VERSION ""

NS_ :

BS_:
BU_:
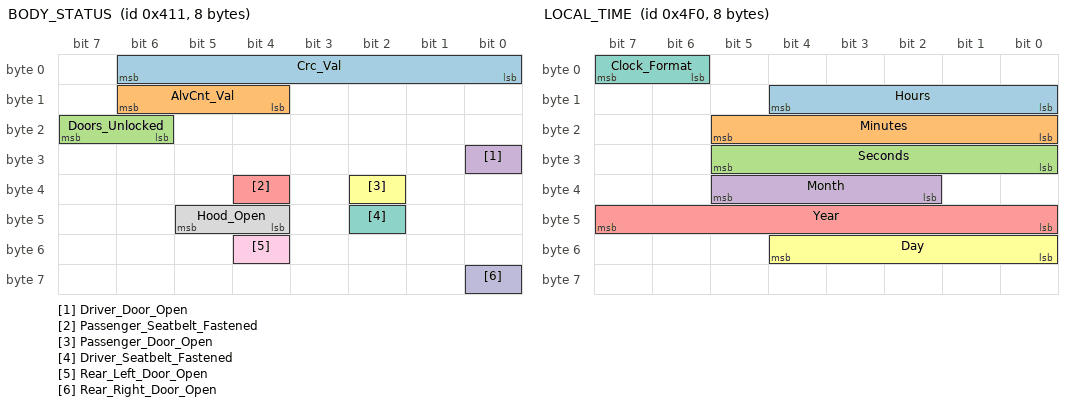
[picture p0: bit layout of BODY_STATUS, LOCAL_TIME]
BO_ 1041 BODY_STATUS: 8 Vector__XXX
   SG_ Crc_Val : 0|7@1+ (1,0) [0|127] "" Vector__XXX
   SG_ AlvCnt_Val : 12|3@1+ (1,0) [0|7] "" Vector__XXX
   SG_ Doors_Unlocked : 22|2@1+ (1,0) [0|3] "" Vector__XXX
   SG_ Driver_Door_Open : 24|1@1+ (1,0) [0|1] "" Vector__XXX
   SG_ Passenger_Seatbelt_Fastened : 36|1@1+ (1,0) [0|1] "" Vector__XXX
   SG_ Passenger_Door_Open : 34|1@1+ (1,0) [0|1] "" Vector__XXX
   SG_ Driver_Seatbelt_Fastened : 42|1@1+ (1,0) [0|1] "" Vector__XXX
   SG_ Hood_Open : 44|2@1+ (1,0) [0|3] "" Vector__XXX
   SG_ Rear_Left_Door_Open : 52|1@1+ (1,0) [0|1] "" Vector__XXX
   SG_ Rear_Right_Door_Open : 56|1@1+ (1,0) [0|1] "" Vector__XXX

BO_ 162 WHEEL_SPEEDS: 8 Vector__XXX
   SG_ Wheel_Speed_FL : 0|16@1+ (0.03125,0) [0|2047.97] "kph" Vector__XXX
   SG_ Wheel_Speed_FR : 16|16@1+ (0.03125,0) [0|2047.97] "kph" Vector__XXX
   SG_ Wheel_Speed_RL : 32|16@1+ (0.03125,0) [0|2047.97] "kph" Vector__XXX
   SG_ Wheel_Speed_RR : 48|16@1+ (0.03125,0) [0|2047.97] "kph" Vector__XXX

BO_ 428 CLUSTER_INFO_428: 8 Vector__XXX
   SG_ Speed_kph : 0|8@1+ (1,0) [0|255] "kph" Vector__XXX

BO_ 938 CHARGE_PORT_DOOR: 8 Vector__XXX
   SG_ Crc_Val : 0|12@1+ (1,0) [0|4095] "" Vector__XXX
   SG_ AlvCnt_Val : 12|8@1+ (1,0) [0|255] "" Vector__XXX
   SG_ Port_Open : 33|3@1+ (1,0) [0|7] "" Vector__XXX

BO_ 1044 TRUNK_STATUS: 8 Vector__XXX
   SG_ Crc_Val : 0|12@1+ (1,0) [0|4095] "" Vector__XXX
   SG_ AlvCnt_Val : 12|4@1+ (1,0) [0|15] "" Vector__XXX
   SG_ Trunk_Open : 24|6@1+ (1,0) [0|63] "" Vector__XXX

BO_ 763 BATTERY_INFO_763: 8 Vector__XXX
   SG_ Raw_BMS_State_Of_Charge : 32|8@1+ (0.25,0) [0|100] "%" Vector__XXX
   SG_ Cand_Volt_2FB_46 : 46|10@1+ (1,0) [0|1023] "V" Vector__XXX
   SG_ Cand_Volt_2FB_54 : 54|10@1+ (1,0) [0|1023] "V" Vector__XXX

BO_ 411 CHARGING_INFO: 8 Vector__XXX
   SG_ Charging_Current : 32|10@1+ (1,0) [0|1023] "A" Vector__XXX

BO_ 685 BMS_PRECOND_STATUS: 8 Vector__XXX
   SG_ Battery_Precond_State : 8|5@1+ (1,0) [0|31] "" Vector__XXX

BO_ 1261 NAV_PRECOND_STATUS: 8 Vector__XXX
   SG_ Precond_Request : 56|8@1+ (1,0) [0|255] "" Vector__XXX

BO_ 1042 REAR_LAMP_STATUS: 8 Vector__XXX
   SG_ Reverse_Lamp : 48|1@1+ (1,0) [0|1] "" Vector__XXX
   SG_ Brake_Lamp : 50|1@1+ (1,0) [0|1] "" Vector__XXX

BO_ 1077 POWER_CAN_STATUS: 8 Vector__XXX
   SG_ Crc_Val : 0|12@1+ (1,0) [0|4095] "" Vector__XXX
   SG_ AlvCnt_Val : 12|4@1+ (1,0) [0|15] "" Vector__XXX
   SG_ Power_State : 56|8@1+ (1,0) [0|255] "" Vector__XXX

BO_ 550 AMBIENT_TEMPERATURE: 8 Vector__XXX
   SG_ Outdoor_Temperature : 24|8@1+ (1,-40) [-40|215] "C" Vector__XXX

BO_ 551 ODOMETER: 8 Vector__XXX
   SG_ Odometer : 8|24@1+ (0.1,0) [0|1.67772e+06] "km" Vector__XXX
   SG_ Outdoor_Temperature_F : 50|8@1+ (0.5,-40) [-40|87.5] "F" Vector__XXX

BO_ 593 CLUSTER_WARNINGS: 8 Vector__XXX
   SG_ Crc_Val : 0|16@1+ (1,0) [0|65535] "" Vector__XXX
   SG_ AlvCnt_Val : 16|8@1+ (1,0) [0|255] "" Vector__XXX
   SG_ Rear_Defrost_State : 7|1@1+ (1,0) [0|1] "" Vector__XXX

BO_ 764 BATTERY_INFO_764: 8 Vector__XXX
   SG_ Battery_Current : 0|16@1- (0.1,0) [-3276.8|3276.7] "A" Vector__XXX
   SG_ Battery_Min_Temperature : 16|8@1- (1,0) [-128|127] "C" Vector__XXX
   SG_ Battery_Max_Temperature : 24|8@1- (1,0) [-128|127] "C" Vector__XXX
   SG_ Aux_Battery_Voltage : 48|8@1+ (0.1,0) [0|25.5] "V" Vector__XXX
   SG_ State_Of_Charge : 56|8@1+ (0.5,0) [0|100] "%" Vector__XXX

BO_ 1230 MEDIA_STATUS: 8 Vector__XXX
   SG_ Media_Source : 0|8@1+ (1,0) [0|255] "" Vector__XXX
   SG_ Media_Popup : 8|8@1+ (1,0) [0|255] "" Vector__XXX
   SG_ Track_Seconds : 32|8@1+ (1,0) [0|251] "s" Vector__XXX
   SG_ Track_Seconds_High : 40|8@1+ (1,0) [0|255] "" Vector__XXX

BO_ 843 LIGHT_STALK_STATUS: 8 Vector__XXX
   SG_ Headlight_Switch : 6|2@1+ (1,0) [0|3] "" Vector__XXX

BO_ 1096 STEERING_WHEEL_BUTTONS: 8 Vector__XXX
   SG_ Crc_Val : 0|8@1+ (1,0) [0|255] "" Vector__XXX
   SG_ AlvCnt_Val : 12|4@1+ (1,0) [0|15] "" Vector__XXX
   SG_ Steering_Wheel_Mode_Button : 22|2@1+ (1,0) [0|3] "" Vector__XXX
   SG_ Steering_Wheel_Speak_Button : 16|2@1+ (1,0) [0|3] "" Vector__XXX
   SG_ Steering_Wheel_Call_Button : 18|4@1+ (1,0) [0|15] "" Vector__XXX
   SG_ Steering_Wheel_Vol_Up_Button : 32|12@1+ (1,0) [0|4095] "" Vector__XXX
   SG_ Steering_Wheel_Vol_Down_Button : 30|2@1+ (1,0) [0|3] "" Vector__XXX
   SG_ Steering_Wheel_Mute_Button : 24|6@1+ (1,0) [0|63] "" Vector__XXX
   SG_ Steering_Wheel_Skip_Up_Button : 28|2@1+ (1,0) [0|3] "" Vector__XXX
   SG_ Steering_Wheel_Skip_Down_Button : 26|2@1+ (1,0) [0|3] "" Vector__XXX
   SG_ Steering_Wheel_Star_Button : 44|4@1+ (1,0) [0|15] "" Vector__XXX
   SG_ Steering_Wheel_Menu_Down_Button : 48|2@1+ (1,0) [0|3] "" Vector__XXX
   SG_ Steering_Wheel_Menu_Up_Button : 50|2@1+ (1,0) [0|3] "" Vector__XXX
   SG_ Steering_Wheel_Menu_Press_Button : 52|2@1+ (1,0) [0|3] "" Vector__XXX

BO_ 1141 PASSENGER_SEAT_HEATING: 8 Vector__XXX
   SG_ Passenger_Seat_Heating_Opt : 0|3@1+ (1,0) [0|7] "" Vector__XXX
   SG_ Passenger_Seat_Heating_Oper : 3|4@1+ (1,0) [0|15] "" Vector__XXX

BO_ 1174 DRIVER_SEAT_HEATING: 8 Vector__XXX
   SG_ Driver_Seat_Heating_Opt : 0|3@1+ (1,0) [0|7] "" Vector__XXX
   SG_ Driver_Seat_Heating_Oper : 3|4@1+ (1,0) [0|15] "" Vector__XXX

BO_ 706 MOTOR_TORQUE: 8 Vector__XXX
   SG_ Motor_Torque_Percent : 24|8@1- (1,0) [-128|127] "%" Vector__XXX

BO_ 795 CLIMATE_STATUS: 8 Vector__XXX
   SG_ Steering_Wheel_Heating_State : 7|1@1+ (1,0) [0|1] "" Vector__XXX
   SG_ Climate_Fan_Speed : 24|4@1+ (1,0) [0|15] "" Vector__XXX
   SG_ Climate_Airflow_Direction : 28|4@1+ (1,0) [0|15] "" Vector__XXX
   SG_ Climate_AC_State : 32|1@1+ (1,0) [0|1] "" Vector__XXX
   SG_ Climate_Recirculation_State : 34|1@1+ (1,0) [0|1] "" Vector__XXX

BO_ 896 CLIMATE_TEMPERATURE: 8 Vector__XXX
   SG_ Crc_Val : 0|16@1+ (1,0) [0|65535] "" Vector__XXX
   SG_ AlvCnt_Val : 16|8@1+ (1,0) [0|255] "" Vector__XXX
   SG_ Driver_Temp_C : 24|8@1+ (0.5,14) [14|32] "C" Vector__XXX
   SG_ Driver_Temp_F : 32|8@1+ (1,0) [0|255] "F" Vector__XXX
   SG_ Passenger_Temp_C : 40|8@1+ (0.5,14) [14|32] "C" Vector__XXX
   SG_ Passenger_Temp_F : 48|8@1+ (1,0) [0|255] "F" Vector__XXX

BO_ 782 CHARGING_POWER: 8 Vector__XXX
   SG_ Charging_Power_kW : 48|8@1+ (1,0) [0|255] "kW" Vector__XXX

BO_ 268 THERMAL_METRICS: 8 Vector__XXX
   SG_ Thermal_Metric_1 : 40|8@1+ (1,0) [0|255] "" Vector__XXX
   SG_ Thermal_Metric_2 : 48|8@1+ (1,0) [0|255] "" Vector__XXX

BO_ 567 BATTERY_INFO_567: 8 Vector__XXX
   SG_ Battery_Voltage : 40|16@1+ (0.1,0) [0|6553.5] "V" Vector__XXX

BO_ 54 DRIVE_MODE_STATUS: 8 Vector__XXX
   SG_ Ready : 28|1@1+ (1,0) [0|1] "" Vector__XXX
   SG_ Gear : 32|4@1+ (1,0) [0|15] "" Vector__XXX
   SG_ Drive_Mode : 58|3@1+ (1,0) [0|7] "" Vector__XXX

BO_ 695 CLUSTER_RANGE: 8 Vector__XXX
   SG_ Range : 0|10@1+ (1,0) [0|1023] "km" Vector__XXX

BO_ 818 CHARGE_TIME_ESTIMATE: 8 Vector__XXX
   SG_ Charge_Time_To_Limit : 0|16@1+ (1,0) [0|65535] "s" Vector__XXX
   SG_ Charge_Time_To_80 : 16|16@1+ (1,0) [0|65535] "s" Vector__XXX

BO_ 337 CHARGE_LIMITS: 8 Vector__XXX
   SG_ AC_Charge_Limit : 24|8@1+ (0.5,0) [0|127.5] "%" Vector__XXX
   SG_ DC_Charge_Limit : 32|8@1+ (0.5,0) [0|127.5] "%" Vector__XXX
   SG_ Battery_Max_Temperature_Copy : 56|8@1- (1,0) [-128|127] "C" Vector__XXX

BO_ 435 CABIN_TEMPERATURE: 8 Vector__XXX
   SG_ Cabin_Temperature : 40|8@1+ (0.5,-40) [-40|87.5] "C" Vector__XXX

BO_ 504 CHARGING_TIME: 8 Vector__XXX
   SG_ Charging_Time_To_Limit : 40|16@1+ (1,0) [0|65535] "min" Vector__XXX

BO_ 605 CANDIDATE_25D: 8 Vector__XXX
   SG_ Cand_Heater_Power_25D : 16|8@1+ (0.1,0) [0|25.5] "kW" Vector__XXX

BO_ 412 CHARGER_LIMITS: 8 Vector__XXX
   SG_ DC_Target_Voltage : 0|16@1+ (0.1,0) [0|6553.5] "V" Vector__XXX
   SG_ DC_Current_Limit : 16|8@1+ (0.1,0) [0|25.5] "A" Vector__XXX
   SG_ AC_Current_Limit : 32|8@1+ (0.1,0) [0|25.5] "A" Vector__XXX

BO_ 100 AUTO_HOLD_STATUS: 8 Vector__XXX
   SG_ Auto_Hold : 24|8@1+ (1,0) [0|255] "" Vector__XXX

BO_ 413 CHARGER_SESSION: 8 Vector__XXX
   SG_ Charger_Type : 16|8@1+ (1,0) [0|255] "" Vector__XXX
   SG_ DC_Sequence_Stage : 28|4@1+ (1,0) [0|15] "" Vector__XXX

BO_ 780 CHARGE_INLET: 8 Vector__XXX
   SG_ Proximity_Voltage : 32|8@1+ (0.1,0) [0|25.5] "V" Vector__XXX
   SG_ Plug_Connected : 40|1@1+ (1,0) [0|1] "" Vector__XXX

BO_ 806 CHARGING_STATUS: 8 Vector__XXX
   SG_ AC_Charger : 26|1@1+ (1,0) [0|1] "" Vector__XXX
   SG_ Charging : 32|1@1+ (1,0) [0|1] "" Vector__XXX

BO_ 603 CANDIDATE_25B: 8 Vector__XXX
   SG_ Cand_Curr_25B_50 : 50|10@1+ (1,0) [0|1023] "" Vector__XXX

BO_ 796 CANDIDATE_31C: 8 Vector__XXX
   SG_ Cand_Volt_31C_1 : 1|13@1+ (0.1,0) [0|819] "V" Vector__XXX

BO_ 338 BATTERY_TEMPERATURES_152: 8 Vector__XXX
   SG_ Battery_Min_Temperature_Copy : 0|8@1- (1,0) [-128|127] "C" Vector__XXX
   SG_ Cand_Battery_Temp_152_8 : 8|8@1- (1,0) [-128|127] "C" Vector__XXX
   SG_ Cand_Battery_Temp_152_16 : 16|8@1- (1,0) [-128|127] "C" Vector__XXX

BO_ 427 CLUSTER_DISPLAY_UNITS: 8 Vector__XXX
   SG_ Distance_Unit : 30|1@1+ (1,0) [0|1] "" Vector__XXX
   SG_ Display_Speed : 48|16@1+ (0.5,0) [0|32767.5] "" Vector__XXX

BO_ 738 REGEN_STATUS: 8 Vector__XXX
   SG_ Regen_Auto : 26|1@1+ (1,0) [0|1] "" Vector__XXX
   SG_ Regen_Level : 40|8@1+ (0.05,0) [0|12.75] "" Vector__XXX

BO_ 739 I_PEDAL_STATUS: 8 Vector__XXX
   SG_ I_Pedal : 57|1@1+ (1,0) [0|1] "" Vector__XXX

BO_ 929 TIRE_PRESSURES: 8 Vector__XXX
   SG_ Tire_Pressure_FL : 32|8@1+ (1,0) [0|255] "" Vector__XXX
   SG_ Tire_Pressure_FR : 40|8@1+ (1,0) [0|255] "" Vector__XXX
   SG_ Tire_Pressure_RL : 48|8@1+ (1,0) [0|255] "" Vector__XXX
   SG_ Tire_Pressure_RR : 56|8@1+ (1,0) [0|255] "" Vector__XXX

BO_ 930 TIRE_PRESSURE_UNIT: 8 Vector__XXX
   SG_ Tire_Pressure_Unit : 8|8@1+ (1,0) [0|255] "" Vector__XXX

BO_ 1264 LOCAL_TIME: 8 Vector__XXX
   SG_ Hours : 8|5@1+ (1,0) [0|23] "h" Vector__XXX
   SG_ Minutes : 16|6@1+ (1,0) [0|59] "min" Vector__XXX
   SG_ Seconds : 24|6@1+ (1,0) [0|59] "s" Vector__XXX
   SG_ Month : 34|4@1+ (1,0) [1|12] "" Vector__XXX
   SG_ Year : 40|8@1+ (1,2000) [2000|2255] "" Vector__XXX
   SG_ Day : 48|5@1+ (1,0) [1|31] "" Vector__XXX
   SG_ Clock_Format : 6|2@1+ (1,0) [0|3] "" Vector__XXX

BO_ 1259 LOCAL_TIME2: 8 Vector__XXX
   SG_ Weekday : 0|7@1+ (1,0) [0|127] "" Vector__XXX
   SG_ Hours : 11|5@1+ (1,0) [0|23] "h" Vector__XXX
   SG_ Minutes : 16|6@1+ (1,0) [0|59] "min" Vector__XXX
   SG_ Seconds : 24|6@1+ (1,0) [0|59] "s" Vector__XXX
   SG_ NEW_SIGNAL_3 : 39|1@0+ (1,0) [0|1] "" Vector__XXX

BO_ 1138 DISPLAY_SETTINGS_472: 8 Vector__XXX
   SG_ Efficiency_Unit : 38|2@1+ (1,0) [0|3] "" Vector__XXX

BO_ 56 POWER_MODE: 8 Vector__XXX
   SG_ Power_Mode : 0|4@1+ (1,0) [0|15] "" Vector__XXX

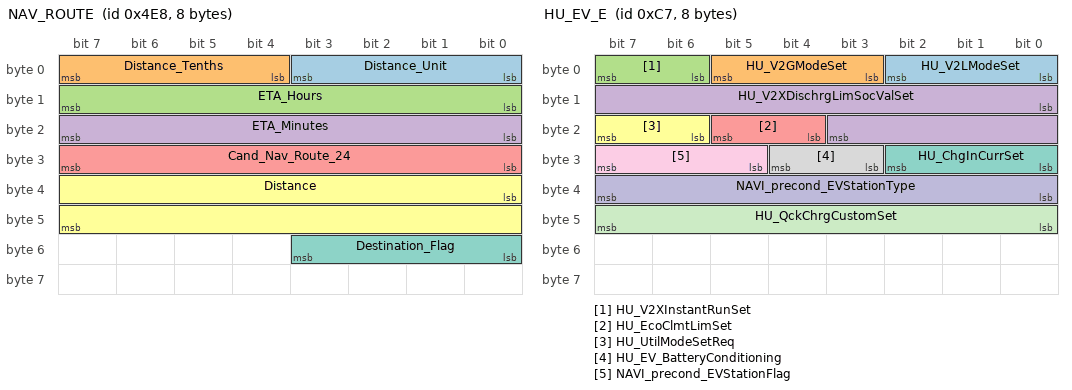
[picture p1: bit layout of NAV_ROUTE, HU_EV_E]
BO_ 1256 NAV_ROUTE: 8 Vector__XXX
   SG_ Distance_Unit : 0|4@1+ (1,0) [0|15] "" Vector__XXX
   SG_ Distance_Tenths : 4|4@1+ (1,0) [0|9] "" Vector__XXX
   SG_ ETA_Hours : 8|8@1+ (1,0) [0|23] "h" Vector__XXX
   SG_ ETA_Minutes : 16|8@1+ (1,0) [0|59] "min" Vector__XXX
   SG_ Cand_Nav_Route_24 : 24|8@1+ (1,0) [0|255] "" Vector__XXX
   SG_ Distance : 32|16@1+ (1,0) [0|65535] "" Vector__XXX
   SG_ Destination_Flag : 48|4@1+ (1,0) [0|15] "" Vector__XXX

BO_ 1228 NAV_GUIDANCE: 8 Vector__XXX
   SG_ Cand_Guidance_Type : 0|8@1+ (1,0) [0|255] "" Vector__XXX
   SG_ Cand_Compass_Heading : 24|8@1+ (1,0) [0|255] "" Vector__XXX

BO_ 418 CRUISE_STATUS: 8 Vector__XXX
   SG_ Cruise_State : 24|8@1+ (1,0) [0|255] "" Vector__XXX
   SG_ Cruise_Set_Speed : 32|8@1+ (1,0) [0|255] "kph" Vector__XXX

BO_ 1255 SPEED_LIMIT_4E7: 8 Vector__XXX
   SG_ Cand_Displayed_Speed_Limit : 56|8@1+ (1,0) [0|255] "kph" Vector__XXX

BO_ 1600 LANE_GUIDANCE: 8 Vector__XXX
   SG_ Cand_Junction_Distance : 0|16@1+ (1,0) [0|65535] "m" Vector__XXX
   SG_ Cand_Route_Active_640 : 56|8@1+ (1,0) [0|255] "" Vector__XXX

BO_ 199 HU_EV_E: 8 Vector__XXX
   SG_ HU_V2LModeSet : 0|3@1+ (1,0) [0|7] "" Vector__XXX
   SG_ HU_V2GModeSet : 3|3@1+ (1,0) [0|7] "" Vector__XXX
   SG_ HU_V2XInstantRunSet : 6|2@1+ (1,0) [0|3] "" Vector__XXX
   SG_ HU_V2XDischrgLimSocValSet : 8|12@1+ (1,0) [0|4095] "" Vector__XXX
   SG_ HU_EcoClmtLimSet : 20|2@1+ (1,0) [0|3] "" Vector__XXX
   SG_ HU_UtilModeSetReq : 22|2@1+ (1,0) [0|3] "" Vector__XXX
   SG_ HU_ChgInCurrSet : 24|3@1+ (1,0) [0|7] "" Vector__XXX
   SG_ HU_EV_BatteryConditioning : 27|2@1+ (1,0) [0|3] "" Vector__XXX
   SG_ NAVI_precond_EVStationFlag : 29|3@1+ (1,0) [0|7] "" Vector__XXX
   SG_ NAVI_precond_EVStationType : 32|8@1+ (1,0) [0|255] "" Vector__XXX
   SG_ HU_QckChrgCustomSet : 40|8@1+ (1,0) [0|255] "" Vector__XXX

BO_ 255 BCM_20_200ms: 8 Vector__XXX
   SG_ BCM_Crc20Val : 0|12@1+ (1,0) [0|4095] "" Vector__XXX
   SG_ BCM_AlvCnt20Val : 12|37@1+ (1,0) [0|1.37439e+11] "" Vector__XXX
   SG_ BCM_SafetyWdwOptTyp2 : 49|7@1+ (1,0) [0|127] "" Vector__XXX

BO_ 353 CCNC_0x161: 32 Vector__XXX
   SG_ CHECKSUM : 0|16@1+ (1,0) [0|65535] "" Vector__XXX
   SG_ COUNTER : 16|8@1+ (1,0) [0|255] "" Vector__XXX
   SG_ FCA_ICON : 24|3@1+ (1,0) [0|7] "" Vector__XXX
   SG_ FCA_ALT_ICON : 27|3@1+ (1,0) [0|7] "" Vector__XXX
   SG_ LKA_ICON : 30|3@1+ (1,0) [0|3] "" Vector__XXX
   SG_ HBA_ICON : 33|3@1+ (1,0) [0|7] "" Vector__XXX
   SG_ ZEROS_1 : 36|4@1+ (1,0) [0|15] "" Vector__XXX
   SG_ ZEROS_2 : 40|2@1+ (1,0) [0|3] "" Vector__XXX
   SG_ FCA_IMAGE : 42|3@1+ (1,0) [0|7] "" Vector__XXX
   SG_ ZEROS_3 : 45|3@1+ (1,0) [0|7] "" Vector__XXX
   SG_ ZEROS_4 : 48|3@1+ (1,0) [0|7] "" Vector__XXX
   SG_ BCA_LEFT : 51|3@1+ (1,0) [0|7] "" Vector__XXX
   SG_ BCA_RIGHT : 54|3@1+ (1,0) [0|7] "" Vector__XXX
   SG_ LCA_LEFT_ARROW : 57|3@1+ (1,0) [0|7] "" Vector__XXX
   SG_ LCA_RIGHT_ARROW : 60|3@1+ (1,0) [0|7] "" Vector__XXX
   SG_ ZEROS_5 : 63|1@0+ (1,0) [0|1] "" Vector__XXX
   SG_ CENTERLINE : 64|2@1+ (1,0) [0|3] "" Vector__XXX
   SG_ TARGET : 66|3@1+ (1,0) [0|7] "" Vector__XXX
   SG_ TARGET_DISTANCE : 69|11@1+ (0.1,0) [0|204.7] "m" Vector__XXX
   SG_ LANELINE_LEFT : 80|4@1+ (1,0) [0|15] "" Vector__XXX
   SG_ LANELINE_LEFT_POSITION : 84|6@1+ (1,0) [0|15] "" Vector__XXX
   SG_ LANELINE_RIGHT : 90|4@1+ (1,0) [0|15] "" Vector__XXX
   SG_ LANELINE_RIGHT_POSITION : 94|6@1+ (1,0) [0|3] "" Vector__XXX
   SG_ LANELINE_CURVATURE : 100|5@1- (1,15) [0|31] "" Vector__XXX
   SG_ LANE_HIGHLIGHT : 105|4@1+ (1,0) [0|15] "" Vector__XXX
   SG_ LANE_HIGHLIGHT_DISTANCE : 109|11@1+ (0.1,0) [0|204.7] "m" Vector__XXX
   SG_ LANE_LEFT : 120|3@1+ (1,0) [0|7] "" Vector__XXX
   SG_ LANE_RIGHT : 123|3@1+ (1,0) [0|7] "" Vector__XXX
   SG_ LANE_ZOOM : 126|2@1+ (1,0) [0|3] "" Vector__XXX
   SG_ ALERTS_1 : 128|6@1+ (1,0) [0|63] "" Vector__XXX
   SG_ ALERTS_2 : 134|5@1+ (1,0) [0|3] "" Vector__XXX
   SG_ ALERTS_3 : 139|5@1+ (1,0) [0|15] "" Vector__XXX
   SG_ ALERTS_4 : 144|8@1+ (1,0) [0|255] "" Vector__XXX
   SG_ ALERTS_5 : 152|5@1+ (1,0) [0|7] "" Vector__XXX
   SG_ MUTE : 157|3@1+ (1,0) [0|7] "" Vector__XXX
   SG_ SOUNDS_1 : 160|4@1+ (1,0) [0|3] "" Vector__XXX
   SG_ SOUNDS_2 : 164|4@1+ (1,0) [0|3] "" Vector__XXX
   SG_ SOUNDS_3 : 168|4@1+ (1,0) [0|15] "" Vector__XXX
   SG_ SOUNDS_4 : 172|3@1+ (1,0) [0|7] "" Vector__XXX
   SG_ ZEROS_6 : 175|1@0+ (1,0) [0|1] "" Vector__XXX
   SG_ ZEROS_7 : 176|5@1+ (1,0) [0|31] "" Vector__XXX
   SG_ SETSPEED_HUD : 181|3@1+ (1,0) [0|3] "" Vector__XXX
   SG_ DISTANCE_LEAD : 184|5@1+ (1,0) [0|31] "" Vector__XXX
   SG_ DISTANCE_CAR : 189|3@1+ (1,0) [0|7] "" Vector__XXX
   SG_ DISTANCE_SPACING : 192|4@1+ (1,0) [0|15] "" Vector__XXX
   SG_ DISTANCE : 196|4@1+ (1,0) [0|7] "" Vector__XXX
   SG_ SETSPEED_SPEED : 200|8@1+ (1,0) [0|255] "" Vector__XXX
   SG_ SETSPEED : 208|4@1+ (1,0) [0|3] "" Vector__XXX
   SG_ HDA_ICON : 212|4@1+ (1,0) [0|3] "" Vector__XXX
   SG_ SLA_ICON : 216|4@1+ (1,0) [0|15] "" Vector__XXX
   SG_ NAV_ICON : 220|4@1+ (1,0) [0|3] "" Vector__XXX
   SG_ LFA_ICON : 224|4@1+ (1,0) [0|3] "" Vector__XXX
   SG_ LCA_LEFT_ICON : 228|4@1+ (1,0) [0|15] "" Vector__XXX
   SG_ LCA_RIGHT_ICON : 232|4@1+ (1,0) [0|15] "" Vector__XXX
   SG_ BACKGROUND : 236|4@1+ (1,0) [0|15] "" Vector__XXX
   SG_ DAW_ICON : 240|3@1+ (1,0) [0|7] "" Vector__XXX
   SG_ CAR_CIRCLE : 243|3@1+ (1,0) [0|7] "" Vector__XXX
   SG_ ZEROS_8 : 246|2@1+ (1,0) [0|3] "" Vector__XXX
   SG_ ZEROS_9 : 248|8@1+ (1,0) [0|255] "" Vector__XXX

BO_ 354 CCNC_0x162: 32 Vector__XXX
   SG_ CHECKSUM : 0|16@1+ (1,0) [0|65535] "" Vector__XXX
   SG_ COUNTER : 16|8@1+ (1,0) [0|255] "" Vector__XXX
   SG_ COUNTRY : 24|4@1+ (1,0) [0|7] "" Vector__XXX
   SG_ SPEEDLIMIT_FLASH : 28|4@1+ (1,0) [0|15] "" Vector__XXX
   SG_ SPEEDLIMIT : 32|8@1+ (1,0) [0|255] "" Vector__XXX
   SG_ SIGNS : 40|8@1+ (1,0) [0|15] "" Vector__XXX
   SG_ SPEEDLIMIT_WEATHER : 48|4@1+ (1,0) [0|15] "" Vector__XXX
   SG_ VIBRATE : 52|3@1+ (1,0) [0|7] "" Vector__XXX
   SG_ ZEROS_1 : 55|1@0+ (1,0) [0|1] "" Vector__XXX
   SG_ ZEROS_2 : 56|8@1+ (1,0) [0|255] "" Vector__XXX
   SG_ LEAD : 64|5@1+ (1,0) [0|31] "" Vector__XXX
   SG_ LEAD_DISTANCE : 69|11@1+ (0.1,0) [0|204.7] "m" Vector__XXX
   SG_ LEAD_LATERAL : 80|7@1+ (0.1,0) [0|127] "m" Vector__XXX
   SG_ ZEROS_3 : 87|1@0+ (1,0) [0|1] "" Vector__XXX
   SG_ LEAD_ALT : 88|5@1+ (1,0) [0|31] "" Vector__XXX
   SG_ LEAD_ALT_DISTANCE : 93|11@1+ (0.1,0) [0|204.7] "m" Vector__XXX
   SG_ LEAD_ALT_LATERAL : 104|7@1+ (0.1,0) [0|127] "m" Vector__XXX
   SG_ ZEROS_4 : 111|1@0+ (1,0) [0|1] "" Vector__XXX
   SG_ LEAD_LEFT : 112|5@1+ (1,0) [0|31] "" Vector__XXX
   SG_ LEAD_LEFT_DISTANCE : 117|11@1+ (0.1,0) [0|204.7] "m" Vector__XXX
   SG_ LEAD_LEFT_LATERAL : 128|7@1+ (0.1,0) [0|127] "m" Vector__XXX
   SG_ ZEROS_5 : 135|1@0+ (1,0) [0|1] "" Vector__XXX
   SG_ LEAD_RIGHT : 136|5@1+ (1,0) [0|31] "" Vector__XXX
   SG_ LEAD_RIGHT_DISTANCE : 141|11@1+ (0.1,0) [0|204.7] "m" Vector__XXX
   SG_ LEAD_RIGHT_LATERAL : 152|7@1+ (0.1,0) [0|127] "m" Vector__XXX
   SG_ ZEROS_6 : 159|1@0+ (1,0) [0|1] "" Vector__XXX
   SG_ ZEROS_7 : 162|3@0+ (1,0) [0|7] "" Vector__XXX
   SG_ LEAD_LEFT_REAR_STATUS : 167|5@0+ (1,0) [0|31] "" Vector__XXX
   SG_ LEAD_LEFT_REAR_DISTANCE : 175|8@0+ (0.1,0) [0|255] "m" Vector__XXX
   SG_ LEAD_LEFT_REAR_LATERAL : 182|7@0+ (0.1,0) [0|127] "m" Vector__XXX
   SG_ ZEROS_8 : 183|1@0+ (1,0) [0|1] "" Vector__XXX
   SG_ ZEROS_9 : 191|8@0+ (1,0) [0|255] "" Vector__XXX
   SG_ LEAD_RIGHT_REAR_STATUS : 196|5@0+ (1,0) [0|31] "" Vector__XXX
   SG_ LEAD_RIGHT_REAR_DISTANCE : 197|8@1+ (0.1,0) [0|255] "m" Vector__XXX
   SG_ LEAD_RIGHT_REAR_LATERAL : 205|7@1+ (0.1,0) [0|127] "m" Vector__XXX
   SG_ ZEROS_10 : 212|1@0+ (1,0) [0|1] "" Vector__XXX
   SG_ FAULT_FSS : 213|3@1+ (1,0) [0|7] "" Vector__XXX
   SG_ FAULT_FCA : 216|3@1+ (1,0) [0|7] "" Vector__XXX
   SG_ FAULT_LSS : 219|3@1+ (1,0) [0|7] "" Vector__XXX
   SG_ FAULT_SLA : 222|3@1+ (1,0) [0|7] "" Vector__XXX
   SG_ FAULT_DAW : 225|3@1+ (1,0) [0|7] "" Vector__XXX
   SG_ FAULT_HBA : 228|3@1+ (1,0) [0|7] "" Vector__XXX
   SG_ FAULT_SCC : 231|3@1+ (1,0) [0|7] "" Vector__XXX
   SG_ FAULT_LFA : 234|3@1+ (1,0) [0|7] "" Vector__XXX
   SG_ FAULT_HDA : 237|3@1+ (1,0) [0|7] "" Vector__XXX
   SG_ FAULT_LCA : 240|3@1+ (1,0) [0|7] "" Vector__XXX
   SG_ FAULT_HDP : 243|3@1+ (1,0) [0|7] "" Vector__XXX
   SG_ FAULT_DAS : 246|3@1+ (1,0) [0|7] "" Vector__XXX
   SG_ FAULT_ESS : 249|3@1+ (1,0) [0|7] "" Vector__XXX
   SG_ ZEROS_11 : 252|4@1+ (1,0) [0|15] "" Vector__XXX

BO_ 438 CAM_0x1b6: 32 Vector__XXX
   SG_ CHECKSUM : 0|16@1+ (1,0) [0|65535] "" Vector__XXX
   SG_ COUNTER : 16|8@1+ (1,0) [0|255] "" Vector__XXX

BO_ 439 CAM_0x1b7: 32 Vector__XXX
   SG_ CHECKSUM : 0|16@1+ (1,0) [0|65535] "" Vector__XXX
   SG_ COUNTER : 16|8@1+ (1,0) [0|255] "" Vector__XXX

BO_ 440 CAM_0x1b8: 32 Vector__XXX
   SG_ CHECKSUM : 0|16@1+ (1,0) [0|65535] "" Vector__XXX
   SG_ COUNTER : 16|8@1+ (1,0) [0|255] "" Vector__XXX

BO_ 441 CAM_0x1b9: 32 Vector__XXX
   SG_ CHECKSUM : 0|16@1+ (1,0) [0|65535] "" Vector__XXX
   SG_ COUNTER : 16|8@1+ (1,0) [0|255] "" Vector__XXX

BO_ 507 CAM_0x1fb: 32 Vector__XXX
   SG_ CHECKSUM : 0|16@1+ (1,0) [0|65535] "" Vector__XXX
   SG_ COUNTER : 16|8@1+ (1,0) [0|255] "" Vector__XXX

BO_ 599 RRPSM_02_00ms: 8 Vector__XXX
   SG_ RR_SHVU_SeatOptSta : 0|3@1+ (1,0) [0|7] "" Vector__XXX
   SG_ C_RH_Folding_SW : 2|2@1+ (1,0) [0|3] "" Vector__XXX
   SG_ RR_SHVU_SeatHtOperSta : 3|5@1+ (1,0) [0|31] "" Vector__XXX
   SG_ C_LH_Unfolding_SW : 4|2@1+ (1,0) [0|3] "" Vector__XXX
   SG_ C_LH_Folding_SW : 6|2@1+ (1,0) [0|3] "" Vector__XXX
   SG_ RRPSM_RearModeWngDis : 8|6@1+ (1,0) [0|63] "" Vector__XXX
   SG_ RRIMS_AMPBzrReq : 14|2@1+ (1,0) [0|3] "" Vector__XXX

BO_ 689 ADAS_CMD_34_100ms: 10 Vector__XXX
   SG_ ADAS_CMD_Crc34Val : 0|16@1+ (1,0) [0|65535] "" Vector__XXX
   SG_ ADAS_CMD_AlvCnt34Val : 16|8@1+ (1,0) [0|255] "" Vector__XXX
   SG_ HDP_RDD_WarnSta : 24|3@1+ (1,0) [0|7] "" Vector__XXX
   SG_ HDP_RDD_LongAsstCtrlSta : 27|2@1+ (1,0) [0|3] "" Vector__XXX
   SG_ HDP_RDD_HzrdLmpReqSta : 29|3@1+ (1,0) [0|7] "" Vector__XXX
   SG_ HDP_RDD_ACIActvDispSta : 32|40@1+ (1,0) [0|1099511627775] "" Vector__XXX
   SG_ HDP_RDD_EMStbltActvReqSta : 72|8@1+ (1,0) [0|255] "" Vector__XXX

BO_ 827 TP_HU_IAU: 8 Vector__XXX
   SG_ TP_HU_IAU_Byte0 : 0|8@1+ (1,0) [0|255] "" Vector__XXX
   SG_ TP_HU_IAU_Byte1 : 8|8@1+ (1,0) [0|255] "" Vector__XXX
   SG_ TP_HU_IAU_Byte2 : 16|8@1+ (1,0) [0|255] "" Vector__XXX
   SG_ TP_HU_IAU_Byte3 : 24|8@1+ (1,0) [0|255] "" Vector__XXX
   SG_ TP_HU_IAU_Byte4 : 32|8@1+ (1,0) [0|255] "" Vector__XXX
   SG_ TP_HU_IAU_Byte5 : 40|8@1+ (1,0) [0|255] "" Vector__XXX
   SG_ TP_HU_IAU_Byte6 : 48|8@1+ (1,0) [0|255] "" Vector__XXX
   SG_ TP_HU_IAU_Byte7 : 56|8@1+ (1,0) [0|255] "" Vector__XXX

BO_ 828 TP_IAU_HU: 8 Vector__XXX
   SG_ TP_IAU_HU_Byte0 : 0|8@1+ (1,0) [0|255] "" Vector__XXX
   SG_ TP_IAU_HU_Byte1 : 8|8@1+ (1,0) [0|255] "" Vector__XXX
   SG_ TP_IAU_HU_Byte2 : 16|8@1+ (1,0) [0|255] "" Vector__XXX
   SG_ TP_IAU_HU_Byte3 : 24|8@1+ (1,0) [0|255] "" Vector__XXX
   SG_ TP_IAU_HU_Byte4 : 32|8@1+ (1,0) [0|255] "" Vector__XXX
   SG_ TP_IAU_HU_Byte5 : 40|8@1+ (1,0) [0|255] "" Vector__XXX
   SG_ TP_IAU_HU_Byte6 : 48|8@1+ (1,0) [0|255] "" Vector__XXX
   SG_ TP_IAU_HU_Byte7 : 56|8@1+ (1,0) [0|255] "" Vector__XXX

BO_ 895 GATEWAY_STS_100ms: 8 Vector__XXX
   SG_ GATEWAY_HS_D_STS : 22|2@1+ (1,0) [0|3] "" Vector__XXX

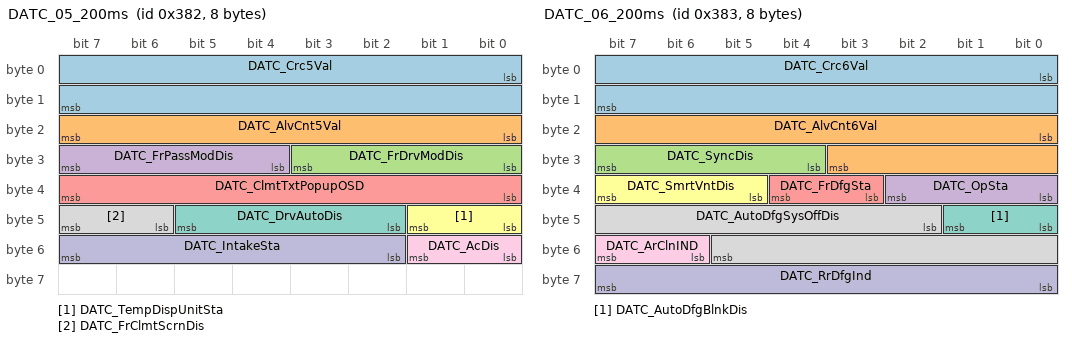
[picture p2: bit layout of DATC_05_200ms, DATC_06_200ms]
BO_ 898 DATC_05_200ms: 8 Vector__XXX
   SG_ DATC_Crc5Val : 0|16@1+ (1,0) [0|65535] "" Vector__XXX
   SG_ DATC_AlvCnt5Val : 16|8@1+ (1,0) [0|255] "" Vector__XXX
   SG_ DATC_FrDrvModDis : 24|4@1+ (1,0) [0|15] "" Vector__XXX
   SG_ DATC_FrPassModDis : 28|4@1+ (1,0) [0|15] "" Vector__XXX
   SG_ DATC_ClmtTxtPopupOSD : 32|8@1+ (1,0) [0|255] "" Vector__XXX
   SG_ DATC_TempDispUnitSta : 40|2@1+ (1,0) [0|3] "" Vector__XXX
   SG_ DATC_DrvAutoDis : 42|4@1+ (1,0) [0|15] "" Vector__XXX
   SG_ DATC_FrClmtScrnDis : 46|2@1+ (1,0) [0|3] "" Vector__XXX
   SG_ DATC_AcDis : 48|2@1+ (1,0) [0|3] "" Vector__XXX
   SG_ DATC_IntakeSta : 50|6@1+ (1,0) [0|63] "" Vector__XXX

BO_ 899 DATC_06_200ms: 8 Vector__XXX
   SG_ DATC_Crc6Val : 0|16@1+ (1,0) [0|65535] "" Vector__XXX
   SG_ DATC_AlvCnt6Val : 16|12@1+ (1,0) [0|4095] "" Vector__XXX
   SG_ DATC_SyncDis : 28|4@1+ (1,0) [0|15] "" Vector__XXX
   SG_ DATC_OpSta : 32|3@1+ (1,0) [0|7] "" Vector__XXX
   SG_ DATC_FrDfgSta : 35|2@1+ (1,0) [0|3] "" Vector__XXX
   SG_ DATC_SmrtVntDis : 37|3@1+ (1,0) [0|7] "" Vector__XXX
   SG_ DATC_AutoDfgBlnkDis : 40|2@1+ (1,0) [0|3] "" Vector__XXX
   SG_ DATC_AutoDfgSysOffDis : 42|12@1+ (1,0) [0|4095] "" Vector__XXX
   SG_ DATC_ArClnIND : 54|2@1+ (1,0) [0|3] "" Vector__XXX
   SG_ DATC_RrDfgInd : 56|8@1+ (1,0) [0|255] "" Vector__XXX

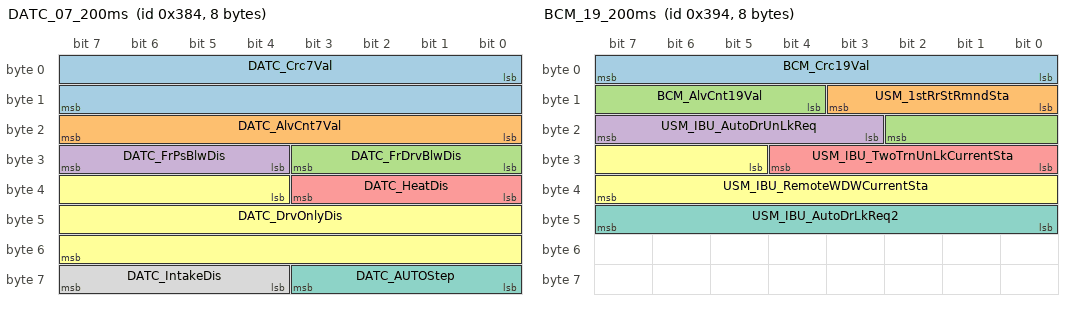
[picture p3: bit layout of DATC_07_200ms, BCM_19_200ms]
BO_ 900 DATC_07_200ms: 8 Vector__XXX
   SG_ DATC_Crc7Val : 0|16@1+ (1,0) [0|65535] "" Vector__XXX
   SG_ DATC_AlvCnt7Val : 16|8@1+ (1,0) [0|255] "" Vector__XXX
   SG_ DATC_FrDrvBlwDis : 24|4@1+ (1,0) [0|15] "" Vector__XXX
   SG_ DATC_FrPsBlwDis : 28|4@1+ (1,0) [0|15] "" Vector__XXX
   SG_ DATC_HeatDis : 32|4@1+ (1,0) [0|15] "" Vector__XXX
   SG_ DATC_DrvOnlyDis : 36|20@1+ (1,0) [0|1.04858e+06] "" Vector__XXX
   SG_ DATC_AUTOStep : 56|4@1+ (1,0) [0|15] "" Vector__XXX
   SG_ DATC_IntakeDis : 60|4@1+ (1,0) [0|15] "" Vector__XXX

BO_ 902 PSM_02_200ms: 8 Vector__XXX
   SG_ PSM_DrvStSldFwdDis : 0|2@1+ (1,0) [0|3] "" Vector__XXX
   SG_ PSM_DrvStSldBckwdDis : 2|2@1+ (1,0) [0|3] "" Vector__XXX
   SG_ PSM_DrvStReclneFwdDis : 4|2@1+ (1,0) [0|3] "" Vector__XXX
   SG_ PSM_DrvStReclneBckwdDis : 6|2@1+ (1,0) [0|3] "" Vector__XXX
   SG_ PSM_IMSOptTyp : 8|16@1+ (1,0) [0|65535] "" Vector__XXX
   SG_ PSM_DrvStTiltDnDis : 10|2@1+ (1,0) [0|3] "" Vector__XXX
   SG_ PSM_DrvStHghtUpDis : 12|2@1+ (1,0) [0|3] "" Vector__XXX
   SG_ PSM_DrvStHghtDnDis : 14|2@1+ (1,0) [0|3] "" Vector__XXX
   SG_ PSM_DrvStCushExtBckwdDis : 16|2@1+ (1,0) [0|3] "" Vector__XXX
   SG_ PSM_DrvStCushExtFwdDis : 18|2@1+ (1,0) [0|3] "" Vector__XXX
   SG_ PSM_DrvStHdRstUpDis : 20|2@1+ (1,0) [0|3] "" Vector__XXX
   SG_ PSM_DrvStHdRstDnDis : 22|2@1+ (1,0) [0|3] "" Vector__XXX
   SG_ SmrtIMS_StatureRspVal : 24|4@1+ (1,0) [0|15] "" Vector__XXX
   SG_ PSM_DrvStHdRstBckwdDis : 26|6@1+ (1,0) [0|63] "" Vector__XXX
   SG_ SmrtIMS_SeatedHghtRspVal : 28|4@1+ (1,0) [0|15] "" Vector__XXX
   SG_ SmrtIMS_WghtRspVal : 32|4@1+ (1,0) [0|15] "" Vector__XXX
   SG_ PSM_DrvStLmbrLoDis : 34|2@1+ (1,0) [0|3] "" Vector__XXX
   SG_ SmartIMS_DisReq : 36|4@1+ (1,0) [0|15] "" Vector__XXX
   SG_ PSM_DrvStLmbrUpDis : 38|2@1+ (1,0) [0|3] "" Vector__XXX
   SG_ SmrtIMS_ExitSta : 40|3@1+ (1,0) [0|7] "" Vector__XXX
   SG_ PSM_DrvStBlstrInfDis : 42|6@1+ (1,0) [0|63] "" Vector__XXX
   SG_ PSM_DrvStRlxTiltUpDis : 43|2@1+ (1,0) [0|3] "" Vector__XXX
   SG_ PSM_DrvStRlxTiltDnDis : 45|2@1+ (1,0) [0|3] "" Vector__XXX
   SG_ PSM_DrvStLegUpDis : 47|2@1+ (1,0) [0|3] "" Vector__XXX
   SG_ PSM_DrvStLegDnDis : 49|7@1+ (1,0) [0|127] "" Vector__XXX

BO_ 903 APSU_03_200ms_APSU: 8 Vector__XXX
   SG_ PSM_LmbrSigSrcTyp : 44|4@1+ (1,0) [0|15] "" Vector__XXX

BO_ 904 PSM_04_200ms: 8 Vector__XXX
   SG_ PSM_DrvReclinePosition : 0|8@1+ (1,0) [0|255] "" Vector__XXX
   SG_ PSM_EsyAcsGetOnSta : 8|2@1+ (1,0) [0|3] "" Vector__XXX
   SG_ PSM_EsyAcsGetOffSta : 10|2@1+ (1,0) [0|3] "" Vector__XXX
   SG_ PSM_EsyAcsStpSta : 12|4@1+ (1,0) [0|15] "" Vector__XXX
   SG_ RRPSS_L_StSldFwdMvBtn : 16|0@1+ (1,0) [0|0] "" Vector__XXX
   SG_ RRPSS_L_StSldBwdMvBtn : 18|0@1+ (1,0) [0|0] "" Vector__XXX
   SG_ RRPSS_L_StRclFwdMvBtn : 20|0@1+ (1,0) [0|0] "" Vector__XXX
   SG_ RRPSS_L_StRclBwdMvBtn : 22|0@1+ (1,0) [0|0] "" Vector__XXX
   SG_ PSM_SWVerMinor1 : 24|8@1+ (1,0) [0|255] "" Vector__XXX
   SG_ RRPSS_L_StTltUpMvBtn : 28|0@1+ (1,0) [0|0] "" Vector__XXX
   SG_ RRPSS_L_StTltDnMvBtn : 30|0@1+ (1,0) [0|0] "" Vector__XXX
   SG_ RRPSS_L_StHRestUpMvBtn : 32|0@1+ (1,0) [0|0] "" Vector__XXX
   SG_ RRPSS_L_StHRestDnMvBtn : 34|0@1+ (1,0) [0|0] "" Vector__XXX
   SG_ RRPSS_L_StHRestFwdMvBtn : 36|0@1+ (1,0) [0|0] "" Vector__XXX
   SG_ RRPSS_L_StHRestBwdMvBtn : 38|0@1+ (1,0) [0|0] "" Vector__XXX
   SG_ RRPSS_L_StLegRestUpBtn : 40|0@1+ (1,0) [0|0] "" Vector__XXX
   SG_ RRPSS_L_StLegRestDnBtn : 42|0@1+ (1,0) [0|0] "" Vector__XXX
   SG_ PSM_DrvHeightPosition : 48|8@1+ (1,0) [0|255] "" Vector__XXX
   SG_ PSM_DrvSlidePosition : 56|8@1+ (1,0) [0|255] "" Vector__XXX

BO_ 916 BCM_19_200ms: 8 Vector__XXX
   SG_ BCM_Crc19Val : 0|8@1+ (1,0) [0|255] "" Vector__XXX
   SG_ USM_1stRrStRmndSta : 8|4@1+ (1,0) [0|15] "" Vector__XXX
   SG_ BCM_AlvCnt19Val : 12|7@1+ (1,0) [0|127] "" Vector__XXX
   SG_ USM_IBU_AutoDrUnLkReq : 19|5@1+ (1,0) [0|31] "" Vector__XXX
   SG_ USM_IBU_TwoTrnUnLkCurrentSta : 24|5@1+ (1,0) [0|31] "" Vector__XXX
   SG_ USM_IBU_RemoteWDWCurrentSta : 29|11@1+ (1,0) [0|2047] "" Vector__XXX
   SG_ USM_IBU_AutoDrLkReq2 : 40|8@1+ (1,0) [0|255] "" Vector__XXX

BO_ 942 HU_AMP_E_942: 8 Vector__XXX
   SG_ AMP_Beep1VolumeStep_DATC : 0|8@1+ (1,0) [0|255] "" Vector__XXX
   SG_ AMP_SPDIF_OutputCh_Select : 8|16@1+ (1,0) [0|65535] "" Vector__XXX
   SG_ AMP_Analog_OutputCh_Select : 24|16@1+ (1,0) [0|65535] "" Vector__XXX
   SG_ AMP_Beep1_OutputCh_Select : 40|16@1+ (1,0) [0|65535] "" Vector__XXX
   SG_ AMP_Beep1KBDVolumeStep : 56|8@1+ (1,0) [0|255] "" Vector__XXX

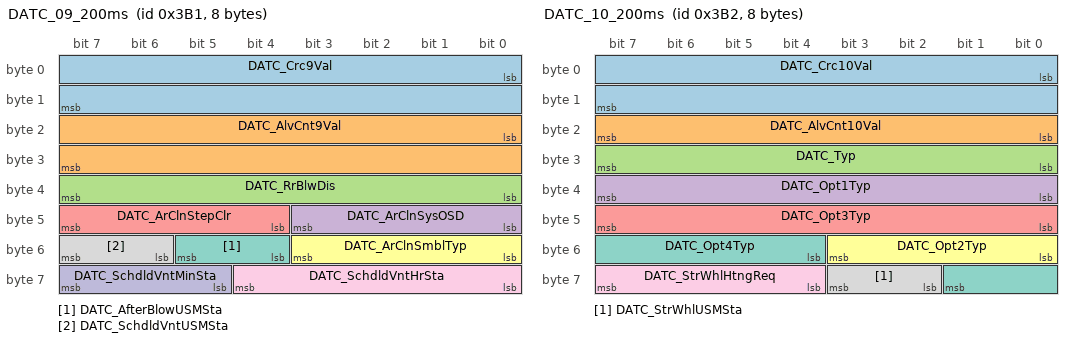
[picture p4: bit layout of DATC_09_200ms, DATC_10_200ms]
BO_ 945 DATC_09_200ms: 8 Vector__XXX
   SG_ DATC_Crc9Val : 0|16@1+ (1,0) [0|65535] "" Vector__XXX
   SG_ DATC_AlvCnt9Val : 16|16@1+ (1,0) [0|65535] "" Vector__XXX
   SG_ DATC_RrBlwDis : 32|8@1+ (1,0) [0|255] "" Vector__XXX
   SG_ DATC_ArClnSysOSD : 40|4@1+ (1,0) [0|15] "" Vector__XXX
   SG_ DATC_ArClnStepClr : 44|4@1+ (1,0) [0|15] "" Vector__XXX
   SG_ DATC_ArClnSmblTyp : 48|4@1+ (1,0) [0|15] "" Vector__XXX
   SG_ DATC_AfterBlowUSMSta : 52|2@1+ (1,0) [0|3] "" Vector__XXX
   SG_ DATC_SchdldVntUSMSta : 54|2@1+ (1,0) [0|3] "" Vector__XXX
   SG_ DATC_SchdldVntHrSta : 56|5@1+ (1,0) [0|31] "" Vector__XXX
   SG_ DATC_SchdldVntMinSta : 61|3@1+ (1,0) [0|7] "" Vector__XXX

BO_ 946 DATC_10_200ms: 8 Vector__XXX
   SG_ DATC_Crc10Val : 0|16@1+ (1,0) [0|65535] "" Vector__XXX
   SG_ DATC_AlvCnt10Val : 16|8@1+ (1,0) [0|255] "" Vector__XXX
   SG_ DATC_Typ : 24|8@1+ (1,0) [0|255] "" Vector__XXX
   SG_ DATC_Opt1Typ : 32|8@1+ (1,0) [0|255] "" Vector__XXX
   SG_ DATC_Opt3Typ : 40|8@1+ (1,0) [0|255] "" Vector__XXX
   SG_ DATC_Opt2Typ : 48|4@1+ (1,0) [0|15] "" Vector__XXX
   SG_ DATC_Opt4Typ : 52|6@1+ (1,0) [0|63] "" Vector__XXX
   SG_ DATC_StrWhlUSMSta : 58|2@1+ (1,0) [0|3] "" Vector__XXX
   SG_ DATC_StrWhlHtngReq : 60|4@1+ (1,0) [0|15] "" Vector__XXX

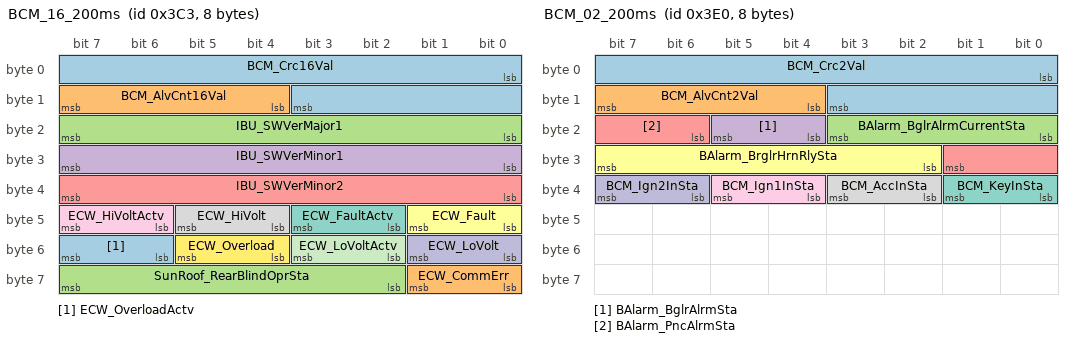
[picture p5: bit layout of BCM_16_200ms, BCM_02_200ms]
BO_ 963 BCM_16_200ms: 8 Vector__XXX
   SG_ BCM_Crc16Val : 0|12@1+ (1,0) [0|4095] "" Vector__XXX
   SG_ BCM_AlvCnt16Val : 12|4@1+ (1,0) [0|15] "" Vector__XXX
   SG_ IBU_SWVerMajor1 : 16|8@1+ (1,0) [0|255] "" Vector__XXX
   SG_ IBU_SWVerMinor1 : 24|8@1+ (1,0) [0|255] "" Vector__XXX
   SG_ IBU_SWVerMinor2 : 32|8@1+ (1,0) [0|255] "" Vector__XXX
   SG_ ECW_Fault : 40|2@1+ (1,0) [0|3] "" Vector__XXX
   SG_ ECW_FaultActv : 42|2@1+ (1,0) [0|3] "" Vector__XXX
   SG_ ECW_HiVolt : 44|2@1+ (1,0) [0|3] "" Vector__XXX
   SG_ ECW_HiVoltActv : 46|2@1+ (1,0) [0|3] "" Vector__XXX
   SG_ ECW_LoVolt : 48|2@1+ (1,0) [0|3] "" Vector__XXX
   SG_ ECW_LoVoltActv : 50|2@1+ (1,0) [0|3] "" Vector__XXX
   SG_ ECW_Overload : 52|2@1+ (1,0) [0|3] "" Vector__XXX
   SG_ ECW_OverloadActv : 54|2@1+ (1,0) [0|3] "" Vector__XXX
   SG_ ECW_CommErr : 56|2@1+ (1,0) [0|3] "" Vector__XXX
   SG_ SunRoof_RearBlindOprSta : 58|6@1+ (1,0) [0|63] "" Vector__XXX

BO_ 992 BCM_02_200ms: 8 Vector__XXX
   SG_ BCM_Crc2Val : 0|12@1+ (1,0) [0|4095] "" Vector__XXX
   SG_ BCM_AlvCnt2Val : 12|4@1+ (1,0) [0|15] "" Vector__XXX
   SG_ BAlarm_BglrAlrmCurrentSta : 16|4@1+ (1,0) [0|15] "" Vector__XXX
   SG_ BAlarm_BglrAlrmSta : 20|2@1+ (1,0) [0|3] "" Vector__XXX
   SG_ BAlarm_PncAlrmSta : 22|4@1+ (1,0) [0|15] "" Vector__XXX
   SG_ BAlarm_BrglrHrnRlySta : 26|6@1+ (1,0) [0|63] "" Vector__XXX
   SG_ BCM_KeyInSta : 32|2@1+ (1,0) [0|3] "" Vector__XXX
   SG_ BCM_AccInSta : 34|2@1+ (1,0) [0|3] "" Vector__XXX
   SG_ BCM_Ign1InSta : 36|2@1+ (1,0) [0|3] "" Vector__XXX
   SG_ BCM_Ign2InSta : 38|2@1+ (1,0) [0|3] "" Vector__XXX

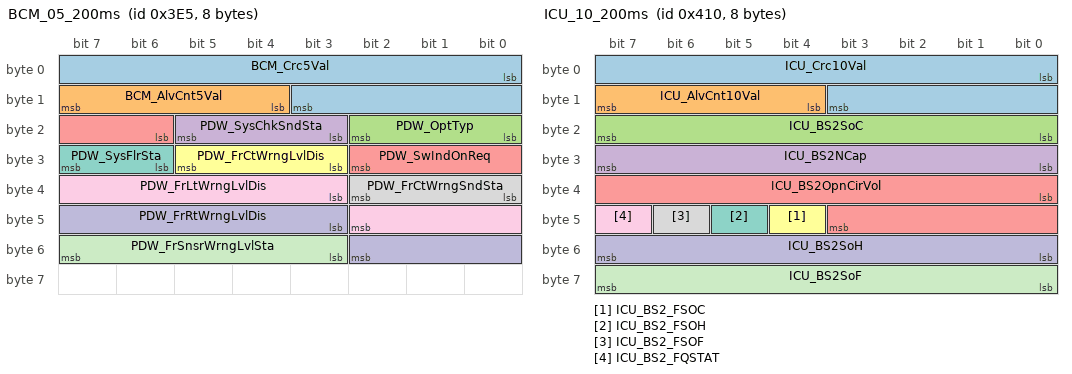
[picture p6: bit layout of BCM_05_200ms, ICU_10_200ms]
BO_ 997 BCM_05_200ms: 8 Vector__XXX
   SG_ BCM_Crc5Val : 0|12@1+ (1,0) [0|4095] "" Vector__XXX
   SG_ BCM_AlvCnt5Val : 12|4@1+ (1,0) [0|15] "" Vector__XXX
   SG_ PDW_OptTyp : 16|3@1+ (1,0) [0|7] "" Vector__XXX
   SG_ PDW_SysChkSndSta : 19|3@1+ (1,0) [0|7] "" Vector__XXX
   SG_ PDW_SwIndOnReq : 22|5@1+ (1,0) [0|31] "" Vector__XXX
   SG_ PDW_FrCtWrngLvlDis : 27|3@1+ (1,0) [0|7] "" Vector__XXX
   SG_ PDW_SysFlrSta : 30|2@1+ (1,0) [0|3] "" Vector__XXX
   SG_ PDW_FrCtWrngSndSta : 32|3@1+ (1,0) [0|7] "" Vector__XXX
   SG_ PDW_FrLtWrngLvlDis : 35|8@1+ (1,0) [0|255] "" Vector__XXX
   SG_ PDW_FrRtWrngLvlDis : 43|8@1+ (1,0) [0|255] "" Vector__XXX
   SG_ PDW_FrSnsrWrngLvlSta : 51|5@1+ (1,0) [0|31] "" Vector__XXX

BO_ 998 BCM_06_200ms: 8 Vector__XXX
   SG_ BCM_Crc6Val : 0|12@1+ (1,0) [0|4095] "" Vector__XXX
   SG_ BCM_AlvCnt6Val : 12|4@1+ (1,0) [0|15] "" Vector__XXX
   SG_ PDW_RrCtWrngLvlDis : 16|8@1+ (1,0) [0|255] "" Vector__XXX
   SG_ PDW_RrLtWrngLvlDis : 24|8@1+ (1,0) [0|255] "" Vector__XXX
   SG_ PDW_RrRtWrngLvlDis : 32|8@1+ (1,0) [0|255] "" Vector__XXX

BO_ 1029 ICU_12_200ms: 8 Vector__XXX
   SG_ ICU_Crc12Val : 0|12@1+ (1,0) [0|4095] "" Vector__XXX
   SG_ ICU_AlvCnt12Val : 12|8@1+ (1,0) [0|255] "" Vector__XXX
   SG_ DoorLock_CtrlDrLkSwSta_ICU : 20|2@1+ (1,0) [0|3] "" Vector__XXX
   SG_ DoorLock_CtrlDrUnLkSwSta_ICU : 22|18@1+ (1,0) [0|262143] "" Vector__XXX
   SG_ ICU_IGN3On_ReqState_New : 40|8@1+ (1,0) [0|255] "" Vector__XXX
   SG_ ICU_BattMngAlert : 48|8@1+ (1,0) [0|255] "" Vector__XXX

BO_ 1040 ICU_10_200ms: 8 Vector__XXX
   SG_ ICU_Crc10Val : 0|12@1+ (1,0) [0|4095] "" Vector__XXX
   SG_ ICU_AlvCnt10Val : 12|4@1+ (1,0) [0|15] "" Vector__XXX
   SG_ ICU_BS2SoC : 16|8@1+ (1,0) [0|255] "" Vector__XXX
   SG_ ICU_BS2NCap : 24|8@1+ (1,0) [0|255] "" Vector__XXX
   SG_ ICU_BS2OpnCirVol : 32|12@1+ (1,0) [0|4095] "" Vector__XXX
   SG_ ICU_BS2_FSOC : 44|1@1+ (1,0) [0|1] "" Vector__XXX
   SG_ ICU_BS2_FSOH : 45|1@1+ (1,0) [0|1] "" Vector__XXX
   SG_ ICU_BS2_FSOF : 46|1@1+ (1,0) [0|1] "" Vector__XXX
   SG_ ICU_BS2_FQSTAT : 47|1@1+ (1,0) [0|1] "" Vector__XXX
   SG_ ICU_BS2SoH : 48|8@1+ (1,0) [0|255] "" Vector__XXX
   SG_ ICU_BS2SoF : 56|8@1+ (1,0) [0|255] "" Vector__XXX

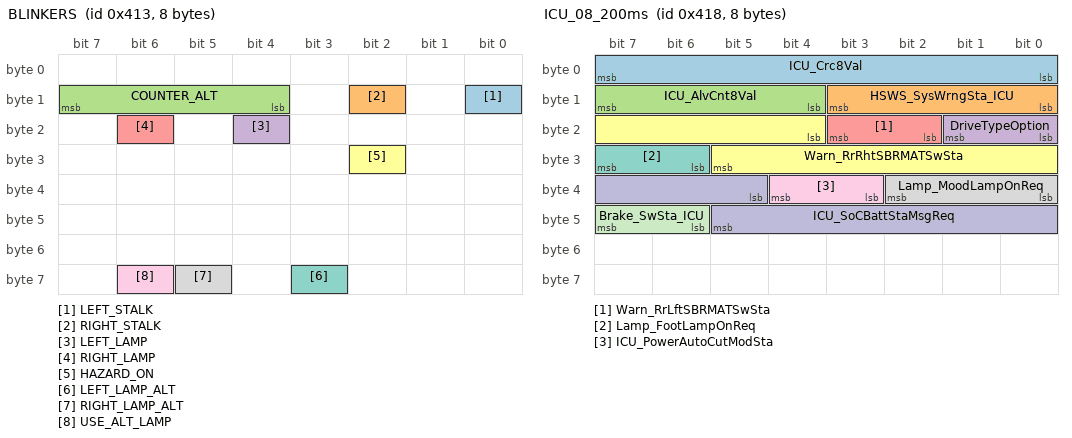
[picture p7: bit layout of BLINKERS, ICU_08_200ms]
BO_ 1043 BLINKERS: 8 Vector__XXX
   SG_ LEFT_STALK : 8|1@0+ (1,0) [0|1] "" Vector__XXX
   SG_ RIGHT_STALK : 10|1@0+ (1,0) [0|1] "" Vector__XXX
   SG_ COUNTER_ALT : 15|4@0+ (1,0) [0|15] "" Vector__XXX
   SG_ LEFT_LAMP : 20|1@0+ (1,0) [0|1] "" Vector__XXX
   SG_ RIGHT_LAMP : 22|1@0+ (1,0) [0|1] "" Vector__XXX
   SG_ HAZARD_ON : 26|1@0+ (1,0) [0|1] "" Vector__XXX
   SG_ LEFT_LAMP_ALT : 59|1@0+ (1,0) [0|1] "" Vector__XXX
   SG_ RIGHT_LAMP_ALT : 61|1@0+ (1,0) [0|1] "" Vector__XXX
   SG_ USE_ALT_LAMP : 62|1@0+ (1,0) [0|1] "" Vector__XXX

BO_ 1046 ICU_06_200ms: 8 Vector__XXX
   SG_ ICU_Crc6Val : 0|12@1+ (1,0) [0|4095] "" Vector__XXX
   SG_ ICU_AlvCnt6Val : 12|38@1+ (1,0) [0|2.74878e+11] "" Vector__XXX
   SG_ Lamp_RrTrnSigLmpLftOpnSta : 50|2@1+ (1,0) [0|3] "" Vector__XXX
   SG_ Lamp_RrTrnSigLmpRtOpnSta : 52|2@1+ (1,0) [0|3] "" Vector__XXX
   SG_ Lamp_FrTrnSigLmpLftOpnSta : 54|2@1+ (1,0) [0|3] "" Vector__XXX
   SG_ Lamp_FrTrnSigLmpRtOpnSta : 56|8@1+ (1,0) [0|255] "" Vector__XXX

BO_ 1047 ICU_07_200ms: 8 Vector__XXX
   SG_ ICU_Crc7Val : 0|12@1+ (1,0) [0|4095] "" Vector__XXX
   SG_ ICU_AlvCnt7Val : 12|4@1+ (1,0) [0|15] "" Vector__XXX

BO_ 1048 ICU_08_200ms: 8 Vector__XXX
   SG_ ICU_Crc8Val : 0|8@1+ (1,0) [0|255] "" Vector__XXX
   SG_ HSWS_SysWrngSta_ICU : 8|4@1+ (1,0) [0|15] "" Vector__XXX
   SG_ ICU_AlvCnt8Val : 12|4@1+ (1,0) [0|15] "" Vector__XXX
   SG_ DriveTypeOption : 16|2@1+ (1,0) [0|3] "" Vector__XXX
   SG_ Warn_RrLftSBRMATSwSta : 18|2@1+ (1,0) [0|3] "" Vector__XXX
   SG_ Warn_RrRhtSBRMATSwSta : 20|10@1+ (1,0) [0|1023] "" Vector__XXX
   SG_ Lamp_FootLampOnReq : 30|2@1+ (1,0) [0|3] "" Vector__XXX
   SG_ Lamp_MoodLampOnReq : 32|3@1+ (1,0) [0|7] "" Vector__XXX
   SG_ ICU_PowerAutoCutModSta : 35|2@1+ (1,0) [0|3] "" Vector__XXX
   SG_ ICU_SoCBattStaMsgReq : 37|9@1+ (1,0) [0|511] "" Vector__XXX
   SG_ Brake_SwSta_ICU : 46|2@1+ (1,0) [0|3] "" Vector__XXX

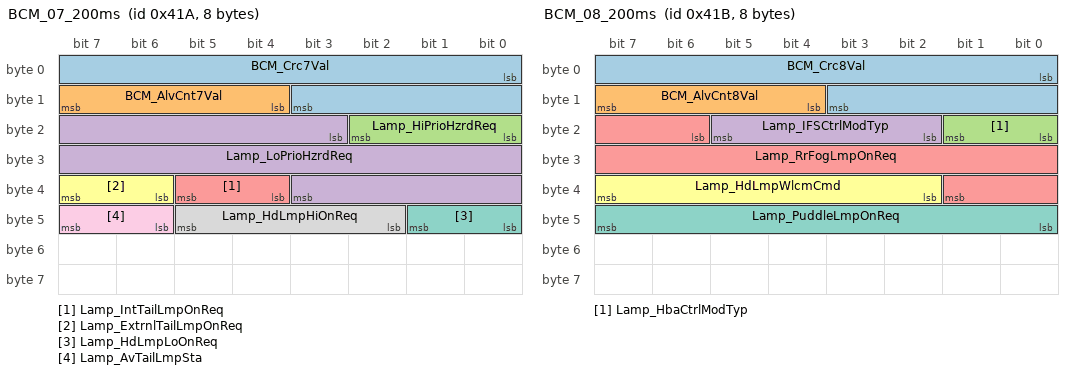
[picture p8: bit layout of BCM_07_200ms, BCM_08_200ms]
BO_ 1050 BCM_07_200ms: 8 Vector__XXX
   SG_ BCM_Crc7Val : 0|12@1+ (1,0) [0|4095] "" Vector__XXX
   SG_ BCM_AlvCnt7Val : 12|4@1+ (1,0) [0|15] "" Vector__XXX
   SG_ Lamp_HiPrioHzrdReq : 16|3@1+ (1,0) [0|7] "" Vector__XXX
   SG_ Lamp_LoPrioHzrdReq : 19|17@1+ (1,0) [0|131071] "" Vector__XXX
   SG_ Lamp_IntTailLmpOnReq : 36|2@1+ (1,0) [0|3] "" Vector__XXX
   SG_ Lamp_ExtrnlTailLmpOnReq : 38|2@1+ (1,0) [0|3] "" Vector__XXX
   SG_ Lamp_HdLmpLoOnReq : 40|2@1+ (1,0) [0|3] "" Vector__XXX
   SG_ Lamp_HdLmpHiOnReq : 42|4@1+ (1,0) [0|15] "" Vector__XXX
   SG_ Lamp_AvTailLmpSta : 46|2@1+ (1,0) [0|3] "" Vector__XXX

BO_ 1051 BCM_08_200ms: 8 Vector__XXX
   SG_ BCM_Crc8Val : 0|12@1+ (1,0) [0|4095] "" Vector__XXX
   SG_ BCM_AlvCnt8Val : 12|4@1+ (1,0) [0|15] "" Vector__XXX
   SG_ Lamp_HbaCtrlModTyp : 16|2@1+ (1,0) [0|3] "" Vector__XXX
   SG_ Lamp_IFSCtrlModTyp : 18|4@1+ (1,0) [0|15] "" Vector__XXX
   SG_ Lamp_RrFogLmpOnReq : 22|12@1+ (1,0) [0|4095] "" Vector__XXX
   SG_ Lamp_HdLmpWlcmCmd : 34|6@1+ (1,0) [0|63] "" Vector__XXX
   SG_ Lamp_PuddleLmpOnReq : 40|8@1+ (1,0) [0|255] "" Vector__XXX

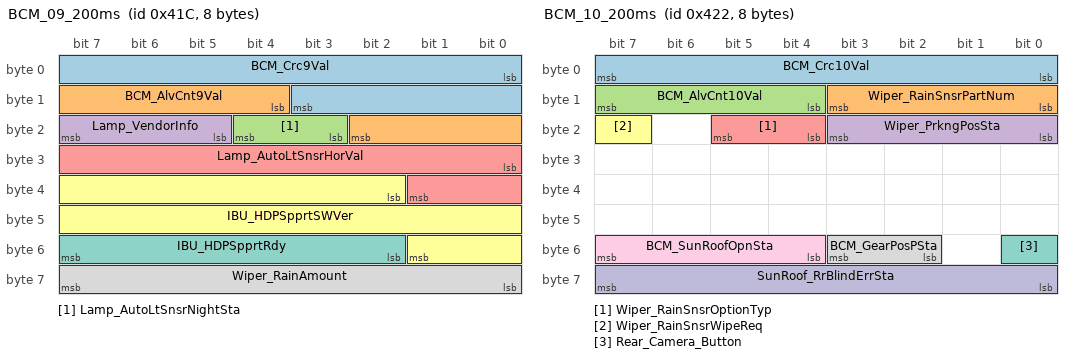
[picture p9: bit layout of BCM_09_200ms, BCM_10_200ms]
BO_ 1052 BCM_09_200ms: 8 Vector__XXX
   SG_ BCM_Crc9Val : 0|12@1+ (1,0) [0|4095] "" Vector__XXX
   SG_ BCM_AlvCnt9Val : 12|7@1+ (1,0) [0|127] "" Vector__XXX
   SG_ Lamp_AutoLtSnsrNightSta : 19|2@1+ (1,0) [0|3] "" Vector__XXX
   SG_ Lamp_VendorInfo : 21|3@1+ (1,0) [0|7] "" Vector__XXX
   SG_ Lamp_AutoLtSnsrHorVal : 24|10@1+ (1,0) [0|1023] "" Vector__XXX
   SG_ IBU_HDPSpprtSWVer : 34|16@1+ (1,0) [0|65535] "" Vector__XXX
   SG_ IBU_HDPSpprtRdy : 50|6@1+ (1,0) [0|63] "" Vector__XXX
   SG_ Wiper_RainAmount : 56|8@1+ (1,0) [0|255] "" Vector__XXX

BO_ 1055 HU_AVM_PE: 8 Vector__XXX
   SG_ HU_SVM_tch_mpt_valid__ccp_pan : 8|8@1+ (1,0) [0|255] "" Vector__XXX
   SG_ HU_SVM_ccp_pan_valid : 9|1@1+ (1,0) [0|1] "" Vector__XXX
   SG_ SVM_CaptureModeCMD : 10|46@1+ (1,0) [0|7.03687e+13] "" Vector__XXX
   SG_ HU_SVM_ccp_pan : 56|8@1+ (1,0) [0|255] "" Vector__XXX

BO_ 1058 BCM_10_200ms: 8 Vector__XXX
   SG_ BCM_Crc10Val : 0|8@1+ (1,0) [0|255] "" Vector__XXX
   SG_ Wiper_RainSnsrPartNum : 8|4@1+ (1,0) [0|15] "" Vector__XXX
   SG_ BCM_AlvCnt10Val : 12|4@1+ (1,0) [0|15] "" Vector__XXX
   SG_ Wiper_PrkngPosSta : 16|4@1+ (1,0) [0|15] "" Vector__XXX
   SG_ Wiper_RainSnsrOptionTyp : 20|2@1+ (1,0) [0|3] "" Vector__XXX
   SG_ Wiper_RainSnsrWipeReq : 23|1@1+ (1,0) [0|1] "" Vector__XXX
   SG_ Rear_Camera_Button : 48|1@1+ (1,0) [0|1] "" Vector__XXX
   SG_ BCM_GearPosPSta : 50|2@1+ (1,0) [0|3] "" Vector__XXX
   SG_ BCM_SunRoofOpnSta : 52|4@1+ (1,0) [0|15] "" Vector__XXX
   SG_ SunRoof_RrBlindErrSta : 56|8@1+ (1,0) [0|255] "" Vector__XXX

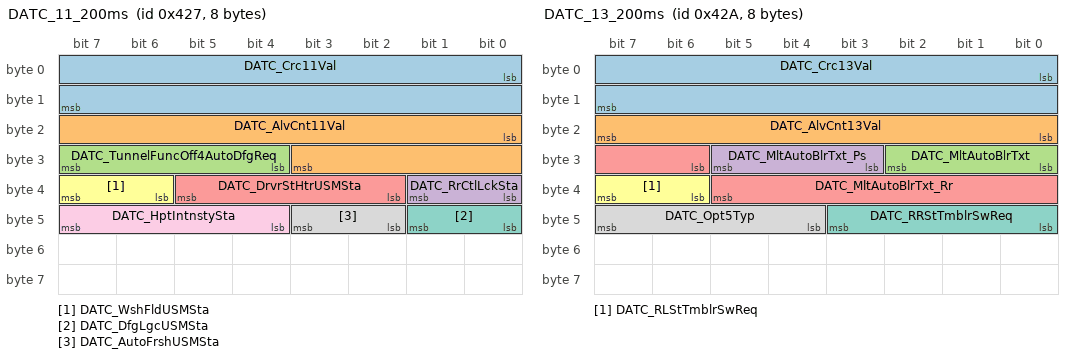
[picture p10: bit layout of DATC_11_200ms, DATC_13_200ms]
BO_ 1063 DATC_11_200ms: 8 Vector__XXX
   SG_ DATC_Crc11Val : 0|16@1+ (1,0) [0|65535] "" Vector__XXX
   SG_ DATC_AlvCnt11Val : 16|12@1+ (1,0) [0|4095] "" Vector__XXX
   SG_ DATC_TunnelFuncOff4AutoDfgReq : 28|4@1+ (1,0) [0|15] "" Vector__XXX
   SG_ DATC_RrCtlLckSta : 32|2@1+ (1,0) [0|3] "" Vector__XXX
   SG_ DATC_DrvrStHtrUSMSta : 34|4@1+ (1,0) [0|15] "" Vector__XXX
   SG_ DATC_WshFldUSMSta : 38|2@1+ (1,0) [0|3] "" Vector__XXX
   SG_ DATC_DfgLgcUSMSta : 40|2@1+ (1,0) [0|3] "" Vector__XXX
   SG_ DATC_AutoFrshUSMSta : 42|2@1+ (1,0) [0|3] "" Vector__XXX
   SG_ DATC_HptIntnstySta : 44|4@1+ (1,0) [0|15] "" Vector__XXX

BO_ 1066 DATC_13_200ms: 8 Vector__XXX
   SG_ DATC_Crc13Val : 0|16@1+ (1,0) [0|65535] "" Vector__XXX
   SG_ DATC_AlvCnt13Val : 16|8@1+ (1,0) [0|255] "" Vector__XXX
   SG_ DATC_MltAutoBlrTxt : 24|3@1+ (1,0) [0|7] "" Vector__XXX
   SG_ DATC_MltAutoBlrTxt_Ps : 27|3@1+ (1,0) [0|7] "" Vector__XXX
   SG_ DATC_MltAutoBlrTxt_Rr : 30|8@1+ (1,0) [0|255] "" Vector__XXX
   SG_ DATC_RLStTmblrSwReq : 38|2@1+ (1,0) [0|3] "" Vector__XXX
   SG_ DATC_RRStTmblrSwReq : 40|4@1+ (1,0) [0|15] "" Vector__XXX
   SG_ DATC_Opt5Typ : 44|4@1+ (1,0) [0|15] "" Vector__XXX

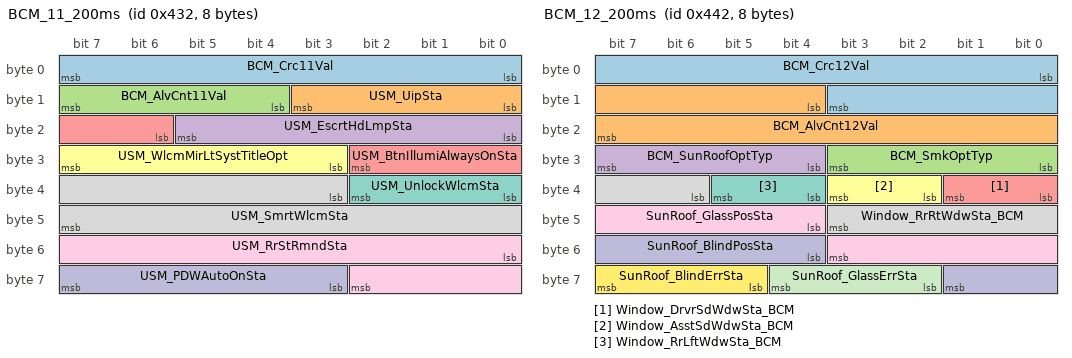
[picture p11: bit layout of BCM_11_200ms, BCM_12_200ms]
BO_ 1074 BCM_11_200ms: 8 Vector__XXX
   SG_ BCM_Crc11Val : 0|8@1+ (1,0) [0|255] "" Vector__XXX
   SG_ USM_UipSta : 8|4@1+ (1,0) [0|15] "" Vector__XXX
   SG_ BCM_AlvCnt11Val : 12|4@1+ (1,0) [0|15] "" Vector__XXX
   SG_ USM_EscrtHdLmpSta : 16|6@1+ (1,0) [0|63] "" Vector__XXX
   SG_ USM_BtnIllumiAlwaysOnSta : 22|5@1+ (1,0) [0|31] "" Vector__XXX
   SG_ USM_WlcmMirLtSystTitleOpt : 27|5@1+ (1,0) [0|31] "" Vector__XXX
   SG_ USM_UnlockWlcmSta : 32|3@1+ (1,0) [0|7] "" Vector__XXX
   SG_ USM_SmrtWlcmSta : 35|13@1+ (1,0) [0|8191] "" Vector__XXX
   SG_ USM_RrStRmndSta : 48|11@1+ (1,0) [0|2047] "" Vector__XXX
   SG_ USM_PDWAutoOnSta : 59|5@1+ (1,0) [0|31] "" Vector__XXX

BO_ 1090 BCM_12_200ms: 8 Vector__XXX
   SG_ BCM_Crc12Val : 0|12@1+ (1,0) [0|4095] "" Vector__XXX
   SG_ BCM_AlvCnt12Val : 12|12@1+ (1,0) [0|4095] "" Vector__XXX
   SG_ BCM_SmkOptTyp : 24|4@1+ (1,0) [0|15] "" Vector__XXX
   SG_ BCM_SunRoofOptTyp : 28|4@1+ (1,0) [0|15] "" Vector__XXX
   SG_ Window_DrvrSdWdwSta_BCM : 32|2@1+ (1,0) [0|3] "" Vector__XXX
   SG_ Window_AsstSdWdwSta_BCM : 34|2@1+ (1,0) [0|3] "" Vector__XXX
   SG_ Window_RrLftWdwSta_BCM : 36|2@1+ (1,0) [0|3] "" Vector__XXX
   SG_ Window_RrRtWdwSta_BCM : 38|6@1+ (1,0) [0|63] "" Vector__XXX
   SG_ SunRoof_GlassPosSta : 44|8@1+ (1,0) [0|255] "" Vector__XXX
   SG_ SunRoof_BlindPosSta : 52|6@1+ (1,0) [0|63] "" Vector__XXX
   SG_ SunRoof_GlassErrSta : 58|3@1+ (1,0) [0|7] "" Vector__XXX
   SG_ SunRoof_BlindErrSta : 61|3@1+ (1,0) [0|7] "" Vector__XXX

BO_ 1092 SMK_02_200ms: 8 Vector__XXX
   SG_ SMK_Crc2Val : 0|12@1+ (1,0) [0|4095] "" Vector__XXX
   SG_ SMK_AlvCnt2Val : 12|4@1+ (1,0) [0|15] "" Vector__XXX
   SG_ SSB_StrtStpBtnSw1Sta : 16|2@1+ (1,0) [0|3] "" Vector__XXX
   SG_ SSB_StrtStpBtnSw2Sta : 18|11@1+ (1,0) [0|2047] "" Vector__XXX
   SG_ ENG_PwrAutoOffInfo : 24|8@1+ (1,0) [0|255] "" Vector__XXX
   SG_ SMK_AuthSta : 29|3@1+ (1,0) [0|7] "" Vector__XXX
   SG_ SMK_Ign1InSta : 32|2@1+ (1,0) [0|3] "" Vector__XXX
   SG_ SMK_Ign1RlySta : 34|2@1+ (1,0) [0|3] "" Vector__XXX
   SG_ SMK_Ign2InSta : 36|2@1+ (1,0) [0|3] "" Vector__XXX
   SG_ SMK_Ign2RlySta : 38|2@1+ (1,0) [0|3] "" Vector__XXX
   SG_ SMK_StrtFdbckSta : 40|2@1+ (1,0) [0|3] "" Vector__XXX
   SG_ SMK_StrtrRlyOutSta : 42|2@1+ (1,0) [0|3] "" Vector__XXX
   SG_ SMK_AccInSta : 44|2@1+ (1,0) [0|3] "" Vector__XXX
   SG_ SMK_AccRlySta : 46|2@1+ (1,0) [0|3] "" Vector__XXX
   SG_ SMK_CLUAccIndOnReq : 48|8@1+ (1,0) [0|255] "" Vector__XXX
   SG_ SMK_TlEngRunSta : 56|2@1+ (1,0) [0|3] "" Vector__XXX
   SG_ SMK_TlCrnkModSta : 58|2@1+ (1,0) [0|3] "" Vector__XXX
   SG_ SMK_RmtKeyEngRunSta : 60|2@1+ (1,0) [0|3] "" Vector__XXX
   SG_ SMK_RmtKeyCrnkModSta : 62|2@1+ (1,0) [0|3] "" Vector__XXX

BO_ 1093 SMK_06_200ms: 8 Vector__XXX
   SG_ SMK_Crc6Val : 0|12@1+ (1,0) [0|4095] "" Vector__XXX
   SG_ SMK_AlvCnt6Val : 12|4@1+ (1,0) [0|15] "" Vector__XXX
   SG_ Lamp_HzrdBlnkngSta : 16|3@1+ (1,0) [0|7] "" Vector__XXX
   SG_ RSPA_LearntSta : 19|2@1+ (1,0) [0|3] "" Vector__XXX
   SG_ Lamp_SmrtWlcmLtOnReq : 21|3@1+ (1,0) [0|7] "" Vector__XXX
   SG_ Fob_BattStaInfo : 24|2@1+ (1,0) [0|3] "" Vector__XXX
   SG_ Fob_FoundDrvWlcmArea : 26|2@1+ (1,0) [0|3] "" Vector__XXX
   SG_ Fob_FoundAsstWlcmArea : 28|2@1+ (1,0) [0|3] "" Vector__XXX
   SG_ Fob_FoundExtrnlArea : 30|2@1+ (1,0) [0|3] "" Vector__XXX
   SG_ Fob_FoundIntArea : 32|2@1+ (1,0) [0|3] "" Vector__XXX
   SG_ Fob_LearntSta : 34|2@1+ (1,0) [0|3] "" Vector__XXX
   SG_ RSPA_RFSigErrSta : 36|2@1+ (1,0) [0|3] "" Vector__XXX
   SG_ RSPA_CanErrSta : 38|2@1+ (1,0) [0|3] "" Vector__XXX
   SG_ LFAnt_FltSta : 40|2@1+ (1,0) [0|3] "" Vector__XXX
   SG_ LFAnt_SrchSta : 42|6@1+ (1,0) [0|63] "" Vector__XXX
   SG_ RSPA_ModSta_SMK : 48|3@1+ (1,0) [0|7] "" Vector__XXX
   SG_ RSPA_FobBattSta : 51|3@1+ (1,0) [0|7] "" Vector__XXX
   SG_ Fob_BtnReleasedSta : 54|2@1+ (1,0) [0|3] "" Vector__XXX
   SG_ USM_SmrtTrnkTlgtModSta : 56|3@1+ (1,0) [0|7] "" Vector__XXX
   SG_ USM_WALModSta : 59|3@1+ (1,0) [0|7] "" Vector__XXX
   SG_ Fob_FoundWlcmArea : 62|2@1+ (1,0) [0|3] "" Vector__XXX

BO_ 1099 WPC_01_200ms: 8 Vector__XXX
   SG_ USM_CmdWPCSta : 0|2@1+ (1,0) [0|3] "" Vector__XXX
   SG_ WPC_PhnLftWrngSta : 2|14@1+ (1,0) [0|16383] "" Vector__XXX
   SG_ WPC_SWVerMajor1 : 16|8@1+ (1,0) [0|255] "" Vector__XXX
   SG_ WPC_SWVerMinor1 : 24|8@1+ (1,0) [0|255] "" Vector__XXX
   SG_ WPC_SWVerMinor2 : 32|8@1+ (1,0) [0|255] "" Vector__XXX

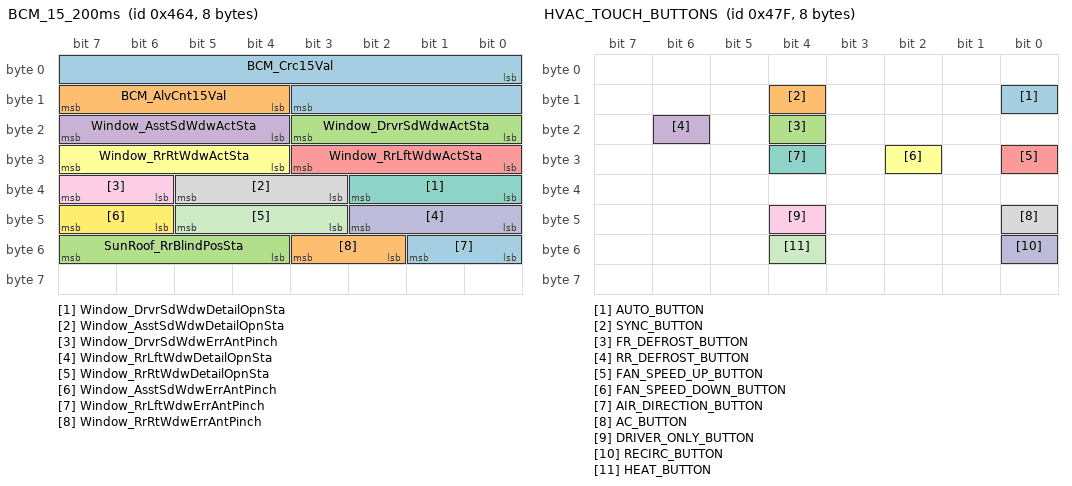
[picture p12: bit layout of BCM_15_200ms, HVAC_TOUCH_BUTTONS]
BO_ 1124 BCM_15_200ms: 8 Vector__XXX
   SG_ BCM_Crc15Val : 0|12@1+ (1,0) [0|4095] "" Vector__XXX
   SG_ BCM_AlvCnt15Val : 12|4@1+ (1,0) [0|15] "" Vector__XXX
   SG_ Window_DrvrSdWdwActSta : 16|4@1+ (1,0) [0|15] "" Vector__XXX
   SG_ Window_AsstSdWdwActSta : 20|4@1+ (1,0) [0|15] "" Vector__XXX
   SG_ Window_RrLftWdwActSta : 24|4@1+ (1,0) [0|15] "" Vector__XXX
   SG_ Window_RrRtWdwActSta : 28|4@1+ (1,0) [0|15] "" Vector__XXX
   SG_ Window_DrvrSdWdwDetailOpnSta : 32|3@1+ (1,0) [0|7] "" Vector__XXX
   SG_ Window_AsstSdWdwDetailOpnSta : 35|3@1+ (1,0) [0|7] "" Vector__XXX
   SG_ Window_DrvrSdWdwErrAntPinch : 38|2@1+ (1,0) [0|3] "" Vector__XXX
   SG_ Window_RrLftWdwDetailOpnSta : 40|3@1+ (1,0) [0|7] "" Vector__XXX
   SG_ Window_RrRtWdwDetailOpnSta : 43|3@1+ (1,0) [0|7] "" Vector__XXX
   SG_ Window_AsstSdWdwErrAntPinch : 46|2@1+ (1,0) [0|3] "" Vector__XXX
   SG_ Window_RrLftWdwErrAntPinch : 48|2@1+ (1,0) [0|3] "" Vector__XXX
   SG_ Window_RrRtWdwErrAntPinch : 50|2@1+ (1,0) [0|3] "" Vector__XXX
   SG_ SunRoof_RrBlindPosSta : 52|4@1+ (1,0) [0|15] "" Vector__XXX

BO_ 1125 DATC_14_00ms: 8 Vector__XXX
   SG_ DATC_Crc14Val : 0|16@1+ (1,0) [0|65535] "" Vector__XXX
   SG_ DATC_AlvCnt14Val : 16|34@1+ (1,0) [0|1.71799e+10] "" Vector__XXX
   SG_ DATC_Beep1Sound : 50|6@1+ (1,0) [0|63] "" Vector__XXX

BO_ 1144 DRIVE_MODE: 8 Vector__XXX
   SG_ DRIVE_MODE : 0|16@1+ (1,-61611) [0|61611] "" Vector__XXX
   SG_ DRIVE_MODE2 : 28|3@1+ (1,0) [1|3] "" Vector__XXX

BO_ 1151 HVAC_TOUCH_BUTTONS: 8 Vector__XXX
   SG_ AUTO_BUTTON : 8|1@0+ (1,0) [0|1] "" Vector__XXX
   SG_ SYNC_BUTTON : 12|1@0+ (1,0) [0|1] "" Vector__XXX
   SG_ FR_DEFROST_BUTTON : 20|1@0+ (1,0) [0|1] "" Vector__XXX
   SG_ RR_DEFROST_BUTTON : 22|1@0+ (1,0) [0|1] "" Vector__XXX
   SG_ FAN_SPEED_UP_BUTTON : 24|1@0+ (1,0) [0|1] "" Vector__XXX
   SG_ FAN_SPEED_DOWN_BUTTON : 26|1@0+ (1,0) [0|1] "" Vector__XXX
   SG_ AIR_DIRECTION_BUTTON : 28|1@0+ (1,0) [0|1] "" Vector__XXX
   SG_ AC_BUTTON : 40|1@0+ (1,0) [0|1] "" Vector__XXX
   SG_ DRIVER_ONLY_BUTTON : 44|1@0+ (1,0) [0|1] "" Vector__XXX
   SG_ RECIRC_BUTTON : 48|1@0+ (1,0) [0|1] "" Vector__XXX
   SG_ HEAT_BUTTON : 52|1@0+ (1,0) [0|1] "" Vector__XXX

BO_ 1157 VESS_PE: 8 Vector__XXX
   SG_ VESS_CLU_Warning : 6|5@1+ (1,0) [0|31] "" Vector__XXX
   SG_ VESS_LogSnapshotState : 11|2@1+ (1,0) [0|3] "" Vector__XXX
   SG_ VESS_ChgGuideMdLvlSt : 13|3@1+ (1,0) [0|7] "" Vector__XXX
   SG_ VESS_SWVerMajor : 16|8@1+ (1,0) [0|255] "" Vector__XXX
   SG_ VESS_SWVerMinor : 24|8@1+ (1,0) [0|255] "" Vector__XXX

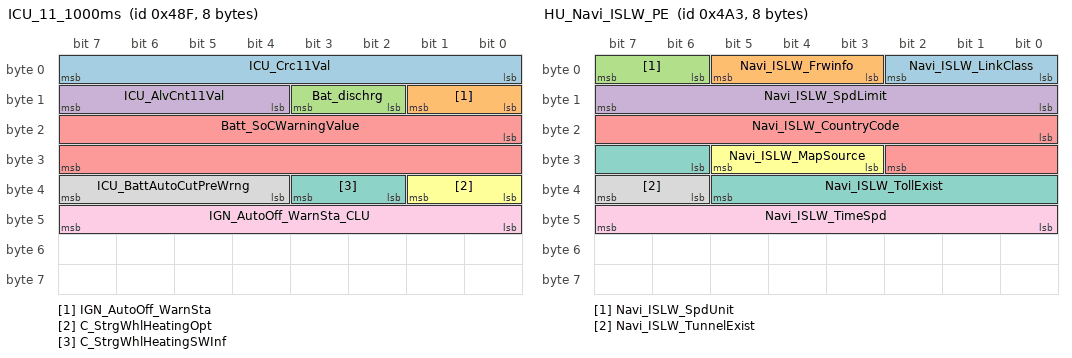
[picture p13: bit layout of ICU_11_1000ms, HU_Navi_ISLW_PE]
BO_ 1167 ICU_11_1000ms: 8 Vector__XXX
   SG_ ICU_Crc11Val : 0|8@1+ (1,0) [0|255] "" Vector__XXX
   SG_ IGN_AutoOff_WarnSta : 8|2@1+ (1,0) [0|3] "" Vector__XXX
   SG_ Bat_dischrg : 10|2@1+ (1,0) [0|3] "" Vector__XXX
   SG_ ICU_AlvCnt11Val : 12|4@1+ (1,0) [0|15] "" Vector__XXX
   SG_ Batt_SoCWarningValue : 16|16@1+ (1,0) [0|65535] "" Vector__XXX
   SG_ C_StrgWhlHeatingOpt : 32|2@1+ (1,0) [0|3] "" Vector__XXX
   SG_ C_StrgWhlHeatingSWInf : 34|2@1+ (1,0) [0|3] "" Vector__XXX
   SG_ ICU_BattAutoCutPreWrng : 36|4@1+ (1,0) [0|15] "" Vector__XXX
   SG_ IGN_AutoOff_WarnSta_CLU : 40|8@1+ (1,0) [0|255] "" Vector__XXX

BO_ 1187 HU_Navi_ISLW_PE: 8 Vector__XXX
   SG_ Navi_ISLW_LinkClass : 0|3@1+ (1,0) [0|7] "" Vector__XXX
   SG_ Navi_ISLW_Frwinfo : 3|3@1+ (1,0) [0|7] "" Vector__XXX
   SG_ Navi_ISLW_SpdUnit : 6|2@1+ (1,0) [0|3] "" Vector__XXX
   SG_ Navi_ISLW_SpdLimit : 8|8@1+ (1,0) [0|255] "" Vector__XXX
   SG_ Navi_ISLW_CountryCode : 16|11@1+ (1,0) [0|2047] "" Vector__XXX
   SG_ Navi_ISLW_MapSource : 27|3@1+ (1,0) [0|7] "" Vector__XXX
   SG_ Navi_ISLW_TollExist : 30|8@1+ (1,0) [0|255] "" Vector__XXX
   SG_ Navi_ISLW_TunnelExist : 38|2@1+ (1,0) [0|3] "" Vector__XXX
   SG_ Navi_ISLW_TimeSpd : 40|8@1+ (1,0) [0|255] "" Vector__XXX

BO_ 1201 HU_EV_P_02_CF_HU_DepartSet2: 8 Vector__XXX
   SG_ ICU_Popup_Enable : 26|6@1+ (1,0) [0|63] "" Vector__XXX

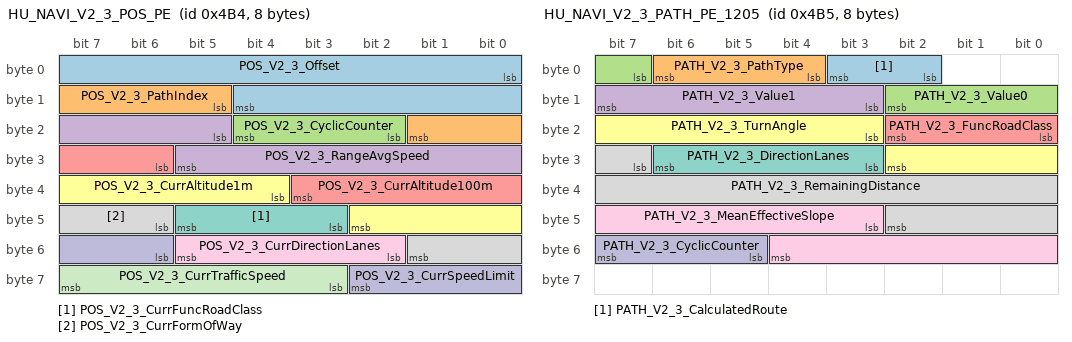
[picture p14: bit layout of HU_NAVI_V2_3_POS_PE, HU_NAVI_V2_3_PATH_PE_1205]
BO_ 1204 HU_NAVI_V2_3_POS_PE: 8 Vector__XXX
   SG_ POS_V2_3_Offset : 0|13@1+ (1,0) [0|8191] "" Vector__XXX
   SG_ POS_V2_3_PathIndex : 13|5@1+ (1,0) [0|31] "" Vector__XXX
   SG_ POS_V2_3_CyclicCounter : 18|3@1+ (1,0) [0|7] "" Vector__XXX
   SG_ POS_V2_3_RangeAvgSpeed : 21|9@1+ (1,0) [0|511] "" Vector__XXX
   SG_ POS_V2_3_CurrAltitude100m : 30|6@1+ (1,0) [0|63] "" Vector__XXX
   SG_ POS_V2_3_CurrAltitude1m : 36|7@1+ (1,0) [0|127] "" Vector__XXX
   SG_ POS_V2_3_CurrFuncRoadClass : 43|3@1+ (1,0) [0|7] "" Vector__XXX
   SG_ POS_V2_3_CurrFormOfWay : 46|4@1+ (1,0) [0|15] "" Vector__XXX
   SG_ POS_V2_3_CurrDirectionLanes : 50|4@1+ (1,0) [0|15] "" Vector__XXX
   SG_ POS_V2_3_CurrSpeedLimit : 54|5@1+ (1,0) [0|31] "" Vector__XXX
   SG_ POS_V2_3_CurrTrafficSpeed : 59|5@1+ (1,0) [0|31] "" Vector__XXX

BO_ 1205 HU_NAVI_V2_3_PATH_PE_1205: 8 Vector__XXX
   SG_ PATH_V2_3_CalculatedRoute : 2|2@1+ (1,0) [0|3] "" Vector__XXX
   SG_ PATH_V2_3_PathType : 4|3@1+ (1,0) [0|7] "" Vector__XXX
   SG_ PATH_V2_3_Value0 : 7|4@1+ (1,0) [0|15] "" Vector__XXX
   SG_ PATH_V2_3_Value1 : 11|5@1+ (1,0) [0|31] "" Vector__XXX
   SG_ PATH_V2_3_FuncRoadClass : 16|3@1+ (1,0) [0|7] "" Vector__XXX
   SG_ PATH_V2_3_TurnAngle : 19|8@1+ (1,0) [0|255] "" Vector__XXX
   SG_ PATH_V2_3_DirectionLanes : 27|4@1+ (1,0) [0|15] "" Vector__XXX
   SG_ PATH_V2_3_RemainingDistance : 31|12@1+ (1,0) [0|4095] "" Vector__XXX
   SG_ PATH_V2_3_MeanEffectiveSlope : 43|10@1+ (1,0) [0|1023] "" Vector__XXX
   SG_ PATH_V2_3_CyclicCounter : 53|3@1+ (1,0) [0|7] "" Vector__XXX

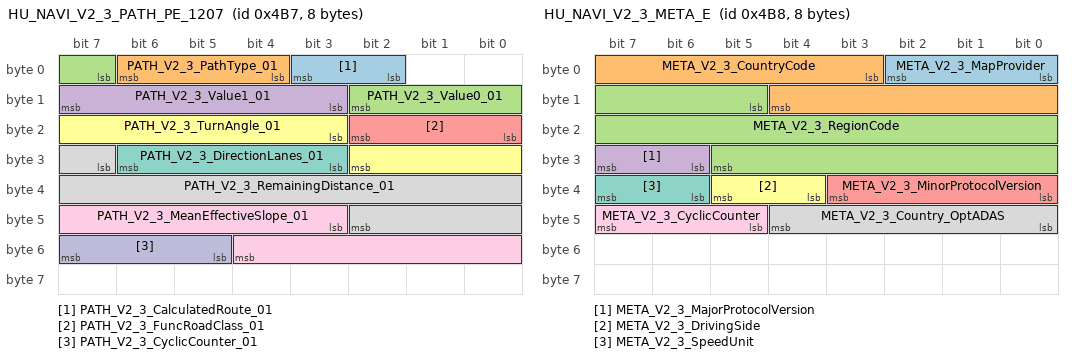
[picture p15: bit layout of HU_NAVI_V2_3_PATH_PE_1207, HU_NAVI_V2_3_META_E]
BO_ 1207 HU_NAVI_V2_3_PATH_PE_1207: 8 Vector__XXX
   SG_ PATH_V2_3_CalculatedRoute_01 : 2|2@1+ (1,0) [0|3] "" Vector__XXX
   SG_ PATH_V2_3_PathType_01 : 4|3@1+ (1,0) [0|7] "" Vector__XXX
   SG_ PATH_V2_3_Value0_01 : 7|4@1+ (1,0) [0|15] "" Vector__XXX
   SG_ PATH_V2_3_Value1_01 : 11|5@1+ (1,0) [0|31] "" Vector__XXX
   SG_ PATH_V2_3_FuncRoadClass_01 : 16|3@1+ (1,0) [0|7] "" Vector__XXX
   SG_ PATH_V2_3_TurnAngle_01 : 19|8@1+ (1,0) [0|255] "" Vector__XXX
   SG_ PATH_V2_3_DirectionLanes_01 : 27|4@1+ (1,0) [0|15] "" Vector__XXX
   SG_ PATH_V2_3_RemainingDistance_01 : 31|12@1+ (1,0) [0|4095] "" Vector__XXX
   SG_ PATH_V2_3_MeanEffectiveSlope_01 : 43|10@1+ (1,0) [0|1023] "" Vector__XXX
   SG_ PATH_V2_3_CyclicCounter_01 : 53|3@1+ (1,0) [0|7] "" Vector__XXX

BO_ 1208 HU_NAVI_V2_3_META_E: 8 Vector__XXX
   SG_ META_V2_3_MapProvider : 0|3@1+ (1,0) [0|7] "" Vector__XXX
   SG_ META_V2_3_CountryCode : 3|10@1+ (1,0) [0|1023] "" Vector__XXX
   SG_ META_V2_3_RegionCode : 13|17@1+ (1,0) [0|131071] "" Vector__XXX
   SG_ META_V2_3_MajorProtocolVersion : 30|2@1+ (1,0) [0|3] "" Vector__XXX
   SG_ META_V2_3_MinorProtocolVersion : 32|4@1+ (1,0) [0|15] "" Vector__XXX
   SG_ META_V2_3_DrivingSide : 36|2@1+ (1,0) [0|3] "" Vector__XXX
   SG_ META_V2_3_SpeedUnit : 38|2@1+ (1,0) [0|3] "" Vector__XXX
   SG_ META_V2_3_Country_OptADAS : 40|5@1+ (1,0) [0|31] "" Vector__XXX
   SG_ META_V2_3_CyclicCounter : 45|3@1+ (1,0) [0|7] "" Vector__XXX

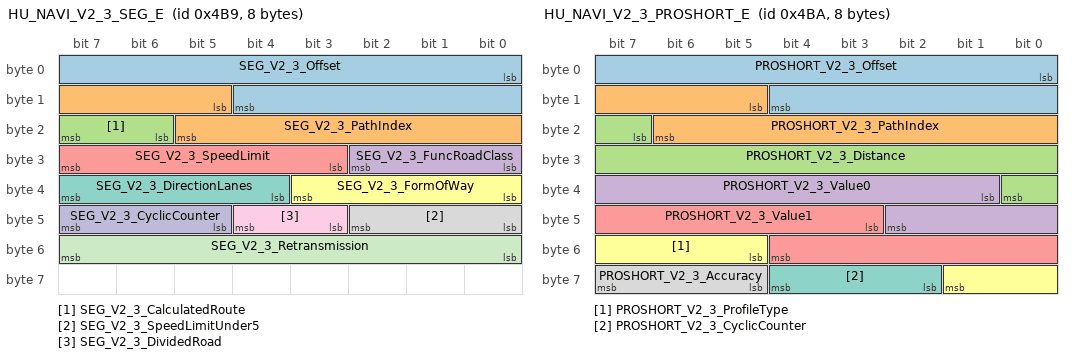
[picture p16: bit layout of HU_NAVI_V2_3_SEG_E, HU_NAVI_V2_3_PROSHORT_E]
BO_ 1209 HU_NAVI_V2_3_SEG_E: 8 Vector__XXX
   SG_ SEG_V2_3_Offset : 0|13@1+ (1,0) [0|8191] "" Vector__XXX
   SG_ SEG_V2_3_PathIndex : 13|9@1+ (1,0) [0|511] "" Vector__XXX
   SG_ SEG_V2_3_CalculatedRoute : 22|2@1+ (1,0) [0|3] "" Vector__XXX
   SG_ SEG_V2_3_FuncRoadClass : 24|3@1+ (1,0) [0|7] "" Vector__XXX
   SG_ SEG_V2_3_SpeedLimit : 27|5@1+ (1,0) [0|31] "" Vector__XXX
   SG_ SEG_V2_3_FormOfWay : 32|4@1+ (1,0) [0|15] "" Vector__XXX
   SG_ SEG_V2_3_DirectionLanes : 36|4@1+ (1,0) [0|15] "" Vector__XXX
   SG_ SEG_V2_3_SpeedLimitUnder5 : 40|3@1+ (1,0) [0|7] "" Vector__XXX
   SG_ SEG_V2_3_DividedRoad : 43|2@1+ (1,0) [0|3] "" Vector__XXX
   SG_ SEG_V2_3_CyclicCounter : 45|3@1+ (1,0) [0|7] "" Vector__XXX
   SG_ SEG_V2_3_Retransmission : 48|8@1+ (1,0) [0|255] "" Vector__XXX

BO_ 1210 HU_NAVI_V2_3_PROSHORT_E: 8 Vector__XXX
   SG_ PROSHORT_V2_3_Offset : 0|13@1+ (1,0) [0|8191] "" Vector__XXX
   SG_ PROSHORT_V2_3_PathIndex : 13|10@1+ (1,0) [0|1023] "" Vector__XXX
   SG_ PROSHORT_V2_3_Distance : 23|10@1+ (1,0) [0|1023] "" Vector__XXX
   SG_ PROSHORT_V2_3_Value0 : 33|10@1+ (1,0) [0|1023] "" Vector__XXX
   SG_ PROSHORT_V2_3_Value1 : 43|10@1+ (1,0) [0|1023] "" Vector__XXX
   SG_ PROSHORT_V2_3_ProfileType : 53|5@1+ (1,0) [0|31] "" Vector__XXX
   SG_ PROSHORT_V2_3_CyclicCounter : 58|3@1+ (1,0) [0|7] "" Vector__XXX
   SG_ PROSHORT_V2_3_Accuracy : 61|3@1+ (1,0) [0|7] "" Vector__XXX

BO_ 1214 HU_NAVI_V2_3_PROLONG_E: 8 Vector__XXX
   SG_ PROLONG_V2_3_Value : 0|32@1+ (1,0) [0|4294967295] "" Vector__XXX
   SG_ PROLONG_V2_3_Offset : 32|16@1+ (1,0) [0|65535] "" Vector__XXX
   SG_ PROLONG_V2_3_PathIndex : 48|6@1+ (1,0) [0|63] "" Vector__XXX
   SG_ PROLONG_V2_3_ProfileType : 54|5@1+ (1,0) [0|31] "" Vector__XXX
   SG_ PROLONG_V2_3_CyclicCounter : 59|3@1+ (1,0) [0|7] "" Vector__XXX
   SG_ PROLONG_V2_3_Update : 62|2@1+ (1,0) [0|3] "" Vector__XXX

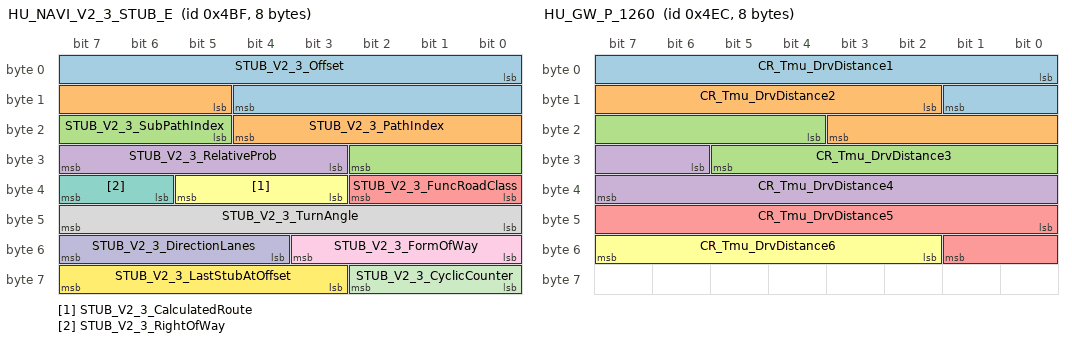
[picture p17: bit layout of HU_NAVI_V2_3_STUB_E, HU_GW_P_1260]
BO_ 1215 HU_NAVI_V2_3_STUB_E: 8 Vector__XXX
   SG_ STUB_V2_3_Offset : 0|13@1+ (1,0) [0|8191] "" Vector__XXX
   SG_ STUB_V2_3_PathIndex : 13|8@1+ (1,0) [0|255] "" Vector__XXX
   SG_ STUB_V2_3_SubPathIndex : 21|6@1+ (1,0) [0|63] "" Vector__XXX
   SG_ STUB_V2_3_RelativeProb : 27|5@1+ (1,0) [0|31] "" Vector__XXX
   SG_ STUB_V2_3_FuncRoadClass : 32|3@1+ (1,0) [0|7] "" Vector__XXX
   SG_ STUB_V2_3_CalculatedRoute : 35|3@1+ (1,0) [0|7] "" Vector__XXX
   SG_ STUB_V2_3_RightOfWay : 38|2@1+ (1,0) [0|3] "" Vector__XXX
   SG_ STUB_V2_3_TurnAngle : 40|8@1+ (1,0) [0|255] "" Vector__XXX
   SG_ STUB_V2_3_FormOfWay : 48|4@1+ (1,0) [0|15] "" Vector__XXX
   SG_ STUB_V2_3_DirectionLanes : 52|4@1+ (1,0) [0|15] "" Vector__XXX
   SG_ STUB_V2_3_CyclicCounter : 56|3@1+ (1,0) [0|7] "" Vector__XXX
   SG_ STUB_V2_3_LastStubAtOffset : 59|5@1+ (1,0) [0|31] "" Vector__XXX

BO_ 1224 HU_TMU_E: 8 Vector__XXX
   SG_ HU_eCallStatus : 19|5@1+ (1,0) [0|31] "" Vector__XXX
   SG_ C_SHVU_DTC_Mode : 26|6@1+ (1,0) [0|63] "" Vector__XXX
   SG_ HU_TempUnit : 36|4@1+ (1,0) [0|15] "" Vector__XXX

BO_ 1239 HU_Car_PE: 8 Vector__XXX
   SG_ HU_VehiclePwr : 4|4@1+ (1,0) [0|15] "" Vector__XXX
   SG_ HU_BtnShowReq : 8|8@1+ (1,0) [0|255] "" Vector__XXX

BO_ 1240 CLUSTER_INFO_1240: 8 Vector__XXX
   SG_ DISTANCE_UNIT : 0|1@1+ (1,0) [0|1] "" Vector__XXX

BO_ 1245 AMP_HU_E_08_AMP_CLUinfo_OutputCh: 8 Vector__XXX
   SG_ HU_EV_GpsSched_State : 26|6@1+ (1,0) [0|63] "" Vector__XXX
   SG_ HU_LatchHoldReq_EV_PE : 34|6@1+ (1,0) [0|63] "" Vector__XXX

BO_ 1247 HU_NAVI_PE: 8 Vector__XXX
   SG_ Navi_AirConditionWarning : 18|6@1+ (1,0) [0|63] "" Vector__XXX
   SG_ Navi_AirConditionType : 24|8@1+ (1,0) [0|255] "" Vector__XXX

BO_ 1253 IEB_01_10ms_2_IEB_InhbtTrnstnTo4wd: 8 Vector__XXX
   SG_ Auth_Req : 35|23@1+ (1,0) [0|8.38861e+06] "" Vector__XXX
   SG_ SecureCom_Req : 58|6@1+ (1,0) [0|63] "" Vector__XXX

BO_ 1257 HU_GW_P_1257: 8 Vector__XXX
   SG_ CF_Tmu_RoadType2 : 0|4@1+ (1,0) [0|15] "" Vector__XXX
   SG_ CF_Tmu_RoadType1 : 4|20@1+ (1,0) [0|1.04858e+06] "" Vector__XXX
   SG_ CF_Tmu_RoadType4 : 24|4@1+ (1,0) [0|15] "" Vector__XXX
   SG_ CF_Tmu_RoadType3 : 28|24@1+ (1,0) [0|1.67772e+07] "" Vector__XXX
   SG_ CF_Tmu_RoadType5 : 52|4@1+ (1,0) [0|15] "" Vector__XXX

BO_ 1258 HU_GW_P_1258: 8 Vector__XXX
   SG_ CF_Tmu_RoadType7 : 0|4@1+ (1,0) [0|15] "" Vector__XXX
   SG_ CF_Tmu_RoadType6 : 4|20@1+ (1,0) [0|1.04858e+06] "" Vector__XXX
   SG_ CF_Tmu_RoadType9 : 24|4@1+ (1,0) [0|15] "" Vector__XXX
   SG_ CF_Tmu_RoadType8 : 28|24@1+ (1,0) [0|1.67772e+07] "" Vector__XXX
   SG_ CF_Tmu_RoadType10 : 52|4@1+ (1,0) [0|15] "" Vector__XXX

BO_ 1260 HU_GW_P_1260: 8 Vector__XXX
   SG_ CR_Tmu_DrvDistance1 : 0|10@1+ (1,0) [0|1023] "" Vector__XXX
   SG_ CR_Tmu_DrvDistance2 : 10|10@1+ (1,0) [0|1023] "" Vector__XXX
   SG_ CR_Tmu_DrvDistance3 : 20|10@1+ (1,0) [0|1023] "" Vector__XXX
   SG_ CR_Tmu_DrvDistance4 : 30|10@1+ (1,0) [0|1023] "" Vector__XXX
   SG_ CR_Tmu_DrvDistance5 : 40|10@1+ (1,0) [0|1023] "" Vector__XXX
   SG_ CR_Tmu_DrvDistance6 : 50|6@1+ (1,0) [0|63] "" Vector__XXX

BO_ 1262 HU_EV_P_1262: 8 Vector__XXX
   SG_ CR_HU_EconStMin_WeedDay : 0|3@1+ (1,0) [0|7] "" Vector__XXX
   SG_ CR_HU_EconStHr_WeekDay : 3|5@1+ (1,0) [0|31] "" Vector__XXX
   SG_ CR_HU_EconEndMin_WeekDay : 8|3@1+ (1,0) [0|7] "" Vector__XXX
   SG_ CR_HU_EconEndHr_WeekDay : 11|27@1+ (1,0) [0|1.34218e+08] "" Vector__XXX
   SG_ CR_HU_ChgCtrMode : 38|2@1+ (1,0) [0|3] "" Vector__XXX

BO_ 1263 HU_EV_P_1263: 8 Vector__XXX
   SG_ CR_HU_DepartSet1_Min : 0|3@1+ (1,0) [0|7] "" Vector__XXX
   SG_ CR_HU_DepartSet1_Hour : 3|5@1+ (1,0) [0|31] "" Vector__XXX
   SG_ CF_HU_DepartSet1_Enable : 8|1@1+ (1,0) [0|1] "" Vector__XXX
   SG_ CF_HU_DepartSet1_Sun : 9|1@1+ (1,0) [0|1] "" Vector__XXX
   SG_ CF_HU_DepartSet1_Sat : 10|1@1+ (1,0) [0|1] "" Vector__XXX
   SG_ CF_HU_DepartSet1_Fri : 11|1@1+ (1,0) [0|1] "" Vector__XXX
   SG_ CF_HU_DepartSet1_Thu : 12|1@1+ (1,0) [0|1] "" Vector__XXX
   SG_ CF_HU_DepartSet1_Wed : 13|1@1+ (1,0) [0|1] "" Vector__XXX
   SG_ CF_HU_DepartSet1_Tue : 14|1@1+ (1,0) [0|1] "" Vector__XXX
   SG_ CF_HU_DepartSet1_Mon : 15|1@1+ (1,0) [0|1] "" Vector__XXX
   SG_ CR_HU_DepartSet2_Min : 16|3@1+ (1,0) [0|7] "" Vector__XXX
   SG_ CR_HU_DepartSet2_Hour : 19|5@1+ (1,0) [0|31] "" Vector__XXX
   SG_ CF_HU_DepartSet2_Enable : 24|1@1+ (1,0) [0|1] "" Vector__XXX
   SG_ CF_HU_DepartSet2_Sun : 25|1@1+ (1,0) [0|1] "" Vector__XXX
   SG_ CF_HU_DepartSet2_Sat : 26|1@1+ (1,0) [0|1] "" Vector__XXX
   SG_ CF_HU_DepartSet2_Fri : 27|1@1+ (1,0) [0|1] "" Vector__XXX
   SG_ CF_HU_DepartSet2_Thu : 28|1@1+ (1,0) [0|1] "" Vector__XXX
   SG_ CF_HU_DepartSet2_Wed : 29|1@1+ (1,0) [0|1] "" Vector__XXX
   SG_ CF_HU_DepartSet2_Tue : 30|1@1+ (1,0) [0|1] "" Vector__XXX
   SG_ CF_HU_DepartSet2_Mon : 31|1@1+ (1,0) [0|1] "" Vector__XXX
   SG_ CF_HU_DepartSet1_TempUnit : 32|1@1+ (1,0) [0|1] "" Vector__XXX
   SG_ CR_HU_DepartSet1_TempSet : 33|6@1+ (1,0) [0|63] "" Vector__XXX
   SG_ CF_HU_DepartSet1_PreCondSet : 39|8@1+ (1,0) [0|255] "" Vector__XXX
   SG_ CF_HU_DepartSet1_DefrostCtr : 47|1@1+ (1,0) [0|1] "" Vector__XXX

BO_ 1265 HU_GW_PE: 8 Vector__XXX
   SG_ AMP_UpdateIGNIhn : 0|11@1+ (1,0) [0|2047] "" Vector__XXX
   SG_ HU_Background_Time_Info : 8|2@1+ (1,0) [0|3] "" Vector__XXX
   SG_ C_FRU_Option_Info : 10|6@1+ (1,0) [0|63] "" Vector__XXX
   SG_ HU_RrStRemindOffSetReq : 11|5@1+ (1,0) [0|31] "" Vector__XXX
   SG_ HU_IG3_Request : 12|6@1+ (1,0) [0|63] "" Vector__XXX
   SG_ HU_Background : 18|3@1+ (1,0) [0|7] "" Vector__XXX
   SG_ ccIC_HUD_PbackSta : 21|3@1+ (1,0) [0|7] "" Vector__XXX
   SG_ HU_BackgroundFadeInOut : 24|8@1+ (1,0) [0|255] "" Vector__XXX

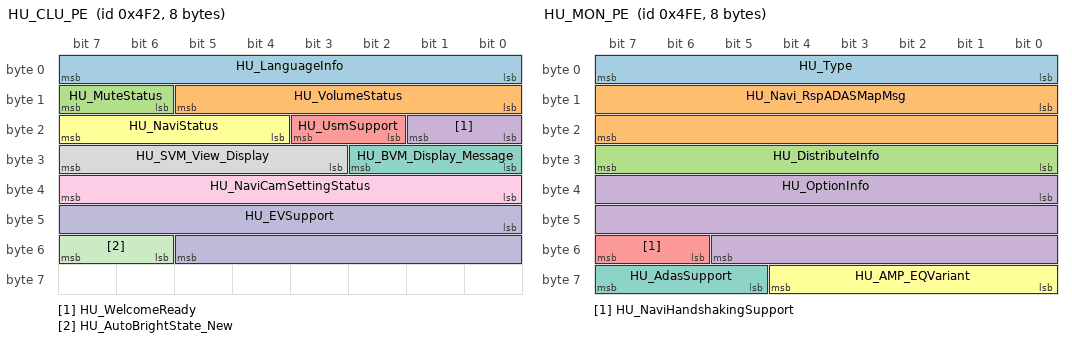
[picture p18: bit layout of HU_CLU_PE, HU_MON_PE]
BO_ 1266 HU_CLU_PE: 8 Vector__XXX
   SG_ HU_LanguageInfo : 0|8@1+ (1,0) [0|255] "" Vector__XXX
   SG_ HU_VolumeStatus : 8|6@1+ (1,0) [0|63] "" Vector__XXX
   SG_ HU_MuteStatus : 14|2@1+ (1,0) [0|3] "" Vector__XXX
   SG_ HU_WelcomeReady : 16|2@1+ (1,0) [0|3] "" Vector__XXX
   SG_ HU_UsmSupport : 18|2@1+ (1,0) [0|3] "" Vector__XXX
   SG_ HU_NaviStatus : 20|4@1+ (1,0) [0|15] "" Vector__XXX
   SG_ HU_BVM_Display_Message : 24|3@1+ (1,0) [0|7] "" Vector__XXX
   SG_ HU_SVM_View_Display : 27|5@1+ (1,0) [0|31] "" Vector__XXX
   SG_ HU_NaviCamSettingStatus : 32|8@1+ (1,0) [0|255] "" Vector__XXX
   SG_ HU_EVSupport : 40|14@1+ (1,0) [0|16383] "" Vector__XXX
   SG_ HU_AutoBrightState_New : 54|2@1+ (1,0) [0|3] "" Vector__XXX

BO_ 1267 DATC_08_200ms: 8 Vector__XXX
   SG_ RSELockOnOff_PE : 0|36@1+ (1,0) [0|6.87195e+10] "" Vector__XXX
   SG_ HU_DATC_DisplayThemes : 14|2@1+ (1,0) [0|3] "" Vector__XXX
   SG_ DATC_AlvCnt8Val : 16|10@1+ (1,0) [0|1023] "" Vector__XXX
   SG_ DATC_SmrtVntOnOffSta : 26|2@1+ (1,0) [0|3] "" Vector__XXX
   SG_ DATC_PsAutoDis : 28|4@1+ (1,0) [0|15] "" Vector__XXX
   SG_ DATC_RrAutoDis : 32|8@1+ (1,0) [0|255] "" Vector__XXX
   SG_ HU_PhoneActivity_PE : 36|2@1+ (1,0) [0|3] "" Vector__XXX
   SG_ HU_VRActivity_PE : 38|2@1+ (1,0) [0|3] "" Vector__XXX
   SG_ DATC_RrDrvModDis : 40|10@1+ (1,0) [0|1023] "" Vector__XXX
   SG_ DATC_DisplayThemes : 50|6@1+ (1,0) [0|63] "" Vector__XXX
   SG_ DATC_AUTOStepPS : 56|3@1+ (1,0) [0|7] "" Vector__XXX
   SG_ DATC_AUTOStepRR : 59|5@1+ (1,0) [0|31] "" Vector__XXX

BO_ 1278 HU_MON_PE: 8 Vector__XXX
   SG_ HU_Type : 0|8@1+ (1,0) [0|255] "" Vector__XXX
   SG_ HU_Navi_RspADASMapMsg : 8|16@1+ (1,0) [0|65535] "" Vector__XXX
   SG_ HU_DistributeInfo : 24|8@1+ (1,0) [0|255] "" Vector__XXX
   SG_ HU_OptionInfo : 32|22@1+ (1,0) [0|4.1943e+06] "" Vector__XXX
   SG_ HU_NaviHandshakingSupport : 54|2@1+ (1,0) [0|3] "" Vector__XXX
   SG_ HU_AMP_EQVariant : 56|5@1+ (1,0) [0|31] "" Vector__XXX
   SG_ HU_AdasSupport : 61|3@1+ (1,0) [0|7] "" Vector__XXX

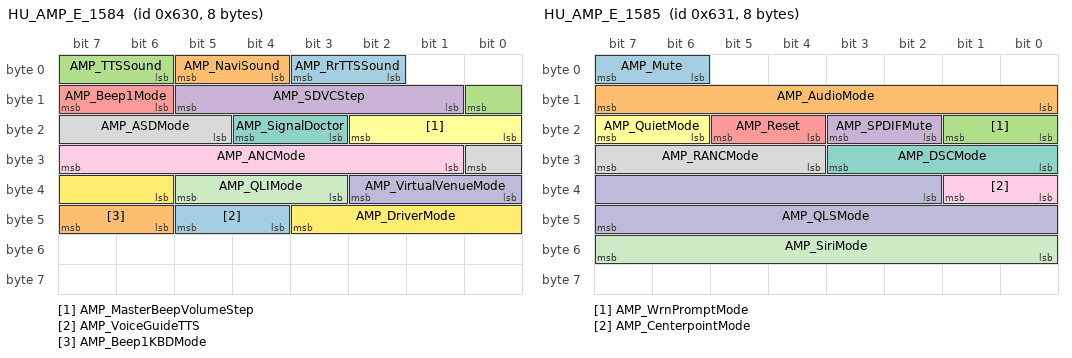
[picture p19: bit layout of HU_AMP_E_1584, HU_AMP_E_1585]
BO_ 1584 HU_AMP_E_1584: 8 Vector__XXX
   SG_ AMP_RrTTSSound : 2|2@1+ (1,0) [0|3] "" Vector__XXX
   SG_ AMP_NaviSound : 4|2@1+ (1,0) [0|3] "" Vector__XXX
   SG_ AMP_TTSSound : 6|3@1+ (1,0) [0|7] "" Vector__XXX
   SG_ AMP_SDVCStep : 9|5@1+ (1,0) [0|31] "" Vector__XXX
   SG_ AMP_Beep1Mode : 14|2@1+ (1,0) [0|3] "" Vector__XXX
   SG_ AMP_MasterBeepVolumeStep : 16|3@1+ (1,0) [0|7] "" Vector__XXX
   SG_ AMP_SignalDoctor : 19|2@1+ (1,0) [0|3] "" Vector__XXX
   SG_ AMP_ASDMode : 21|4@1+ (1,0) [0|15] "" Vector__XXX
   SG_ AMP_ANCMode : 25|7@1+ (1,0) [0|127] "" Vector__XXX
   SG_ AMP_VirtualVenueMode : 32|3@1+ (1,0) [0|7] "" Vector__XXX
   SG_ AMP_QLIMode : 35|3@1+ (1,0) [0|7] "" Vector__XXX
   SG_ AMP_DriverMode : 38|6@1+ (1,0) [0|63] "" Vector__XXX
   SG_ AMP_VoiceGuideTTS : 44|2@1+ (1,0) [0|3] "" Vector__XXX
   SG_ AMP_Beep1KBDMode : 46|2@1+ (1,0) [0|3] "" Vector__XXX

BO_ 1585 HU_AMP_E_1585: 8 Vector__XXX
   SG_ AMP_Mute : 6|2@1+ (1,0) [0|3] "" Vector__XXX
   SG_ AMP_AudioMode : 8|8@1+ (1,0) [0|255] "" Vector__XXX
   SG_ AMP_WrnPromptMode : 16|2@1+ (1,0) [0|3] "" Vector__XXX
   SG_ AMP_SPDIFMute : 18|2@1+ (1,0) [0|3] "" Vector__XXX
   SG_ AMP_Reset : 20|2@1+ (1,0) [0|3] "" Vector__XXX
   SG_ AMP_QuietMode : 22|2@1+ (1,0) [0|3] "" Vector__XXX
   SG_ AMP_DSCMode : 24|4@1+ (1,0) [0|15] "" Vector__XXX
   SG_ AMP_RANCMode : 28|4@1+ (1,0) [0|15] "" Vector__XXX
   SG_ AMP_CenterpointMode : 32|2@1+ (1,0) [0|3] "" Vector__XXX
   SG_ AMP_QLSMode : 34|14@1+ (1,0) [0|16383] "" Vector__XXX
   SG_ AMP_SiriMode : 48|8@1+ (1,0) [0|255] "" Vector__XXX

BO_ 1586 HU_AMP_E_1586: 8 Vector__XXX
   SG_ AMP_LogSnapshot : 0|2@1+ (1,0) [0|3] "" Vector__XXX
   SG_ VESS_LogSnapshot : 2|20@1+ (1,0) [0|1.04858e+06] "" Vector__XXX
   SG_ AMP_VersionReq : 22|2@1+ (1,0) [0|3] "" Vector__XXX

BO_ 1587 HU_AMP_E_1587: 8 Vector__XXX
   SG_ AMP_EngASDMasterGain : 0|8@1+ (1,0) [0|255] "" Vector__XXX
   SG_ AMP_Beep1Frequency : 8|8@1+ (1,0) [0|255] "" Vector__XXX

BO_ 1588 HU_AMP_E_1588: 8 Vector__XXX
   SG_ AMP_NaviVolumeStep : 0|8@1+ (1,0) [0|255] "" Vector__XXX
   SG_ ATS_Beep_OutputCh_Select : 8|16@1+ (1,0) [0|65535] "" Vector__XXX
   SG_ ATS_BeepVolumeStep : 24|8@1+ (1,0) [0|255] "" Vector__XXX
   SG_ ATS_BeepFrequency : 32|17@1+ (1,0) [0|131071] "" Vector__XXX
   SG_ AMP_ESEVMasterGain : 49|5@1+ (1,0) [0|31] "" Vector__XXX
   SG_ AMP_NaviVoice_Priority : 54|2@1+ (1,0) [0|3] "" Vector__XXX
   SG_ AMP_ESEVMode : 56|8@1+ (1,0) [0|255] "" Vector__XXX

BO_ 1589 HU_AMP_E_1589: 8 Vector__XXX
   SG_ AMP_MTSVolumeStep : 0|8@1+ (1,0) [0|255] "" Vector__XXX
   SG_ AMP_eASDMode : 8|3@1+ (1,0) [0|7] "" Vector__XXX
   SG_ AMP_eASDCstVolumeSet : 11|15@1+ (1,0) [0|32767] "" Vector__XXX
   SG_ AMP_eASDAPSSet : 26|6@1+ (1,0) [0|63] "" Vector__XXX
   SG_ AMP_eASDCstMode : 32|5@1+ (1,0) [0|31] "" Vector__XXX
   SG_ AMP_eASDCstReset : 37|3@1+ (1,0) [0|7] "" Vector__XXX

BO_ 1590 HU_AMP_E_1590: 8 Vector__XXX
   SG_ AMP_HFVolumeStep : 0|8@1+ (1,0) [0|255] "" Vector__XXX
   SG_ DVRS_Beep_OutputCh_Select : 8|16@1+ (1,0) [0|65535] "" Vector__XXX
   SG_ DVRS_BeepVolumeStep : 24|8@1+ (1,0) [0|255] "" Vector__XXX
   SG_ DVRS_BeepFrequency : 32|16@1+ (1,0) [0|65535] "" Vector__XXX
   SG_ AMP_SiriVolumeStep : 48|8@1+ (1,0) [0|255] "" Vector__XXX

BO_ 1591 HU_AMP_E_1591: 8 Vector__XXX
   SG_ AMP_MainVolumeSet : 0|8@1+ (1,0) [0|255] "" Vector__XXX
   SG_ AMP_BalanceSet : 8|8@1+ (1,0) [0|255] "" Vector__XXX
   SG_ AMP_FadeSet : 16|8@1+ (1,0) [0|255] "" Vector__XXX
   SG_ AMP_BassSet : 24|8@1+ (1,0) [0|255] "" Vector__XXX
   SG_ AMP_MidSet : 32|8@1+ (1,0) [0|255] "" Vector__XXX
   SG_ AMP_TrebleSet : 40|8@1+ (1,0) [0|255] "" Vector__XXX

BO_ 1593 HU_AMP_E_1593: 8 Vector__XXX
   SG_ DATC_Beep1_OutputCh_Select : 8|16@1+ (1,0) [0|65535] "" Vector__XXX
   SG_ DATC_Beep1VolumeStep : 24|8@1+ (1,0) [0|255] "" Vector__XXX
   SG_ DATC_Beep1Frequency : 32|8@1+ (1,0) [0|255] "" Vector__XXX

BO_ 1597 HU_AMP_P: 8 Vector__XXX
   SG_ AMP_SetMaxMainVolStep : 14|2@1+ (1,0) [0|3] "" Vector__XXX

CM_ SG_ 938 Port_Open "Verified on an EV6 against CAN logs and live: charge port door. Set to Open as soon as the door starts opening. Does not change when a charger is plugged in or charging.";
CM_ SG_ 1043 HAZARD_ON "Verified on an EV6 against CAN logs: 1 while the hazard switch is on.";
CM_ SG_ 843 Headlight_Switch "Wrong on an EV6: steps through every value once a second whatever the switch position. The switch position is not on this bus; BCM_07_200ms has the lamp outputs.";
CM_ SG_ 550 Outdoor_Temperature "Verified on an EV6 against CAN logs: matches the dashboard outside temperature while the car displays Celsius; Not_Available (255) while it displays Fahrenheit, then ODOMETER Outdoor_Temperature_F has it.";
CM_ SG_ 551 Odometer "Verified on an EV6 against CAN logs: matches the dashboard odometer. Stays in km when the car displays miles.";
CM_ SG_ 764 State_Of_Charge "Verified on an EV6 against CAN logs and live: matches the dashboard SOC.";
CM_ BO_ 412 "Verified on an EV6 against CAN logs and Car Scanner: the limits the car sets for the onboard charger (Car Scanner's ICCU VCMS Charge Mode values), not measurements. With the car idle (log_42) Car Scanner showed 825.6 V and two 0 A limits; on L2 (log_46) 825.6 V, 21 A DC and 11.9 A AC, as here. All zeros for the first frames after the car wakes up. The measured AC voltage and current (239.5 V, 11.31 A in log_46) are not on this bus.";
CM_ SG_ 412 DC_Target_Voltage "Verified on an EV6 against CAN logs and Car Scanner: 825.6 V in every log, idle, driving and charging.";
CM_ SG_ 412 DC_Current_Limit "Verified on an EV6 against CAN logs and Car Scanner: limit on the onboard charger's DC output, 21.0 A on L2 (log_46). Ramps up from 0 over about 2 s when L2 charging starts and drops to 0 when it stops; 0 on DC fast charging and idle (0.8 A in log_31 to log_34).";
CM_ SG_ 412 AC_Current_Limit "Verified on an EV6 against CAN logs and Car Scanner: AC input current limit, 11.9 A on a 240 V 15 A circuit (Car Scanner 11.9 A, log_46), now and then 12.0 A; 12.3-12.4 A from plug-in until charging starts, 0 on DC fast charging and idle. 0x30D byte 5 carries the same values.";
CM_ SG_ 413 Charger_Type "Verified on an EV6 against CAN logs: charger type. The car tries DC first, so it reads DC for the first seconds on an AC charger, then None, then AC about 7 s after plug-in.";
CM_ SG_ 413 DC_Sequence_Stage "Verified on an EV6 against CAN logs: DC charging sequence. 1 plugged in, 2 and 3 talking to the charger, 4 ready, 5 starting, 6 charging, 8 to 11 ending. An AC charger goes from 1 straight to 9 to 11 while the car gives up on DC; stages 2 to 6 mean the charger really is DC.";
CM_ SG_ 780 Proximity_Voltage "Verified on an EV6 against CAN logs: charge inlet proximity voltage. About 4.4 V unplugged, 1.5 V plugged in and latched, 2.7 V while the plug release button is pressed. AC and DC.";
CM_ SG_ 780 Plug_Connected "Verified on an EV6 against CAN logs: 1 while a charging cable is plugged in, AC or DC. Changes right at plug-in and unplug.";
CM_ SG_ 806 AC_Charger "Verified on an EV6 against CAN logs: 1 once the car has recognised an AC charger, about 7 s after plug-in. Never set on DC.";
CM_ SG_ 806 Charging "Verified on an EV6 against CAN logs: 1 while energy flows into the battery, AC or DC.";
CM_ SG_ 764 Battery_Current "Verified on an EV6 against CAN logs: high-voltage battery current, positive when discharging. Times Battery_Voltage it matches CHARGING_POWER on DC (within 1 kW) and gives 2.2 kW into the battery on a 2.6-2.7 kW L2 charger. Peaks at +198 A on a hard launch and -57 A in regen.";
CM_ SG_ 567 Battery_Voltage "Verified on an EV6 against CAN logs: high-voltage battery voltage. About 702 V at rest at 42% SOC, rises to 760 V while DC charging and sags under load.";
CM_ SG_ 54 Ready "Verified on an EV6 against CAN logs: 1 while the car is ready to drive, in any gear; 0 when off, in accessory or on but not ready, and while charging with the car off. Drops when a DC charger is plugged in while ready, as the cluster does. Bit 30 is set with it, and bits 26 and 30 rise a few hundred ms before it at start-up.";
CM_ SG_ 54 Gear "Verified on an EV6 against CAN logs: selected gear, follows every shift in log_09 within about a second, including the brief Neutral between Drive and Reverse. Reads 0 (Park) with the car off, asleep or charging. Bit 36 next to it is cleared while the high-voltage system is live: ready, or charging. Undefined message 0x039 byte 0 carries the same values but reads 9 while the car is off or charging.";
CM_ SG_ 54 Drive_Mode "Verified on an EV6 against CAN logs: active drive mode, changes as the mode button is pressed. Reads 0 (Eco) with the car off. Snow reads 5 (the Normal bits plus bit 60).";
CM_ SG_ 695 Range "Verified on an EV6 against CAN logs: range shown on the cluster, for the active drive mode only; the other modes are not sent. Stays in km when the car displays miles. Bit 11 of the message blips for about 2 s when a navigation route starts or stops.";
CM_ BO_ 818 "Verified on an EV6 against CAN logs: the car's estimate for a DC fast charge, always whole minutes, sent all the time (also driving and while AC charging); 0 with the car off. Matches the cluster while DC charging. For the charge in progress use CHARGING_TIME.";
CM_ SG_ 818 Charge_Time_To_Limit "Seconds for a DC fast charge to the DC limit (100% in all logs, so it may be to 100%).";
CM_ SG_ 818 Charge_Time_To_80 "Verified on an EV6 against CAN logs: seconds for a DC fast charge to 80%, as the cluster shows next to the time to the limit while DC charging.";
CM_ SG_ 1144 DRIVE_MODE "Wrong on an EV6: barely sent and the values make no sense. Use DRIVE_MODE_STATUS Drive_Mode.";
CM_ SG_ 428 Speed_kph "Verified on an EV6 against CAN logs with timed notes: speed in km/h, also while the car displays miles (log_32: 17-18 where the cluster showed 10 mph | 17 km/h), like the range and odometer. CLUSTER_DISPLAY_UNITS Display_Speed has it in the display unit.";
CM_ SG_ 795 Steering_Wheel_Heating_State "Wrong on an EV6: toggles about once a second whatever the heater does. Use ICU_08_200ms HSWS_SysWrngSta_ICU.";
CM_ SG_ 795 Climate_AC_State "Not the A/C state: 0 at a time the A/C was on, follows the A/C button but also changes with Auto and Heat. Use DATC_05_200ms DATC_AcDis.";
CM_ SG_ 795 Climate_Fan_Speed "Verified on an EV6 against CAN logs: blower level plus one (manual levels 1 to 8 read 2 to 9), 0 with the climate off; follows the blower in Auto.";
CM_ SG_ 795 Climate_Airflow_Direction "Verified on an EV6 against CAN logs.";
CM_ SG_ 795 Climate_Recirculation_State "Verified on an EV6 against CAN logs: recirculation on or off.";
CM_ SG_ 896 Driver_Temp_C "Verified on an EV6 against CAN logs: driver target temperature.";
CM_ SG_ 896 Passenger_Temp_C "Verified on an EV6 against CAN logs: passenger target temperature; OFF while Driver only is on.";
CM_ SG_ 896 Driver_Temp_F "Not Fahrenheit on a car set to Celsius: repeats the Driver_Temp_C steps. Not checked in Fahrenheit.";
CM_ SG_ 896 Passenger_Temp_F "Not Fahrenheit on a car set to Celsius: repeats the Passenger_Temp_C steps. Not checked in Fahrenheit.";
CM_ SG_ 593 Rear_Defrost_State "Wrong on an EV6: toggles every few seconds whatever the rear defroster does. No rear defroster state on this bus (nothing changed with it on for 27 s).";
CM_ SG_ 685 Battery_Precond_State "Verified on an EV6 against CAN logs: battery preconditioning. Preparing at the request; On when the battery heater switches on (about 60 s later, varies), which is when the cluster shows the battery icon. 2 while the car is off, asleep or charging.";
CM_ SG_ 1174 Driver_Seat_Heating_Oper "Verified on an EV6 against CAN logs: driver seat heating level. 3 to 5 may be ventilation (not checked).";
CM_ SG_ 1141 Passenger_Seat_Heating_Oper "Verified on an EV6 against CAN logs: passenger seat heating level. 3 to 5 may be ventilation (not checked).";
CM_ SG_ 1261 Precond_Request "Not an on/off request: 0x1F with bytes 5-6 at FF FF when no route is set, and route data (e.g. 08 48 00) when navigating to a DC charger, about 6 s before preconditioning starts. Probably route information for the BMU; the old value table (31 = On, 0 = Off) was backwards. wicant-i-precondition (github.com/L1Z3/wicant-i-precondition) overwrites bytes 5-7 with 10 A0 00 while it keeps preconditioning on. OpenCarControls sends a copy of each head-unit frame with those bytes, right after it, during its manual preconditioning (a tap cannot replace the frame).";
CM_ SG_ 605 Cand_Heater_Power_25D "Candidate from EV6 CAN logs: 45-46 while the battery heater runs during preconditioning, matching the extra ~4.5 kW drawn from the battery, so probably 0.1 kW steps; 0 otherwise. Only seen in summer, so cabin heating may use it too.";
CM_ SG_ 337 AC_Charge_Limit "Verified on an EV6 against CAN logs with timed notes: AC charge limit set in the head unit, applied about 3 s after the change. 0x1F9 bytes 2-3 carry the same pair.";
CM_ SG_ 337 DC_Charge_Limit "Verified on an EV6 against CAN logs with timed notes: DC charge limit set in the head unit.";
CM_ SG_ 435 Cabin_Temperature "Verified on an EV6 against CAN logs with a thermometer next to the cabin sensor: about 1 C above it (10 to 20 C while heating); drops with the climate off.";
CM_ SG_ 504 Charging_Time_To_Limit "Verified on an EV6 against CAN logs with timed notes: minutes to the charge limit for the charge in progress, AC and DC, as the cluster shows; 0 when not charging. Byte 6 was only set once (420 min).";
CM_ SG_ 551 Outdoor_Temperature_F "Verified on an EV6 against CAN logs: outside temperature while the car displays Fahrenheit (44.5 F for 45 F shown, 7 C); 255 while it displays Celsius.";
CM_ SG_ 898 DATC_TempDispUnitSta "Verified on an EV6 against CAN logs with timed notes: temperature display unit.";
CM_ BO_ 162 "Wheel mapping (FL, FR, RL, RR) is assumed and requires live verification.";
CM_ SG_ 764 Battery_Min_Temperature "Verified on an EV6 against CAN logs and Car Scanner: lowest battery module temperature, 12 C where Car Scanner showed 12 C (log_31); rises from 26 to 29 C during a DC fast charge (log_21). Never below 8 C in the logs, so the sign is assumed. BATTERY_TEMPERATURES_152 byte 0 carries the same value.";
CM_ SG_ 764 Battery_Max_Temperature "Verified on an EV6 against CAN logs and Car Scanner: highest battery module temperature, 13 C where Car Scanner showed 13 C (log_31); rises from 28 to 31 C during a DC fast charge (log_21), always at or above Battery_Min_Temperature. CHARGE_LIMITS byte 7 carries the same value.";
CM_ SG_ 764 Aux_Battery_Voltage "Verified on an EV6 against CAN logs and Car Scanner: 12 V battery voltage. 13.5-14.3 V while the car is on or charging (DC-DC converter running), falls to about 12.1 V within seconds of switching off and climbs back when charging starts (log_31). Car Scanner read 13.9 V at the OBD port when this read 13.6 V. Reads 0 for one frame while the car switches off.";
CM_ SG_ 337 Battery_Max_Temperature_Copy "Checked on an EV6 against CAN logs: same value as BATTERY_INFO_764 Battery_Max_Temperature, changing at the same moments in log_21.";
CM_ BO_ 338 "Checked on an EV6 against CAN logs: battery temperatures, changing slowly during a DC fast charge (log_21).";
CM_ SG_ 338 Battery_Min_Temperature_Copy "Checked on an EV6 against CAN logs: same value as BATTERY_INFO_764 Battery_Min_Temperature.";
CM_ SG_ 338 Cand_Battery_Temp_152_8 "Candidate from EV6 CAN logs: between the battery minimum and maximum temperatures (13 C at 12/13 C in log_31, 27-30 C during a DC charge in log_21). Maybe a coolant or average temperature; Car Scanner showed 12 C coolant, which doesn't tell it apart. wicant-i-precondition (github.com/L1Z3/wicant-i-precondition) reads it as the battery maximum, which the EV6 logs contradict.";
CM_ SG_ 338 Cand_Battery_Temp_152_16 "Candidate from EV6 CAN logs: like Cand_Battery_Temp_152_8 (12 C in log_31, 27-30 C in log_21).";
CM_ SG_ 427 Distance_Unit "Verified on an EV6 against CAN logs with timed notes: distance display unit, set when switching to miles and cleared when switching back to km (log_30 at 6:52 and 7:11).";
CM_ SG_ 427 Display_Speed "Verified on an EV6 against CAN logs with timed notes: speed in the display unit, 0.5 steps. In km/h it is twice CLUSTER_INFO_428 Speed_kph (65 km/h reads 130); in miles it matched the seven mph readings in log_32. Byte 7 has always been 0, but no log goes above 119 km/h, so the 16-bit width is assumed: the car goes faster than the 127.5 that byte 6 alone can hold.";
CM_ BO_ 738 "Verified on an EV6 against CAN logs with a video of the cluster (log_32): regenerative braking level and Auto.";
CM_ SG_ 738 Regen_Auto "Verified on an EV6 against CAN logs with a video of the cluster: 1 while the paddles are in Auto regen (log_32 from 1:28 to 1:52), 0 for fixed levels and i-Pedal.";
CM_ SG_ 738 Regen_Level "Verified on an EV6 against CAN logs with a video of the cluster: regen strength, 0 to 3 for the paddle levels and 4 for the maximum (i-Pedal, or the maximum without i-Pedal). In Auto it moves smoothly between them (0.1, 0.8, 1.9 seen) and the cluster numbers the steps one higher (Auto level 1 to 5). Not_Available with the car off and while smart cruise drives the car. Resets to 3 in Park and Reverse.";
CM_ SG_ 739 I_Pedal "Verified on an EV6 against CAN logs with a video of the cluster: 1 in i-Pedal, 0 at fixed levels, in Auto and at the maximum level without i-Pedal (log_32 1:52 to 1:56). Keeps its last value with the car off.";
CM_ BO_ 929 "Verified on an EV6 against CAN logs with the cluster's tire screen: tire pressures in the unit chosen for the cluster, TIRE_PRESSURE_UNIT: whole psi (35/34), kPa / 5 (48/46 = 240/230 kPa) or bar x 10 (24/23 = 2.4/2.3 bar), switched through all three in log_40 at 0:32-0:53. Not_Available until the sensors report, a minute or two into a drive. Front left (log_33, deflated to 32 psi) and rear left (log_34, 36 psi) are confirmed; front right and rear right are assumed from the usual order, as neither was ever set apart. Bytes 0-1 hold a 14-bit CRC.";
CM_ SG_ 929 Tire_Pressure_FL "Verified on an EV6 against CAN logs with the cluster's tire screen: front left (dropped from 35 to 32 psi when only that tire was deflated, log_33).";
CM_ SG_ 929 Tire_Pressure_FR "Assumed front right from the usual wheel order; never set apart from the others.";
CM_ SG_ 929 Tire_Pressure_RL "Verified on an EV6 against CAN logs with the cluster's tire screen: rear left (toggled 35/36 psi with the cluster's rear left, log_34).";
CM_ SG_ 929 Tire_Pressure_RR "Assumed rear right from the usual wheel order; never set apart from the others.";
CM_ BO_ 930 "Verified on an EV6 against CAN logs: sent every 200 ms with TIRE_PRESSURES. Byte 0 is 0 or 1 depending on the log, meaning unknown.";
CM_ SG_ 930 Tire_Pressure_Unit "Verified on an EV6 against CAN logs: the tire pressure unit set for the cluster, which TIRE_PRESSURES uses (log_40: psi, kPa, bar, then the same again at 0:32-0:53). Always psi in the other logs.";
CM_ BO_ 1138 "Verified on an EV6 against CAN logs: sent every 200 ms. Bytes 0-1 change with the content, maybe a checksum.";
CM_ SG_ 1138 Efficiency_Unit "Verified on an EV6 against CAN logs: the energy efficiency unit shown. km/kWh at 1:02-1:07 in log_40; mi/kWh whenever the distance unit is miles (log_30 at 6:51-7:10, where the cluster showed 3.2 mi/kWh, and log_32 until 3:27); kWh/100 km otherwise.";
CM_ BO_ 1264 "Verified on an EV6 against CAN logs: the head unit clock, local time with the date, sent every 250 ms and stepping once a second. Matches the date of all 53 captures (June to October) and the time each of log_01 to log_34 was saved (EDT). Reads all ones for the first frames after the car wakes up. Switching daylight saving on and off in the head unit only moves the hour, with no flag (log_40 at 1:23-1:41). Bit 38 (set) never changed.";
CM_ SG_ 1264 Hours "Verified on an EV6 against CAN logs: 0-23 whatever the clock format shown (also in 12 h, log_40 at 1:48-2:03).";
CM_ SG_ 1264 Clock_Format "Verified on an EV6 against CAN logs: the head unit's clock format (log_40: 12 h at 1:48-1:54 and 1:59-2:03, 24 h otherwise). Bit 57 is set along with 12 h.";
CM_ SG_ 1264 Year "Verified on an EV6 against CAN logs: 26 for 2026.";
CM_ BO_ 1259 "Verified on an EV6 against CAN logs: the same local time as LOCAL_TIME with the day of the week instead of the date, sent every 200 ms and stepping once a second, at most a second off LOCAL_TIME.";
CM_ SG_ 1259 Weekday "Verified on an EV6 against CAN logs: one bit per day, in the order of the departure-day bits of HU_EV_P_1263 (Sunday in bit 0 up to Monday in bit 6). Sunday, Saturday, Friday and Monday were captured; Tuesday to Thursday follow from that order.";
CM_ SG_ 1259 NEW_SIGNAL_3 "Unverified opendbc signal";
CM_ BO_ 1230 "Verified on an EV6 against CAN logs: head unit media status, sent about every 185 ms, its content changing once a second. Reads FE C3 then all FF while the car is off. Frames with bytes 4-5 at 28 04 or other odd values come in between around track changes; ignore them. The track text itself goes out over ISO-TP as UTF-16LE padded with AA, one CAN ID per source as listed by wicant-i-precondition (github.com/L1Z3/wicant-i-precondition). Verified on an EV6: Android Auto on 0x6D2 and radio on 0x6DC, the cluster answering 30 00 05 on 0x6B2 and 0x6BB. From that list: Bluetooth 0x6D4, CarPlay 0x6D6, USB 0x6EA, apps 0x6E0.";
CM_ SG_ 1230 Media_Source "Verified on an EV6 against CAN logs: Android Auto (0xDE) in every log with music, FM radio (0x22) and the audio switched off (0x14) in the popup tests of 2026-11-05, Off also in the captures without Bluetooth or Android Auto, and switching from Off to Android Auto when the phone connected (log_11). A change of source opens the cluster popup by itself. The other values come from wicant-i-precondition (github.com/L1Z3/wicant-i-precondition): 0x10/0x11 Bluetooth, 0x23 and 0x42-0x49 radio, 0xC4-0xCA USB, 0xDC/0xDD CarPlay.";
CM_ SG_ 1230 Media_Popup "Verified on an EV6 in the popup tests of 2026-11-05: 0x01 while the head unit is on, 0xC3 just after it starts, 0x11 for one or two frames at a track change, with the text about 0.4 s later. 0x11 opens the cluster popup for 4 s, 1 s of the source name, then 3 s of the text, and again within those 4 s extends it. Copies of the frame with 0x11 do the same (wicant-i-precondition, github.com/L1Z3/wicant-i-precondition). Text alone updates an open popup but doesn't extend or reopen it.";
CM_ SG_ 1230 Track_Seconds "Verified on an EV6 against CAN logs: playback position of the current track, back to 0 at each Android Auto title change on 0x6D2 and counting once a second. Counts 0-251, then Track_Seconds_High goes up by one (log_20, 4:12 into a track): position = Track_Seconds_High x 252 + Track_Seconds.";
CM_ SG_ 1230 Track_Seconds_High "Verified on an EV6 against CAN logs: see Track_Seconds. Only 0 and 1 seen (no track longer than about 8 min was played).";
CM_ BO_ 56 "Checked on an EV6 against CAN logs: power mode, the same state wicant-i-precondition (github.com/L1Z3/wicant-i-precondition) reads READY from. To investigate: it may be the high-voltage contactor or ICCU state rather than a plain power mode (3 looks like a precharge before Ready, 6 has the car awake for charging or a remote command), and byte 1 changes with each value (01/05 at 2, 0B/0C at 3, 00 at 4, 8x at 6). Not told apart yet from captures of remote commands, the 12 V top-up while asleep (orange ICCU light on the charge port) and V2L, ideally with Car Scanner showing the BMS relay status.";
CM_ SG_ 56 Power_Mode "Verified on an EV6 against CAN logs: 4 exactly while DRIVE_MODE_STATUS Ready is set (log_09, log_30), 1 when off. Candidate meanings for the rest: 2 on without Ready, 3 for a fraction of a second while switching to Ready, 6 awake while plugged in or for a remote command.";
CM_ BO_ 1256 "Verified on an EV6 against CAN logs: the route summary the cluster shows during built-in navigation (the destination name goes over ISO-TP on 0x6E7, prefixed with 0xF4). All FF except byte 3 without a route; Android Auto navigation does not use it.";
CM_ SG_ 1256 Distance_Unit "From wicant-i-precondition (github.com/L1Z3/wicant-i-precondition), which writes this message to show a countdown on the cluster; consistent with the EV6 logs (km in every route). Shown together with Distance_Tenths only in km or mi and below 100.";
CM_ SG_ 1256 Distance_Tenths "Checked on an EV6 against CAN logs: tenths of Distance (7.9, 5.2 and 9.3 km for the three routes in the logs).";
CM_ SG_ 1256 ETA_Hours "Verified on an EV6 against CAN logs: hour of the estimated arrival time, local time. 23:24 for a route set at 23:12:49 (log_30); while parked it moves a minute later every minute, like the arrival time does.";
CM_ SG_ 1256 ETA_Minutes "Verified on an EV6 against CAN logs: minutes of the estimated arrival time, see ETA_Hours.";
CM_ SG_ 1256 Cand_Nav_Route_24 "Candidate from EV6 CAN logs: without a route it steps by 3 as the car turns, like NAV_GUIDANCE Cand_Compass_Heading minus one; with a route 0x0B or 0x29, meaning unknown.";
CM_ SG_ 1256 Distance "From wicant-i-precondition (github.com/L1Z3/wicant-i-precondition) (written to the cluster), consistent with the EV6 logs: whole part of the distance left, in Distance_Unit; 65535 hides the number.";
CM_ SG_ 1256 Destination_Flag "From wicant-i-precondition (github.com/L1Z3/wicant-i-precondition) (written to the cluster), consistent with the EV6 logs (Destination in every route): flag icon next to the distance.";
CM_ BO_ 1228 "Candidate from EV6 CAN logs: the cluster turn-by-turn area. wicant-i-precondition (github.com/L1Z3/wicant-i-precondition) sets byte 0 to 0x02 to show the NAV_ROUTE distance.";
CM_ SG_ 1228 Cand_Guidance_Type "Candidate from EV6 CAN logs: 0x08 without a route; 0x0D or 0x02 with one, probably the next maneuver. 0x09 for a moment while a route starts.";
CM_ SG_ 1228 Cand_Compass_Heading "Candidate from EV6 CAN logs: without a route, 0-45 in steps of 3 following the car as it turns and wrapping from 45 to 0, so likely a 16-point compass heading; the direction of 0 is unknown.";
CM_ BO_ 418 "Checked on an EV6 against CAN logs: smart cruise control. Byte 0 also changes with it (0x14 engaged, 0x44 after a cancel), meaning unknown.";
CM_ SG_ 418 Cruise_State "Verified on an EV6 against CAN logs: 2 while cruise control is engaged, 0 otherwise (log_03, log_12, and the highway parts of log_20/22/24). 0x1A4 byte 1 leaves 07 at the same time.";
CM_ SG_ 418 Cruise_Set_Speed "Verified on an EV6 against CAN logs: the set speed. 70, then 60, then 50 km/h as set in log_12, stepping by 1 while the stalk is held; 50 in log_03. Stays at the last value after a cancel (Cruise_State 0) and reads 0 before cruise is first set. Only captured in km/h.";
CM_ BO_ 1255 "Candidate from EV6 CAN logs: speed limit, probably the one the cluster shows. 0x1FB bytes 4 and 5 carry the same values times two.";
CM_ SG_ 1255 Cand_Displayed_Speed_Limit "Candidate from EV6 CAN logs: 50, 70, 60, 30, 70, 50, 30 over log_12, changing with the road like HU_Navi_ISLW_PE Navi_ISLW_SpdLimit, but read 60 where the map said 30, so probably the camera-and-map limit the cluster shows. 0 when none is known. Not checked against the cluster.";
CM_ BO_ 1600 "Candidate from EV6 CAN logs: lane guidance, also without a route. Each countdown starts when 0x680 sends an ISO-TP frame F1 <lane count> 00 <one code per lane> and ends when 0x680 sends all zeros (10 drive logs).";
CM_ SG_ 1600 Cand_Junction_Distance "Candidate from EV6 CAN logs: distance to the next junction with lane guidance. Starts at 300 m or less, counts down in 10 m steps at the car's speed to 0-10, FF FF between junctions.";
CM_ SG_ 1600 Cand_Route_Active_640 "Candidate from EV6 CAN logs: 0x0A while a built-in navigation route is active, 0 otherwise.";
CM_ BO_ 763 "Requires more live testing. Behavior in charging logs is erratic.";
CM_ SG_ 1041 Passenger_Seatbelt_Fastened "Verified on an EV6 against CAN logs: front passenger seatbelt, follows all six buckles and unbuckles in log_05 within a second. The rear seatbelts and seat occupancy are not on this bus (log_05).";
CM_ SG_ 1041 Driver_Seatbelt_Fastened "Verified on an EV6 against CAN logs: driver seatbelt, follows all six buckles and unbuckles in log_05 within a second.";
CM_ SG_ 1041 Crc_Val "Unverified opendbc signal";
CM_ SG_ 1041 AlvCnt_Val "Unverified opendbc signal";
CM_ SG_ 938 Crc_Val "Unverified opendbc signal";
CM_ SG_ 938 AlvCnt_Val "Unverified opendbc signal";
CM_ SG_ 1044 Crc_Val "Unverified opendbc signal";
CM_ SG_ 1044 AlvCnt_Val "Unverified opendbc signal";
CM_ SG_ 1077 Crc_Val "Unverified opendbc signal";
CM_ SG_ 1077 AlvCnt_Val "Unverified opendbc signal";
CM_ SG_ 1042 Reverse_Lamp "Verified on an EV6 against CAN logs: 1 while in Reverse (reverse lights).";
CM_ SG_ 1042 Brake_Lamp "Verified on an EV6 against CAN logs: brake lights, 1 with the brake pedal pressed and also during strong regen without the pedal (log_15). Use ICU_08_200ms Brake_SwSta_ICU for the pedal itself. Was the 8-bit Brake_Pedal, which also caught the reverse lights.";
CM_ SG_ 100 Auto_Hold "Verified on an EV6 against CAN logs: Auto Hold switched On (48) or Off (4) with its button. The value while it is actively holding the car was not captured.";
CM_ SG_ 1077 Power_State "Checked on an EV6 against CAN logs: Car_on when on or ready, Car_Off when off or in accessory. Use BCM_02_200ms and DRIVE_MODE_STATUS Ready for the full power state.";
CM_ SG_ 593 Crc_Val "Unverified opendbc signal";
CM_ SG_ 593 AlvCnt_Val "Unverified opendbc signal";
CM_ SG_ 1096 Crc_Val "Unverified opendbc signal";
CM_ SG_ 1096 AlvCnt_Val "Unverified opendbc signal";
CM_ SG_ 1141 Passenger_Seat_Heating_Opt "Unverified opendbc signal";
CM_ SG_ 1174 Driver_Seat_Heating_Opt "Unverified opendbc signal";
CM_ SG_ 896 Crc_Val "Unverified opendbc signal";
CM_ SG_ 896 AlvCnt_Val "Unverified opendbc signal";
CM_ BO_ 199 "Checked on an EV6 against CAN logs: head unit requests to the BMU, sent in short bursts on events. wicant-i-precondition (github.com/L1Z3/wicant-i-precondition) sends this message to start (bytes 3-4 40 03, then E0 07) and stop (00 00, then E0 07) battery preconditioning, and to request utility mode (bytes 2-4 80 E0 07). OpenCarControls sends the same bursts for manual preconditioning: three frames 40 ms apart of each pattern, from a tap on M-CAN. Checked on an EV6 (2026-11-11): the start and the stop both work from the tap.";
CM_ SG_ 199 HU_V2LModeSet "Unverified opendbc signal";
CM_ SG_ 199 HU_V2GModeSet "Unverified opendbc signal";
CM_ SG_ 199 HU_V2XInstantRunSet "Unverified opendbc signal";
CM_ SG_ 199 HU_V2XDischrgLimSocValSet "Unverified opendbc signal";
CM_ SG_ 199 HU_EcoClmtLimSet "Unverified opendbc signal";
CM_ SG_ 199 HU_UtilModeSetReq "Unverified on our logs: wicant-i-precondition (github.com/L1Z3/wicant-i-precondition) sends 2 to request utility mode.";
CM_ SG_ 199 HU_ChgInCurrSet "Unverified opendbc signal";
CM_ SG_ 199 HU_EV_BatteryConditioning "Unverified opendbc signal";
CM_ SG_ 199 NAVI_precond_EVStationFlag "Verified on an EV6 against CAN logs: 2 when a route to a DC charger starts (preconditioning follows), 1 for a route home, 0 when the route is cancelled; each request is followed by 7. log_30, Idle - Nav captures.";
CM_ SG_ 199 NAVI_precond_EVStationType "Checked on an EV6 against CAN logs: 3 with a DC charger destination, 0 for other destinations or a cancel, 7 after each request.";
CM_ SG_ 199 HU_QckChrgCustomSet "Unverified opendbc signal";
CM_ BO_ 255 "Unverified: Imported from opendbc. Validation required.";
CM_ SG_ 255 BCM_Crc20Val "Unverified opendbc signal";
CM_ SG_ 255 BCM_AlvCnt20Val "Unverified opendbc signal";
CM_ SG_ 255 BCM_SafetyWdwOptTyp2 "Unverified opendbc signal";
CM_ BO_ 353 "Unverified: Imported from opendbc. Validation required.";
CM_ SG_ 353 CHECKSUM "Unverified opendbc signal";
CM_ SG_ 353 COUNTER "Unverified opendbc signal";
CM_ SG_ 353 FCA_ICON "Unverified opendbc signal";
CM_ SG_ 353 FCA_ALT_ICON "Unverified opendbc signal";
CM_ SG_ 353 LKA_ICON "Unverified opendbc signal";
CM_ SG_ 353 HBA_ICON "Unverified opendbc signal";
CM_ SG_ 353 ZEROS_1 "Unverified opendbc signal";
CM_ SG_ 353 ZEROS_2 "Unverified opendbc signal";
CM_ SG_ 353 FCA_IMAGE "Unverified opendbc signal";
CM_ SG_ 353 ZEROS_3 "Unverified opendbc signal";
CM_ SG_ 353 ZEROS_4 "Unverified opendbc signal";
CM_ SG_ 353 BCA_LEFT "Unverified opendbc signal";
CM_ SG_ 353 BCA_RIGHT "Unverified opendbc signal";
CM_ SG_ 353 LCA_LEFT_ARROW "Unverified opendbc signal";
CM_ SG_ 353 LCA_RIGHT_ARROW "Unverified opendbc signal";
CM_ SG_ 353 ZEROS_5 "Unverified opendbc signal";
CM_ SG_ 353 CENTERLINE "Unverified opendbc signal";
CM_ SG_ 353 TARGET "Unverified opendbc signal";
CM_ SG_ 353 TARGET_DISTANCE "Unverified opendbc signal";
CM_ SG_ 353 LANELINE_LEFT "Unverified opendbc signal";
CM_ SG_ 353 LANELINE_LEFT_POSITION "Unverified opendbc signal";
CM_ SG_ 353 LANELINE_RIGHT "Unverified opendbc signal";
CM_ SG_ 353 LANELINE_RIGHT_POSITION "Unverified opendbc signal";
CM_ SG_ 353 LANELINE_CURVATURE "Unverified opendbc signal";
CM_ SG_ 353 LANE_HIGHLIGHT "Unverified opendbc signal";
CM_ SG_ 353 LANE_HIGHLIGHT_DISTANCE "Unverified opendbc signal";
CM_ SG_ 353 LANE_LEFT "Unverified opendbc signal";
CM_ SG_ 353 LANE_RIGHT "Unverified opendbc signal";
CM_ SG_ 353 LANE_ZOOM "Unverified opendbc signal";
CM_ SG_ 353 ALERTS_1 "Unverified opendbc signal";
CM_ SG_ 353 ALERTS_2 "Unverified opendbc signal";
CM_ SG_ 353 ALERTS_3 "Unverified opendbc signal";
CM_ SG_ 353 ALERTS_4 "Unverified opendbc signal";
CM_ SG_ 353 ALERTS_5 "Unverified opendbc signal";
CM_ SG_ 353 MUTE "Unverified opendbc signal";
CM_ SG_ 353 SOUNDS_1 "Unverified opendbc signal";
CM_ SG_ 353 SOUNDS_2 "Unverified opendbc signal";
CM_ SG_ 353 SOUNDS_3 "Unverified opendbc signal";
CM_ SG_ 353 SOUNDS_4 "Unverified opendbc signal";
CM_ SG_ 353 ZEROS_6 "Unverified opendbc signal";
CM_ SG_ 353 ZEROS_7 "Unverified opendbc signal";
CM_ SG_ 353 SETSPEED_HUD "Unverified opendbc signal";
CM_ SG_ 353 DISTANCE_LEAD "Unverified opendbc signal";
CM_ SG_ 353 DISTANCE_CAR "Unverified opendbc signal";
CM_ SG_ 353 DISTANCE_SPACING "Unverified opendbc signal";
CM_ SG_ 353 DISTANCE "Unverified opendbc signal";
CM_ SG_ 353 SETSPEED_SPEED "Unverified opendbc signal";
CM_ SG_ 353 SETSPEED "Unverified opendbc signal";
CM_ SG_ 353 HDA_ICON "Unverified opendbc signal";
CM_ SG_ 353 SLA_ICON "Unverified opendbc signal";
CM_ SG_ 353 NAV_ICON "Unverified opendbc signal";
CM_ SG_ 353 LFA_ICON "Unverified opendbc signal";
CM_ SG_ 353 LCA_LEFT_ICON "Unverified opendbc signal";
CM_ SG_ 353 LCA_RIGHT_ICON "Unverified opendbc signal";
CM_ SG_ 353 BACKGROUND "Unverified opendbc signal";
CM_ SG_ 353 DAW_ICON "Unverified opendbc signal";
CM_ SG_ 353 CAR_CIRCLE "Unverified opendbc signal";
CM_ SG_ 353 ZEROS_8 "Unverified opendbc signal";
CM_ SG_ 353 ZEROS_9 "Unverified opendbc signal";
CM_ BO_ 354 "Unverified: Imported from opendbc. Validation required.";
CM_ SG_ 354 CHECKSUM "Unverified opendbc signal";
CM_ SG_ 354 COUNTER "Unverified opendbc signal";
CM_ SG_ 354 COUNTRY "Unverified opendbc signal";
CM_ SG_ 354 SPEEDLIMIT_FLASH "Unverified opendbc signal";
CM_ SG_ 354 SPEEDLIMIT "Unverified opendbc signal";
CM_ SG_ 354 SIGNS "Unverified opendbc signal";
CM_ SG_ 354 SPEEDLIMIT_WEATHER "Unverified opendbc signal";
CM_ SG_ 354 VIBRATE "Unverified opendbc signal";
CM_ SG_ 354 ZEROS_1 "Unverified opendbc signal";
CM_ SG_ 354 ZEROS_2 "Unverified opendbc signal";
CM_ SG_ 354 LEAD "Unverified opendbc signal";
CM_ SG_ 354 LEAD_DISTANCE "Unverified opendbc signal";
CM_ SG_ 354 LEAD_LATERAL "Unverified opendbc signal";
CM_ SG_ 354 ZEROS_3 "Unverified opendbc signal";
CM_ SG_ 354 LEAD_ALT "Unverified opendbc signal";
CM_ SG_ 354 LEAD_ALT_DISTANCE "Unverified opendbc signal";
CM_ SG_ 354 LEAD_ALT_LATERAL "Unverified opendbc signal";
CM_ SG_ 354 ZEROS_4 "Unverified opendbc signal";
CM_ SG_ 354 LEAD_LEFT "Unverified opendbc signal";
CM_ SG_ 354 LEAD_LEFT_DISTANCE "Unverified opendbc signal";
CM_ SG_ 354 LEAD_LEFT_LATERAL "Unverified opendbc signal";
CM_ SG_ 354 ZEROS_5 "Unverified opendbc signal";
CM_ SG_ 354 LEAD_RIGHT "Unverified opendbc signal";
CM_ SG_ 354 LEAD_RIGHT_DISTANCE "Unverified opendbc signal";
CM_ SG_ 354 LEAD_RIGHT_LATERAL "Unverified opendbc signal";
CM_ SG_ 354 ZEROS_6 "Unverified opendbc signal";
CM_ SG_ 354 ZEROS_7 "Unverified opendbc signal";
CM_ SG_ 354 LEAD_LEFT_REAR_STATUS "Unverified opendbc signal";
CM_ SG_ 354 LEAD_LEFT_REAR_DISTANCE "Unverified opendbc signal";
CM_ SG_ 354 LEAD_LEFT_REAR_LATERAL "Unverified opendbc signal";
CM_ SG_ 354 ZEROS_8 "Unverified opendbc signal";
CM_ SG_ 354 ZEROS_9 "Unverified opendbc signal";
CM_ SG_ 354 LEAD_RIGHT_REAR_STATUS "Unverified opendbc signal";
CM_ SG_ 354 LEAD_RIGHT_REAR_DISTANCE "Unverified opendbc signal";
CM_ SG_ 354 LEAD_RIGHT_REAR_LATERAL "Unverified opendbc signal";
CM_ SG_ 354 ZEROS_10 "Unverified opendbc signal";
CM_ SG_ 354 FAULT_FSS "Unverified opendbc signal";
CM_ SG_ 354 FAULT_FCA "Unverified opendbc signal";
CM_ SG_ 354 FAULT_LSS "Unverified opendbc signal";
CM_ SG_ 354 FAULT_SLA "Unverified opendbc signal";
CM_ SG_ 354 FAULT_DAW "Unverified opendbc signal";
CM_ SG_ 354 FAULT_HBA "Unverified opendbc signal";
CM_ SG_ 354 FAULT_SCC "Unverified opendbc signal";
CM_ SG_ 354 FAULT_LFA "Unverified opendbc signal";
CM_ SG_ 354 FAULT_HDA "Unverified opendbc signal";
CM_ SG_ 354 FAULT_LCA "Unverified opendbc signal";
CM_ SG_ 354 FAULT_HDP "Unverified opendbc signal";
CM_ SG_ 354 FAULT_DAS "Unverified opendbc signal";
CM_ SG_ 354 FAULT_ESS "Unverified opendbc signal";
CM_ SG_ 354 ZEROS_11 "Unverified opendbc signal";
CM_ BO_ 438 "Unverified: Imported from opendbc. Validation required.";
CM_ SG_ 438 CHECKSUM "Unverified opendbc signal";
CM_ SG_ 438 COUNTER "Unverified opendbc signal";
CM_ BO_ 439 "Unverified: Imported from opendbc. Validation required.";
CM_ SG_ 439 CHECKSUM "Unverified opendbc signal";
CM_ SG_ 439 COUNTER "Unverified opendbc signal";
CM_ BO_ 440 "Unverified: Imported from opendbc. Validation required.";
CM_ SG_ 440 CHECKSUM "Unverified opendbc signal";
CM_ SG_ 440 COUNTER "Unverified opendbc signal";
CM_ BO_ 441 "Unverified: Imported from opendbc. Validation required.";
CM_ SG_ 441 CHECKSUM "Unverified opendbc signal";
CM_ SG_ 441 COUNTER "Unverified opendbc signal";
CM_ BO_ 507 "Unverified: Imported from opendbc. Validation required.";
CM_ SG_ 507 CHECKSUM "Unverified opendbc signal";
CM_ SG_ 507 COUNTER "Unverified opendbc signal";
CM_ BO_ 599 "Unverified: Imported from opendbc. Validation required.";
CM_ SG_ 599 RR_SHVU_SeatOptSta "Unverified opendbc signal";
CM_ SG_ 599 C_RH_Folding_SW "Unverified opendbc signal";
CM_ SG_ 599 RR_SHVU_SeatHtOperSta "Unverified opendbc signal";
CM_ SG_ 599 C_LH_Unfolding_SW "Unverified opendbc signal";
CM_ SG_ 599 C_LH_Folding_SW "Unverified opendbc signal";
CM_ SG_ 599 RRPSM_RearModeWngDis "Unverified opendbc signal";
CM_ SG_ 599 RRIMS_AMPBzrReq "Unverified opendbc signal";
CM_ BO_ 689 "Unverified: Imported from opendbc. Validation required.";
CM_ SG_ 689 ADAS_CMD_Crc34Val "Unverified opendbc signal";
CM_ SG_ 689 ADAS_CMD_AlvCnt34Val "Unverified opendbc signal";
CM_ SG_ 689 HDP_RDD_WarnSta "Unverified opendbc signal";
CM_ SG_ 689 HDP_RDD_LongAsstCtrlSta "Unverified opendbc signal";
CM_ SG_ 689 HDP_RDD_HzrdLmpReqSta "Unverified opendbc signal";
CM_ SG_ 689 HDP_RDD_ACIActvDispSta "Unverified opendbc signal";
CM_ SG_ 689 HDP_RDD_EMStbltActvReqSta "Unverified opendbc signal";
CM_ BO_ 827 "Unverified: Imported from opendbc. Validation required.";
CM_ SG_ 827 TP_HU_IAU_Byte0 "Unverified opendbc signal";
CM_ SG_ 827 TP_HU_IAU_Byte1 "Unverified opendbc signal";
CM_ SG_ 827 TP_HU_IAU_Byte2 "Unverified opendbc signal";
CM_ SG_ 827 TP_HU_IAU_Byte3 "Unverified opendbc signal";
CM_ SG_ 827 TP_HU_IAU_Byte4 "Unverified opendbc signal";
CM_ SG_ 827 TP_HU_IAU_Byte5 "Unverified opendbc signal";
CM_ SG_ 827 TP_HU_IAU_Byte6 "Unverified opendbc signal";
CM_ SG_ 827 TP_HU_IAU_Byte7 "Unverified opendbc signal";
CM_ BO_ 828 "Unverified: Imported from opendbc. Validation required.";
CM_ SG_ 828 TP_IAU_HU_Byte0 "Unverified opendbc signal";
CM_ SG_ 828 TP_IAU_HU_Byte1 "Unverified opendbc signal";
CM_ SG_ 828 TP_IAU_HU_Byte2 "Unverified opendbc signal";
CM_ SG_ 828 TP_IAU_HU_Byte3 "Unverified opendbc signal";
CM_ SG_ 828 TP_IAU_HU_Byte4 "Unverified opendbc signal";
CM_ SG_ 828 TP_IAU_HU_Byte5 "Unverified opendbc signal";
CM_ SG_ 828 TP_IAU_HU_Byte6 "Unverified opendbc signal";
CM_ SG_ 828 TP_IAU_HU_Byte7 "Unverified opendbc signal";
CM_ BO_ 895 "Unverified: Imported from opendbc. Validation required.";
CM_ SG_ 895 GATEWAY_HS_D_STS "Unverified opendbc signal";
CM_ BO_ 898 "Unverified: Imported from opendbc. Validation required.";
CM_ SG_ 898 DATC_Crc5Val "Unverified opendbc signal";
CM_ SG_ 898 DATC_AlvCnt5Val "Unverified opendbc signal";
CM_ SG_ 898 DATC_FrDrvModDis "Unverified opendbc signal";
CM_ SG_ 898 DATC_FrPassModDis "Unverified opendbc signal";
CM_ SG_ 898 DATC_ClmtTxtPopupOSD "Unverified opendbc signal";
CM_ SG_ 898 DATC_DrvAutoDis "Unverified opendbc signal";
CM_ SG_ 898 DATC_FrClmtScrnDis "Unverified opendbc signal";
CM_ SG_ 898 DATC_AcDis "Verified on an EV6 against CAN logs: A/C on (1) or off (0), follows the A/C button.";
CM_ SG_ 898 DATC_IntakeSta "Unverified opendbc signal";
CM_ BO_ 899 "Unverified: Imported from opendbc. Validation required.";
CM_ SG_ 899 DATC_Crc6Val "Unverified opendbc signal";
CM_ SG_ 899 DATC_AlvCnt6Val "Unverified opendbc signal";
CM_ SG_ 899 DATC_SyncDis "Unverified opendbc signal";
CM_ SG_ 899 DATC_OpSta "Verified on an EV6 against CAN logs and with timed notes: climate control on or off; Not_Available until the car starts. Not yet checked during remote climate.";
CM_ SG_ 899 DATC_FrDfgSta "Verified on an EV6 against CAN logs: windshield defog on or off.";
CM_ SG_ 899 DATC_SmrtVntDis "Unverified opendbc signal";
CM_ SG_ 899 DATC_AutoDfgBlnkDis "Unverified opendbc signal";
CM_ SG_ 899 DATC_AutoDfgSysOffDis "Unverified opendbc signal";
CM_ SG_ 899 DATC_ArClnIND "Unverified opendbc signal";
CM_ SG_ 899 DATC_RrDfgInd "Stays 0 when the rear defroster is switched on.";
CM_ BO_ 900 "Unverified: Imported from opendbc. Validation required.";
CM_ SG_ 900 DATC_Crc7Val "Unverified opendbc signal";
CM_ SG_ 900 DATC_AlvCnt7Val "Unverified opendbc signal";
CM_ SG_ 900 DATC_FrDrvBlwDis "Unverified opendbc signal";
CM_ SG_ 900 DATC_FrPsBlwDis "Unverified opendbc signal";
CM_ SG_ 900 DATC_HeatDis "Verified on an EV6 against CAN logs: 1 while Heat is on.";
CM_ SG_ 900 DATC_DrvOnlyDis "Unverified opendbc signal";
CM_ SG_ 900 DATC_AUTOStep "Unverified opendbc signal";
CM_ SG_ 900 DATC_IntakeDis "Unverified opendbc signal";
CM_ BO_ 902 "Unverified: Imported from opendbc. Validation required.";
CM_ SG_ 902 PSM_DrvStSldFwdDis "Unverified opendbc signal";
CM_ SG_ 902 PSM_DrvStSldBckwdDis "Unverified opendbc signal";
CM_ SG_ 902 PSM_DrvStReclneFwdDis "Unverified opendbc signal";
CM_ SG_ 902 PSM_DrvStReclneBckwdDis "Unverified opendbc signal";
CM_ SG_ 902 PSM_IMSOptTyp "Unverified opendbc signal";
CM_ SG_ 902 PSM_DrvStTiltDnDis "Unverified opendbc signal";
CM_ SG_ 902 PSM_DrvStHghtUpDis "Unverified opendbc signal";
CM_ SG_ 902 PSM_DrvStHghtDnDis "Unverified opendbc signal";
CM_ SG_ 902 PSM_DrvStCushExtBckwdDis "Unverified opendbc signal";
CM_ SG_ 902 PSM_DrvStCushExtFwdDis "Unverified opendbc signal";
CM_ SG_ 902 PSM_DrvStHdRstUpDis "Unverified opendbc signal";
CM_ SG_ 902 PSM_DrvStHdRstDnDis "Unverified opendbc signal";
CM_ SG_ 902 SmrtIMS_StatureRspVal "Unverified opendbc signal";
CM_ SG_ 902 PSM_DrvStHdRstBckwdDis "Unverified opendbc signal";
CM_ SG_ 902 SmrtIMS_SeatedHghtRspVal "Unverified opendbc signal";
CM_ SG_ 902 SmrtIMS_WghtRspVal "Unverified opendbc signal";
CM_ SG_ 902 PSM_DrvStLmbrLoDis "Unverified opendbc signal";
CM_ SG_ 902 SmartIMS_DisReq "Unverified opendbc signal";
CM_ SG_ 902 PSM_DrvStLmbrUpDis "Unverified opendbc signal";
CM_ SG_ 902 SmrtIMS_ExitSta "Unverified opendbc signal";
CM_ SG_ 902 PSM_DrvStBlstrInfDis "Unverified opendbc signal";
CM_ SG_ 902 PSM_DrvStRlxTiltUpDis "Unverified opendbc signal";
CM_ SG_ 902 PSM_DrvStRlxTiltDnDis "Unverified opendbc signal";
CM_ SG_ 902 PSM_DrvStLegUpDis "Unverified opendbc signal";
CM_ SG_ 902 PSM_DrvStLegDnDis "Unverified opendbc signal";
CM_ BO_ 903 "Unverified: Imported from opendbc. Validation required.";
CM_ SG_ 903 PSM_LmbrSigSrcTyp "Unverified opendbc signal";
CM_ BO_ 904 "Unverified: Imported from opendbc. Validation required.";
CM_ SG_ 904 PSM_DrvReclinePosition "Unverified opendbc signal";
CM_ SG_ 904 PSM_EsyAcsGetOnSta "Unverified opendbc signal";
CM_ SG_ 904 PSM_EsyAcsGetOffSta "Unverified opendbc signal";
CM_ SG_ 904 PSM_EsyAcsStpSta "Unverified opendbc signal";
CM_ SG_ 904 RRPSS_L_StSldFwdMvBtn "Unverified opendbc signal";
CM_ SG_ 904 RRPSS_L_StSldBwdMvBtn "Unverified opendbc signal";
CM_ SG_ 904 RRPSS_L_StRclFwdMvBtn "Unverified opendbc signal";
CM_ SG_ 904 RRPSS_L_StRclBwdMvBtn "Unverified opendbc signal";
CM_ SG_ 904 PSM_SWVerMinor1 "Unverified opendbc signal";
CM_ SG_ 904 RRPSS_L_StTltUpMvBtn "Unverified opendbc signal";
CM_ SG_ 904 RRPSS_L_StTltDnMvBtn "Unverified opendbc signal";
CM_ SG_ 904 RRPSS_L_StHRestUpMvBtn "Unverified opendbc signal";
CM_ SG_ 904 RRPSS_L_StHRestDnMvBtn "Unverified opendbc signal";
CM_ SG_ 904 RRPSS_L_StHRestFwdMvBtn "Unverified opendbc signal";
CM_ SG_ 904 RRPSS_L_StHRestBwdMvBtn "Unverified opendbc signal";
CM_ SG_ 904 RRPSS_L_StLegRestUpBtn "Unverified opendbc signal";
CM_ SG_ 904 RRPSS_L_StLegRestDnBtn "Unverified opendbc signal";
CM_ SG_ 904 PSM_DrvHeightPosition "Unverified opendbc signal";
CM_ SG_ 904 PSM_DrvSlidePosition "Unverified opendbc signal";
CM_ BO_ 916 "Unverified: Imported from opendbc. Validation required.";
CM_ SG_ 916 BCM_Crc19Val "Unverified opendbc signal";
CM_ SG_ 916 USM_1stRrStRmndSta "Unverified opendbc signal";
CM_ SG_ 916 BCM_AlvCnt19Val "Unverified opendbc signal";
CM_ SG_ 916 USM_IBU_AutoDrUnLkReq "Unverified opendbc signal";
CM_ SG_ 916 USM_IBU_TwoTrnUnLkCurrentSta "Unverified opendbc signal";
CM_ SG_ 916 USM_IBU_RemoteWDWCurrentSta "Unverified opendbc signal";
CM_ SG_ 916 USM_IBU_AutoDrLkReq2 "Unverified opendbc signal";
CM_ BO_ 942 "Unverified: Imported from opendbc. Validation required.";
CM_ SG_ 942 AMP_Beep1VolumeStep_DATC "Unverified opendbc signal";
CM_ SG_ 942 AMP_SPDIF_OutputCh_Select "Unverified opendbc signal";
CM_ SG_ 942 AMP_Analog_OutputCh_Select "Unverified opendbc signal";
CM_ SG_ 942 AMP_Beep1_OutputCh_Select "Unverified opendbc signal";
CM_ SG_ 942 AMP_Beep1KBDVolumeStep "Unverified opendbc signal";
CM_ BO_ 945 "Unverified: Imported from opendbc. Validation required.";
CM_ SG_ 945 DATC_Crc9Val "Unverified opendbc signal";
CM_ SG_ 945 DATC_AlvCnt9Val "Unverified opendbc signal";
CM_ SG_ 945 DATC_RrBlwDis "Unverified opendbc signal";
CM_ SG_ 945 DATC_ArClnSysOSD "Unverified opendbc signal";
CM_ SG_ 945 DATC_ArClnStepClr "Unverified opendbc signal";
CM_ SG_ 945 DATC_ArClnSmblTyp "Unverified opendbc signal";
CM_ SG_ 945 DATC_AfterBlowUSMSta "Unverified opendbc signal";
CM_ SG_ 945 DATC_SchdldVntUSMSta "Unverified opendbc signal";
CM_ SG_ 945 DATC_SchdldVntHrSta "Unverified opendbc signal";
CM_ SG_ 945 DATC_SchdldVntMinSta "Unverified opendbc signal";
CM_ BO_ 946 "Unverified: Imported from opendbc. Validation required.";
CM_ SG_ 946 DATC_Crc10Val "Unverified opendbc signal";
CM_ SG_ 946 DATC_AlvCnt10Val "Unverified opendbc signal";
CM_ SG_ 946 DATC_Typ "Unverified opendbc signal";
CM_ SG_ 946 DATC_Opt1Typ "Unverified opendbc signal";
CM_ SG_ 946 DATC_Opt3Typ "Unverified opendbc signal";
CM_ SG_ 946 DATC_Opt2Typ "Unverified opendbc signal";
CM_ SG_ 946 DATC_Opt4Typ "Unverified opendbc signal";
CM_ SG_ 946 DATC_StrWhlUSMSta "Unverified opendbc signal";
CM_ SG_ 946 DATC_StrWhlHtngReq "Unverified opendbc signal";
CM_ BO_ 963 "Unverified: Imported from opendbc. Validation required.";
CM_ SG_ 963 BCM_Crc16Val "Unverified opendbc signal";
CM_ SG_ 963 BCM_AlvCnt16Val "Unverified opendbc signal";
CM_ SG_ 963 IBU_SWVerMajor1 "Unverified opendbc signal";
CM_ SG_ 963 IBU_SWVerMinor1 "Unverified opendbc signal";
CM_ SG_ 963 IBU_SWVerMinor2 "Unverified opendbc signal";
CM_ SG_ 963 ECW_Fault "Unverified opendbc signal";
CM_ SG_ 963 ECW_FaultActv "Unverified opendbc signal";
CM_ SG_ 963 ECW_HiVolt "Unverified opendbc signal";
CM_ SG_ 963 ECW_HiVoltActv "Unverified opendbc signal";
CM_ SG_ 963 ECW_LoVolt "Unverified opendbc signal";
CM_ SG_ 963 ECW_LoVoltActv "Unverified opendbc signal";
CM_ SG_ 963 ECW_Overload "Unverified opendbc signal";
CM_ SG_ 963 ECW_OverloadActv "Unverified opendbc signal";
CM_ SG_ 963 ECW_CommErr "Unverified opendbc signal";
CM_ SG_ 963 SunRoof_RearBlindOprSta "Unverified opendbc signal";
CM_ BO_ 992 "Unverified: Imported from opendbc. Validation required.";
CM_ SG_ 992 BCM_Crc2Val "Unverified opendbc signal";
CM_ SG_ 992 BCM_AlvCnt2Val "Unverified opendbc signal";
CM_ SG_ 992 BAlarm_BglrAlrmCurrentSta "Verified on an EV6 against CAN logs: anti-theft alarm state, 4 when armed by locking with the key fob, 7 right after unlocking with it, back to 1 a few seconds later. Locking from inside does not arm it (log_08). A triggered alarm was never captured.";
CM_ SG_ 992 BAlarm_BglrAlrmSta "Verified on an EV6 against CAN logs: 1 while the alarm is armed (locked with the key fob), 0 otherwise (log_08).";
CM_ SG_ 992 BAlarm_PncAlrmSta "Unverified opendbc signal";
CM_ SG_ 992 BAlarm_BrglrHrnRlySta "Unverified opendbc signal";
CM_ SG_ 992 BCM_KeyInSta "Unverified opendbc signal";
CM_ SG_ 992 BCM_AccInSta "Verified on an EV6 against CAN logs: 1 in accessory, on and ready; 0 with the car off.";
CM_ SG_ 992 BCM_Ign1InSta "Verified on an EV6 against CAN logs: 1 when on and ready; 0 when off or in accessory.";
CM_ SG_ 992 BCM_Ign2InSta "Verified on an EV6 against CAN logs: follows BCM_Ign1InSta, about a second later when starting to ready.";
CM_ BO_ 997 "Unverified: Imported from opendbc. Validation required.";
CM_ SG_ 997 BCM_Crc5Val "Unverified opendbc signal";
CM_ SG_ 997 BCM_AlvCnt5Val "Unverified opendbc signal";
CM_ SG_ 997 PDW_OptTyp "Unverified opendbc signal";
CM_ SG_ 997 PDW_SysChkSndSta "Unverified opendbc signal";
CM_ SG_ 997 PDW_SwIndOnReq "Unverified opendbc signal";
CM_ SG_ 997 PDW_FrCtWrngLvlDis "Unverified opendbc signal";
CM_ SG_ 997 PDW_SysFlrSta "Unverified opendbc signal";
CM_ SG_ 997 PDW_FrCtWrngSndSta "Unverified opendbc signal";
CM_ SG_ 997 PDW_FrLtWrngLvlDis "Unverified opendbc signal";
CM_ SG_ 997 PDW_FrRtWrngLvlDis "Unverified opendbc signal";
CM_ SG_ 997 PDW_FrSnsrWrngLvlSta "Unverified opendbc signal";
CM_ BO_ 998 "Unverified: Imported from opendbc. Validation required.";
CM_ SG_ 998 BCM_Crc6Val "Unverified opendbc signal";
CM_ SG_ 998 BCM_AlvCnt6Val "Unverified opendbc signal";
CM_ SG_ 998 PDW_RrCtWrngLvlDis "Unverified opendbc signal";
CM_ SG_ 998 PDW_RrLtWrngLvlDis "Unverified opendbc signal";
CM_ SG_ 998 PDW_RrRtWrngLvlDis "Unverified opendbc signal";
CM_ BO_ 1029 "Unverified: Imported from opendbc. Validation required.";
CM_ SG_ 1029 ICU_Crc12Val "Unverified opendbc signal";
CM_ SG_ 1029 ICU_AlvCnt12Val "Unverified opendbc signal";
CM_ SG_ 1029 DoorLock_CtrlDrLkSwSta_ICU "Unverified opendbc signal";
CM_ SG_ 1029 DoorLock_CtrlDrUnLkSwSta_ICU "Unverified opendbc signal";
CM_ SG_ 1029 ICU_IGN3On_ReqState_New "Unverified opendbc signal";
CM_ SG_ 1029 ICU_BattMngAlert "Unverified opendbc signal";
CM_ BO_ 1040 "Unverified: Imported from opendbc. Validation required.";
CM_ SG_ 1040 ICU_Crc10Val "Unverified opendbc signal";
CM_ SG_ 1040 ICU_AlvCnt10Val "Unverified opendbc signal";
CM_ SG_ 1040 ICU_BS2SoC "Unverified opendbc signal";
CM_ SG_ 1040 ICU_BS2NCap "Unverified opendbc signal";
CM_ SG_ 1040 ICU_BS2OpnCirVol "Unverified opendbc signal";
CM_ SG_ 1040 ICU_BS2_FSOC "Unverified opendbc signal";
CM_ SG_ 1040 ICU_BS2_FSOH "Unverified opendbc signal";
CM_ SG_ 1040 ICU_BS2_FSOF "Unverified opendbc signal";
CM_ SG_ 1040 ICU_BS2_FQSTAT "Unverified opendbc signal";
CM_ SG_ 1040 ICU_BS2SoH "Unverified opendbc signal";
CM_ SG_ 1040 ICU_BS2SoF "Unverified opendbc signal";
CM_ BO_ 1043 "Unverified: Imported from opendbc. Validation required.";
CM_ SG_ 1043 LEFT_STALK "Verified on an EV6 against CAN logs: 1 for the whole left indicator sequence, also with the hazards on.";
CM_ SG_ 1043 RIGHT_STALK "Verified on an EV6 against CAN logs: 1 for the whole right indicator sequence, also with the hazards on.";
CM_ SG_ 1043 COUNTER_ALT "Unverified opendbc signal";
CM_ SG_ 1043 LEFT_LAMP "Verified on an EV6 against CAN logs: follows the left indicator lamp as it flashes.";
CM_ SG_ 1043 RIGHT_LAMP "Verified on an EV6 against CAN logs: follows the right indicator lamp as it flashes.";
CM_ SG_ 1043 LEFT_LAMP_ALT "Unverified opendbc signal";
CM_ SG_ 1043 RIGHT_LAMP_ALT "Unverified opendbc signal";
CM_ SG_ 1043 USE_ALT_LAMP "Unverified opendbc signal";
CM_ BO_ 1046 "Unverified: Imported from opendbc. Validation required.";
CM_ SG_ 1046 ICU_Crc6Val "Unverified opendbc signal";
CM_ SG_ 1046 ICU_AlvCnt6Val "Unverified opendbc signal";
CM_ SG_ 1046 Lamp_RrTrnSigLmpLftOpnSta "Unverified opendbc signal";
CM_ SG_ 1046 Lamp_RrTrnSigLmpRtOpnSta "Unverified opendbc signal";
CM_ SG_ 1046 Lamp_FrTrnSigLmpLftOpnSta "Unverified opendbc signal";
CM_ SG_ 1046 Lamp_FrTrnSigLmpRtOpnSta "Unverified opendbc signal";
CM_ BO_ 1047 "Unverified: Imported from opendbc. Validation required.";
CM_ SG_ 1047 ICU_Crc7Val "Unverified opendbc signal";
CM_ SG_ 1047 ICU_AlvCnt7Val "Unverified opendbc signal";
CM_ BO_ 1048 "Unverified: Imported from opendbc. Validation required.";
CM_ SG_ 1048 ICU_Crc8Val "Unverified opendbc signal";
CM_ SG_ 1048 HSWS_SysWrngSta_ICU "Verified on an EV6 against CAN logs: heated steering wheel, 4 while on, 0 while off. Despite the name, not a warning.";
CM_ SG_ 1048 ICU_AlvCnt8Val "Unverified opendbc signal";
CM_ SG_ 1048 DriveTypeOption "Unverified opendbc signal";
CM_ SG_ 1048 Warn_RrLftSBRMATSwSta "Unverified opendbc signal";
CM_ SG_ 1048 Warn_RrRhtSBRMATSwSta "Unverified opendbc signal";
CM_ SG_ 1048 Lamp_FootLampOnReq "Unverified opendbc signal";
CM_ SG_ 1048 Lamp_MoodLampOnReq "Unverified opendbc signal";
CM_ SG_ 1048 ICU_PowerAutoCutModSta "Unverified opendbc signal";
CM_ SG_ 1048 ICU_SoCBattStaMsgReq "Unverified opendbc signal";
CM_ SG_ 1048 Brake_SwSta_ICU "Verified on an EV6 against CAN logs: brake pedal switch, 1 while the pedal is pressed. On/off only; stays 0 during regen braking, unlike REAR_LAMP_STATUS Brake_Lamp.";
CM_ BO_ 1050 "Unverified: Imported from opendbc. Validation required.";
CM_ SG_ 1050 BCM_Crc7Val "Unverified opendbc signal";
CM_ SG_ 1050 BCM_AlvCnt7Val "Unverified opendbc signal";
CM_ SG_ 1050 Lamp_HiPrioHzrdReq "Does not change when the hazards are switched on; use BLINKERS HAZARD_ON.";
CM_ SG_ 1050 Lamp_LoPrioHzrdReq "Does not change when the hazards are switched on; the 17-bit length is likely wrong.";
CM_ SG_ 1050 Lamp_IntTailLmpOnReq "Verified on an EV6 against CAN logs: 1 with the position lights or low beams on.";
CM_ SG_ 1050 Lamp_ExtrnlTailLmpOnReq "Verified on an EV6 against CAN logs: 1 with the position lights or low beams on.";
CM_ SG_ 1050 Lamp_HdLmpLoOnReq "Verified on an EV6 against CAN logs and live: 1 with the low beams on, also during a high beam flash.";
CM_ SG_ 1050 Lamp_HdLmpHiOnReq "Verified on an EV6 against CAN logs: 1 during a high beam flash.";
CM_ SG_ 1050 Lamp_AvTailLmpSta "Unverified opendbc signal";
CM_ BO_ 1051 "Unverified: Imported from opendbc. Validation required.";
CM_ SG_ 1051 BCM_Crc8Val "Unverified opendbc signal";
CM_ SG_ 1051 BCM_AlvCnt8Val "Unverified opendbc signal";
CM_ SG_ 1051 Lamp_HbaCtrlModTyp "Verified on an EV6 against CAN logs: 1 with auto high beam enabled, 0 when disabled. 0x11B byte 3 bit 5 follows it.";
CM_ SG_ 1051 Lamp_IFSCtrlModTyp "Unverified opendbc signal";
CM_ SG_ 1051 Lamp_RrFogLmpOnReq "Unverified opendbc signal";
CM_ SG_ 1051 Lamp_HdLmpWlcmCmd "Unverified opendbc signal";
CM_ SG_ 1051 Lamp_PuddleLmpOnReq "Unverified opendbc signal";
CM_ BO_ 1052 "Unverified: Imported from opendbc. Validation required.";
CM_ SG_ 1052 BCM_Crc9Val "Unverified opendbc signal";
CM_ SG_ 1052 BCM_AlvCnt9Val "Unverified opendbc signal";
CM_ SG_ 1052 Lamp_AutoLtSnsrNightSta "Unverified opendbc signal";
CM_ SG_ 1052 Lamp_VendorInfo "Unverified opendbc signal";
CM_ SG_ 1052 Lamp_AutoLtSnsrHorVal "Unverified opendbc signal";
CM_ SG_ 1052 IBU_HDPSpprtSWVer "Unverified opendbc signal";
CM_ SG_ 1052 IBU_HDPSpprtRdy "Unverified opendbc signal";
CM_ SG_ 1052 Wiper_RainAmount "Unverified opendbc signal";
CM_ BO_ 1055 "Unverified: Imported from opendbc. Validation required.";
CM_ SG_ 1055 HU_SVM_tch_mpt_valid__ccp_pan "Unverified opendbc signal";
CM_ SG_ 1055 HU_SVM_ccp_pan_valid "Unverified opendbc signal";
CM_ SG_ 1055 SVM_CaptureModeCMD "Unverified opendbc signal";
CM_ SG_ 1055 HU_SVM_ccp_pan "Unverified opendbc signal";
CM_ BO_ 1058 "Unverified: Imported from opendbc. Validation required.";
CM_ SG_ 1058 BCM_Crc10Val "Unverified opendbc signal";
CM_ SG_ 1058 Wiper_RainSnsrPartNum "Unverified opendbc signal";
CM_ SG_ 1058 BCM_AlvCnt10Val "Unverified opendbc signal";
CM_ SG_ 1058 Wiper_PrkngPosSta "Verified on an EV6 against CAN logs: 1 with the wipers parked, 0 during each sweep (single wipes, low and high, washer wipes). The stalk position and the rain sensor sensitivity were not found on this bus.";
CM_ SG_ 1058 Wiper_RainSnsrOptionTyp "Unverified opendbc signal";
CM_ SG_ 1058 Wiper_RainSnsrWipeReq "Verified on an EV6 against CAN logs: pulses for about 0.1 s when the rain sensor asks for a wipe, i.e. on switching to Auto and on each sensitivity increase (not decrease). Replaces the opendbc 28-bit Wiper_RainSnsrSta, which spanned unrelated bits.";
CM_ SG_ 1058 Rear_Camera_Button "Verified on an EV6 against CAN logs: pulses for 0.2 s at each rear camera button press (in Park), whether it turns the camera on or off; not the camera state.";
CM_ SG_ 1058 BCM_GearPosPSta "Verified on an EV6 against CAN logs: 1 in Park, 0 in any other gear. Use DRIVE_MODE_STATUS Gear for the gear itself.";
CM_ SG_ 1058 BCM_SunRoofOpnSta "Unverified opendbc signal";
CM_ SG_ 1058 SunRoof_RrBlindErrSta "Unverified opendbc signal";
CM_ BO_ 1063 "Unverified: Imported from opendbc. Validation required.";
CM_ SG_ 1063 DATC_Crc11Val "Unverified opendbc signal";
CM_ SG_ 1063 DATC_AlvCnt11Val "Unverified opendbc signal";
CM_ SG_ 1063 DATC_TunnelFuncOff4AutoDfgReq "Unverified opendbc signal";
CM_ SG_ 1063 DATC_RrCtlLckSta "Unverified opendbc signal";
CM_ SG_ 1063 DATC_DrvrStHtrUSMSta "Unverified opendbc signal";
CM_ SG_ 1063 DATC_WshFldUSMSta "Unverified opendbc signal";
CM_ SG_ 1063 DATC_DfgLgcUSMSta "Unverified opendbc signal";
CM_ SG_ 1063 DATC_AutoFrshUSMSta "Unverified opendbc signal";
CM_ SG_ 1063 DATC_HptIntnstySta "Unverified opendbc signal";
CM_ BO_ 1066 "Unverified: Imported from opendbc. Validation required.";
CM_ SG_ 1066 DATC_Crc13Val "Unverified opendbc signal";
CM_ SG_ 1066 DATC_AlvCnt13Val "Unverified opendbc signal";
CM_ SG_ 1066 DATC_MltAutoBlrTxt "Unverified opendbc signal";
CM_ SG_ 1066 DATC_MltAutoBlrTxt_Ps "Unverified opendbc signal";
CM_ SG_ 1066 DATC_MltAutoBlrTxt_Rr "Unverified opendbc signal";
CM_ SG_ 1066 DATC_RLStTmblrSwReq "Unverified opendbc signal";
CM_ SG_ 1066 DATC_RRStTmblrSwReq "Unverified opendbc signal";
CM_ SG_ 1066 DATC_Opt5Typ "Unverified opendbc signal";
CM_ BO_ 1074 "Unverified: Imported from opendbc. Validation required.";
CM_ SG_ 1074 BCM_Crc11Val "Unverified opendbc signal";
CM_ SG_ 1074 USM_UipSta "Unverified opendbc signal";
CM_ SG_ 1074 BCM_AlvCnt11Val "Unverified opendbc signal";
CM_ SG_ 1074 USM_EscrtHdLmpSta "Unverified opendbc signal";
CM_ SG_ 1074 USM_BtnIllumiAlwaysOnSta "Unverified opendbc signal";
CM_ SG_ 1074 USM_WlcmMirLtSystTitleOpt "Unverified opendbc signal";
CM_ SG_ 1074 USM_UnlockWlcmSta "Unverified opendbc signal";
CM_ SG_ 1074 USM_SmrtWlcmSta "Unverified opendbc signal";
CM_ SG_ 1074 USM_RrStRmndSta "Unverified opendbc signal";
CM_ SG_ 1074 USM_PDWAutoOnSta "Unverified opendbc signal";
CM_ BO_ 1090 "Unverified: Imported from opendbc. Validation required.";
CM_ SG_ 1090 BCM_Crc12Val "Unverified opendbc signal";
CM_ SG_ 1090 BCM_AlvCnt12Val "Unverified opendbc signal";
CM_ SG_ 1090 BCM_SmkOptTyp "Unverified opendbc signal";
CM_ SG_ 1090 BCM_SunRoofOptTyp "Unverified opendbc signal";
CM_ SG_ 1090 Window_DrvrSdWdwSta_BCM "Wrong on an EV6: stays 0 while the windows move, in CAN logs and live. Use BCM_15_200ms.";
CM_ SG_ 1090 Window_AsstSdWdwSta_BCM "Wrong on an EV6: stays 0 while the windows move, in CAN logs and live. Use BCM_15_200ms.";
CM_ SG_ 1090 Window_RrLftWdwSta_BCM "Wrong on an EV6: stays 0 while the windows move, in CAN logs and live. Use BCM_15_200ms.";
CM_ SG_ 1090 Window_RrRtWdwSta_BCM "Wrong on an EV6: stays 0 while the windows move, in CAN logs and live. Use BCM_15_200ms.";
CM_ SG_ 1090 SunRoof_GlassPosSta "Unverified opendbc signal";
CM_ SG_ 1090 SunRoof_BlindPosSta "Unverified opendbc signal";
CM_ SG_ 1090 SunRoof_GlassErrSta "Unverified opendbc signal";
CM_ SG_ 1090 SunRoof_BlindErrSta "Unverified opendbc signal";
CM_ BO_ 1092 "Unverified: Imported from opendbc. Validation required.";
CM_ SG_ 1092 SMK_Crc2Val "Unverified opendbc signal";
CM_ SG_ 1092 SMK_AlvCnt2Val "Unverified opendbc signal";
CM_ SG_ 1092 SSB_StrtStpBtnSw1Sta "Unverified opendbc signal";
CM_ SG_ 1092 SSB_StrtStpBtnSw2Sta "Unverified opendbc signal";
CM_ SG_ 1092 ENG_PwrAutoOffInfo "Unverified opendbc signal";
CM_ SG_ 1092 SMK_AuthSta "Unverified opendbc signal";
CM_ SG_ 1092 SMK_Ign1InSta "Unverified opendbc signal";
CM_ SG_ 1092 SMK_Ign1RlySta "Unverified opendbc signal";
CM_ SG_ 1092 SMK_Ign2InSta "Unverified opendbc signal";
CM_ SG_ 1092 SMK_Ign2RlySta "Unverified opendbc signal";
CM_ SG_ 1092 SMK_StrtFdbckSta "Unverified opendbc signal";
CM_ SG_ 1092 SMK_StrtrRlyOutSta "Unverified opendbc signal";
CM_ SG_ 1092 SMK_AccInSta "Unverified opendbc signal";
CM_ SG_ 1092 SMK_AccRlySta "Unverified opendbc signal";
CM_ SG_ 1092 SMK_CLUAccIndOnReq "Unverified opendbc signal";
CM_ SG_ 1092 SMK_TlEngRunSta "Unverified opendbc signal";
CM_ SG_ 1092 SMK_TlCrnkModSta "Unverified opendbc signal";
CM_ SG_ 1092 SMK_RmtKeyEngRunSta "Unverified opendbc signal";
CM_ SG_ 1092 SMK_RmtKeyCrnkModSta "Unverified opendbc signal";
CM_ BO_ 1093 "Unverified: Imported from opendbc. Validation required.";
CM_ SG_ 1093 SMK_Crc6Val "Unverified opendbc signal";
CM_ SG_ 1093 SMK_AlvCnt6Val "Unverified opendbc signal";
CM_ SG_ 1093 Lamp_HzrdBlnkngSta "Unverified opendbc signal";
CM_ SG_ 1093 RSPA_LearntSta "Unverified opendbc signal";
CM_ SG_ 1093 Lamp_SmrtWlcmLtOnReq "Unverified opendbc signal";
CM_ SG_ 1093 Fob_BattStaInfo "Unverified opendbc signal";
CM_ SG_ 1093 Fob_FoundDrvWlcmArea "Unverified opendbc signal";
CM_ SG_ 1093 Fob_FoundAsstWlcmArea "Unverified opendbc signal";
CM_ SG_ 1093 Fob_FoundExtrnlArea "Unverified opendbc signal";
CM_ SG_ 1093 Fob_FoundIntArea "Unverified opendbc signal";
CM_ SG_ 1093 Fob_LearntSta "Unverified opendbc signal";
CM_ SG_ 1093 RSPA_RFSigErrSta "Unverified opendbc signal";
CM_ SG_ 1093 RSPA_CanErrSta "Unverified opendbc signal";
CM_ SG_ 1093 LFAnt_FltSta "Unverified opendbc signal";
CM_ SG_ 1093 LFAnt_SrchSta "Unverified opendbc signal";
CM_ SG_ 1093 RSPA_ModSta_SMK "Unverified opendbc signal";
CM_ SG_ 1093 RSPA_FobBattSta "Unverified opendbc signal";
CM_ SG_ 1093 Fob_BtnReleasedSta "Unverified opendbc signal";
CM_ SG_ 1093 USM_SmrtTrnkTlgtModSta "Unverified opendbc signal";
CM_ SG_ 1093 USM_WALModSta "Unverified opendbc signal";
CM_ SG_ 1093 Fob_FoundWlcmArea "Unverified opendbc signal";
CM_ BO_ 1099 "Unverified: Imported from opendbc. Validation required.";
CM_ SG_ 1099 USM_CmdWPCSta "Unverified opendbc signal";
CM_ SG_ 1099 WPC_PhnLftWrngSta "Unverified opendbc signal";
CM_ SG_ 1099 WPC_SWVerMajor1 "Unverified opendbc signal";
CM_ SG_ 1099 WPC_SWVerMinor1 "Unverified opendbc signal";
CM_ SG_ 1099 WPC_SWVerMinor2 "Unverified opendbc signal";
CM_ BO_ 1124 "Unverified: Imported from opendbc. Validation required.";
CM_ SG_ 1124 BCM_Crc15Val "Unverified opendbc signal";
CM_ SG_ 1124 BCM_AlvCnt15Val "Unverified opendbc signal";
CM_ SG_ 1124 Window_DrvrSdWdwActSta "Verified on an EV6 against CAN logs: driver window motor action.";
CM_ SG_ 1124 Window_AsstSdWdwActSta "Verified on an EV6 against CAN logs: passenger window motor action.";
CM_ SG_ 1124 Window_RrLftWdwActSta "Always Not_Available on an EV6 while the rear windows move; the rear window state is not on this bus.";
CM_ SG_ 1124 Window_RrRtWdwActSta "Always Not_Available on an EV6 while the rear windows move; the rear window state is not on this bus.";
CM_ SG_ 1124 Window_DrvrSdWdwDetailOpnSta "Verified on an EV6 against CAN logs: driver window position, steps 0 to 3 from closed to fully open.";
CM_ SG_ 1124 Window_AsstSdWdwDetailOpnSta "Verified on an EV6 against CAN logs: passenger window position, steps 0 to 3 from closed to fully open.";
CM_ SG_ 1124 Window_DrvrSdWdwErrAntPinch "Unverified opendbc signal";
CM_ SG_ 1124 Window_RrLftWdwDetailOpnSta "Always Not_Available on an EV6 while the rear windows move; the rear window state is not on this bus.";
CM_ SG_ 1124 Window_RrRtWdwDetailOpnSta "Always Not_Available on an EV6 while the rear windows move; the rear window state is not on this bus.";
CM_ SG_ 1124 Window_AsstSdWdwErrAntPinch "Unverified opendbc signal";
CM_ SG_ 1124 Window_RrLftWdwErrAntPinch "Unverified opendbc signal";
CM_ SG_ 1124 Window_RrRtWdwErrAntPinch "Unverified opendbc signal";
CM_ SG_ 1124 SunRoof_RrBlindPosSta "Unverified opendbc signal";
CM_ BO_ 1125 "Unverified: Imported from opendbc. Validation required.";
CM_ SG_ 1125 DATC_Crc14Val "Unverified opendbc signal";
CM_ SG_ 1125 DATC_AlvCnt14Val "Unverified opendbc signal";
CM_ SG_ 1125 DATC_Beep1Sound "Unverified opendbc signal";
CM_ BO_ 1144 "Unverified: Imported from opendbc. Validation required.";
CM_ SG_ 1144 DRIVE_MODE2 "Unverified opendbc signal";
CM_ BO_ 1151 "Unverified: Imported from opendbc. Validation required.";
CM_ SG_ 1151 AUTO_BUTTON "Unverified opendbc signal";
CM_ SG_ 1151 SYNC_BUTTON "Unverified opendbc signal";
CM_ SG_ 1151 FR_DEFROST_BUTTON "Unverified opendbc signal";
CM_ SG_ 1151 RR_DEFROST_BUTTON "Unverified opendbc signal";
CM_ SG_ 1151 FAN_SPEED_UP_BUTTON "Unverified opendbc signal";
CM_ SG_ 1151 FAN_SPEED_DOWN_BUTTON "Unverified opendbc signal";
CM_ SG_ 1151 AIR_DIRECTION_BUTTON "Unverified opendbc signal";
CM_ SG_ 1151 AC_BUTTON "Unverified opendbc signal";
CM_ SG_ 1151 DRIVER_ONLY_BUTTON "Unverified opendbc signal";
CM_ SG_ 1151 RECIRC_BUTTON "Unverified opendbc signal";
CM_ SG_ 1151 HEAT_BUTTON "Unverified opendbc signal";
CM_ BO_ 1157 "Unverified: Imported from opendbc. Validation required.";
CM_ SG_ 1157 VESS_CLU_Warning "Unverified opendbc signal";
CM_ SG_ 1157 VESS_LogSnapshotState "Unverified opendbc signal";
CM_ SG_ 1157 VESS_ChgGuideMdLvlSt "Unverified opendbc signal";
CM_ SG_ 1157 VESS_SWVerMajor "Unverified opendbc signal";
CM_ SG_ 1157 VESS_SWVerMinor "Unverified opendbc signal";
CM_ BO_ 1167 "Unverified: Imported from opendbc. Validation required.";
CM_ SG_ 1167 ICU_Crc11Val "Unverified opendbc signal";
CM_ SG_ 1167 IGN_AutoOff_WarnSta "Unverified opendbc signal";
CM_ SG_ 1167 Bat_dischrg "Unverified opendbc signal";
CM_ SG_ 1167 ICU_AlvCnt11Val "Unverified opendbc signal";
CM_ SG_ 1167 Batt_SoCWarningValue "Unverified opendbc signal";
CM_ SG_ 1167 C_StrgWhlHeatingOpt "Unverified opendbc signal";
CM_ SG_ 1167 C_StrgWhlHeatingSWInf "Unverified opendbc signal";
CM_ SG_ 1167 ICU_BattAutoCutPreWrng "Unverified opendbc signal";
CM_ SG_ 1167 IGN_AutoOff_WarnSta_CLU "Unverified opendbc signal";
CM_ BO_ 1187 "Unverified: Imported from opendbc. Validation required.";
CM_ SG_ 1187 Navi_ISLW_LinkClass "Unverified opendbc signal";
CM_ SG_ 1187 Navi_ISLW_Frwinfo "Unverified opendbc signal";
CM_ SG_ 1187 Navi_ISLW_SpdUnit "Unverified opendbc signal";
CM_ SG_ 1187 Navi_ISLW_SpdLimit "Checked on an EV6 against CAN logs: the map speed limit of the current road in km/h (50, 70, 30 over log_12, changing as the car turns onto another road), 0 when unknown. Sent while driving even without a route. Not checked against signs.";
CM_ SG_ 1187 Navi_ISLW_CountryCode "Unverified opendbc signal";
CM_ SG_ 1187 Navi_ISLW_MapSource "Unverified opendbc signal";
CM_ SG_ 1187 Navi_ISLW_TollExist "Unverified opendbc signal";
CM_ SG_ 1187 Navi_ISLW_TunnelExist "Unverified opendbc signal";
CM_ SG_ 1187 Navi_ISLW_TimeSpd "Unverified opendbc signal";
CM_ BO_ 1201 "Unverified: Imported from opendbc. Validation required.";
CM_ SG_ 1201 ICU_Popup_Enable "Unverified opendbc signal";
CM_ BO_ 1204 "Unverified: Imported from opendbc. Validation required.";
CM_ SG_ 1204 POS_V2_3_Offset "Unverified opendbc signal";
CM_ SG_ 1204 POS_V2_3_PathIndex "Unverified opendbc signal";
CM_ SG_ 1204 POS_V2_3_CyclicCounter "Unverified opendbc signal";
CM_ SG_ 1204 POS_V2_3_RangeAvgSpeed "Unverified opendbc signal";
CM_ SG_ 1204 POS_V2_3_CurrAltitude100m "Unverified opendbc signal";
CM_ SG_ 1204 POS_V2_3_CurrAltitude1m "Unverified opendbc signal";
CM_ SG_ 1204 POS_V2_3_CurrFuncRoadClass "Unverified opendbc signal";
CM_ SG_ 1204 POS_V2_3_CurrFormOfWay "Unverified opendbc signal";
CM_ SG_ 1204 POS_V2_3_CurrDirectionLanes "Unverified opendbc signal";
CM_ SG_ 1204 POS_V2_3_CurrSpeedLimit "Unverified opendbc signal";
CM_ SG_ 1204 POS_V2_3_CurrTrafficSpeed "Unverified opendbc signal";
CM_ BO_ 1205 "Unverified: Imported from opendbc. Validation required.";
CM_ SG_ 1205 PATH_V2_3_CalculatedRoute "Unverified opendbc signal";
CM_ SG_ 1205 PATH_V2_3_PathType "Unverified opendbc signal";
CM_ SG_ 1205 PATH_V2_3_Value0 "Unverified opendbc signal";
CM_ SG_ 1205 PATH_V2_3_Value1 "Unverified opendbc signal";
CM_ SG_ 1205 PATH_V2_3_FuncRoadClass "Unverified opendbc signal";
CM_ SG_ 1205 PATH_V2_3_TurnAngle "Unverified opendbc signal";
CM_ SG_ 1205 PATH_V2_3_DirectionLanes "Unverified opendbc signal";
CM_ SG_ 1205 PATH_V2_3_RemainingDistance "Unverified opendbc signal";
CM_ SG_ 1205 PATH_V2_3_MeanEffectiveSlope "Unverified opendbc signal";
CM_ SG_ 1205 PATH_V2_3_CyclicCounter "Unverified opendbc signal";
CM_ BO_ 1207 "Unverified: Imported from opendbc. Validation required.";
CM_ SG_ 1207 PATH_V2_3_CalculatedRoute_01 "Unverified opendbc signal";
CM_ SG_ 1207 PATH_V2_3_PathType_01 "Unverified opendbc signal";
CM_ SG_ 1207 PATH_V2_3_Value0_01 "Unverified opendbc signal";
CM_ SG_ 1207 PATH_V2_3_Value1_01 "Unverified opendbc signal";
CM_ SG_ 1207 PATH_V2_3_FuncRoadClass_01 "Unverified opendbc signal";
CM_ SG_ 1207 PATH_V2_3_TurnAngle_01 "Unverified opendbc signal";
CM_ SG_ 1207 PATH_V2_3_DirectionLanes_01 "Unverified opendbc signal";
CM_ SG_ 1207 PATH_V2_3_RemainingDistance_01 "Unverified opendbc signal";
CM_ SG_ 1207 PATH_V2_3_MeanEffectiveSlope_01 "Unverified opendbc signal";
CM_ SG_ 1207 PATH_V2_3_CyclicCounter_01 "Unverified opendbc signal";
CM_ BO_ 1208 "Unverified: Imported from opendbc. Validation required.";
CM_ SG_ 1208 META_V2_3_MapProvider "Unverified opendbc signal";
CM_ SG_ 1208 META_V2_3_CountryCode "Unverified opendbc signal";
CM_ SG_ 1208 META_V2_3_RegionCode "Unverified opendbc signal";
CM_ SG_ 1208 META_V2_3_MajorProtocolVersion "Unverified opendbc signal";
CM_ SG_ 1208 META_V2_3_MinorProtocolVersion "Unverified opendbc signal";
CM_ SG_ 1208 META_V2_3_DrivingSide "Unverified opendbc signal";
CM_ SG_ 1208 META_V2_3_SpeedUnit "Unverified opendbc signal";
CM_ SG_ 1208 META_V2_3_Country_OptADAS "Unverified opendbc signal";
CM_ SG_ 1208 META_V2_3_CyclicCounter "Unverified opendbc signal";
CM_ BO_ 1209 "Unverified: Imported from opendbc. Validation required.";
CM_ SG_ 1209 SEG_V2_3_Offset "Unverified opendbc signal";
CM_ SG_ 1209 SEG_V2_3_PathIndex "Unverified opendbc signal";
CM_ SG_ 1209 SEG_V2_3_CalculatedRoute "Unverified opendbc signal";
CM_ SG_ 1209 SEG_V2_3_FuncRoadClass "Unverified opendbc signal";
CM_ SG_ 1209 SEG_V2_3_SpeedLimit "Unverified opendbc signal";
CM_ SG_ 1209 SEG_V2_3_FormOfWay "Unverified opendbc signal";
CM_ SG_ 1209 SEG_V2_3_DirectionLanes "Unverified opendbc signal";
CM_ SG_ 1209 SEG_V2_3_SpeedLimitUnder5 "Unverified opendbc signal";
CM_ SG_ 1209 SEG_V2_3_DividedRoad "Unverified opendbc signal";
CM_ SG_ 1209 SEG_V2_3_CyclicCounter "Unverified opendbc signal";
CM_ SG_ 1209 SEG_V2_3_Retransmission "Unverified opendbc signal";
CM_ BO_ 1210 "Unverified: Imported from opendbc. Validation required.";
CM_ SG_ 1210 PROSHORT_V2_3_Offset "Unverified opendbc signal";
CM_ SG_ 1210 PROSHORT_V2_3_PathIndex "Unverified opendbc signal";
CM_ SG_ 1210 PROSHORT_V2_3_Distance "Unverified opendbc signal";
CM_ SG_ 1210 PROSHORT_V2_3_Value0 "Unverified opendbc signal";
CM_ SG_ 1210 PROSHORT_V2_3_Value1 "Unverified opendbc signal";
CM_ SG_ 1210 PROSHORT_V2_3_ProfileType "Unverified opendbc signal";
CM_ SG_ 1210 PROSHORT_V2_3_CyclicCounter "Unverified opendbc signal";
CM_ SG_ 1210 PROSHORT_V2_3_Accuracy "Unverified opendbc signal";
CM_ BO_ 1214 "Unverified: Imported from opendbc. Validation required.";
CM_ SG_ 1214 PROLONG_V2_3_Value "Unverified opendbc signal";
CM_ SG_ 1214 PROLONG_V2_3_Offset "Unverified opendbc signal";
CM_ SG_ 1214 PROLONG_V2_3_PathIndex "Unverified opendbc signal";
CM_ SG_ 1214 PROLONG_V2_3_ProfileType "Unverified opendbc signal";
CM_ SG_ 1214 PROLONG_V2_3_CyclicCounter "Unverified opendbc signal";
CM_ SG_ 1214 PROLONG_V2_3_Update "Unverified opendbc signal";
CM_ BO_ 1215 "Unverified: Imported from opendbc. Validation required.";
CM_ SG_ 1215 STUB_V2_3_Offset "Unverified opendbc signal";
CM_ SG_ 1215 STUB_V2_3_PathIndex "Unverified opendbc signal";
CM_ SG_ 1215 STUB_V2_3_SubPathIndex "Unverified opendbc signal";
CM_ SG_ 1215 STUB_V2_3_RelativeProb "Unverified opendbc signal";
CM_ SG_ 1215 STUB_V2_3_FuncRoadClass "Unverified opendbc signal";
CM_ SG_ 1215 STUB_V2_3_CalculatedRoute "Unverified opendbc signal";
CM_ SG_ 1215 STUB_V2_3_RightOfWay "Unverified opendbc signal";
CM_ SG_ 1215 STUB_V2_3_TurnAngle "Unverified opendbc signal";
CM_ SG_ 1215 STUB_V2_3_FormOfWay "Unverified opendbc signal";
CM_ SG_ 1215 STUB_V2_3_DirectionLanes "Unverified opendbc signal";
CM_ SG_ 1215 STUB_V2_3_CyclicCounter "Unverified opendbc signal";
CM_ SG_ 1215 STUB_V2_3_LastStubAtOffset "Unverified opendbc signal";
CM_ BO_ 1224 "Unverified: Imported from opendbc. Validation required.";
CM_ SG_ 1224 HU_eCallStatus "Unverified opendbc signal";
CM_ SG_ 1224 C_SHVU_DTC_Mode "Unverified opendbc signal";
CM_ SG_ 1224 HU_TempUnit "Unverified opendbc signal";
CM_ BO_ 1239 "Unverified: Imported from opendbc. Validation required.";
CM_ SG_ 1239 HU_VehiclePwr "Unverified opendbc signal";
CM_ SG_ 1239 HU_BtnShowReq "Unverified opendbc signal";
CM_ BO_ 1240 "Unverified: Imported from opendbc. Validation required.";
CM_ SG_ 1240 DISTANCE_UNIT "Unverified opendbc signal";
CM_ BO_ 1245 "Unverified: Imported from opendbc. Validation required.";
CM_ SG_ 1245 HU_EV_GpsSched_State "Unverified opendbc signal";
CM_ SG_ 1245 HU_LatchHoldReq_EV_PE "Unverified opendbc signal";
CM_ BO_ 1247 "Unverified: Imported from opendbc. Validation required.";
CM_ SG_ 1247 Navi_AirConditionWarning "Unverified opendbc signal";
CM_ SG_ 1247 Navi_AirConditionType "Unverified opendbc signal";
CM_ BO_ 1253 "Unverified: Imported from opendbc. Validation required.";
CM_ SG_ 1253 Auth_Req "Unverified opendbc signal";
CM_ SG_ 1253 SecureCom_Req "Unverified opendbc signal";
CM_ BO_ 1257 "Unverified: Imported from opendbc. Validation required.";
CM_ SG_ 1257 CF_Tmu_RoadType2 "Unverified opendbc signal";
CM_ SG_ 1257 CF_Tmu_RoadType1 "Unverified opendbc signal";
CM_ SG_ 1257 CF_Tmu_RoadType4 "Unverified opendbc signal";
CM_ SG_ 1257 CF_Tmu_RoadType3 "Unverified opendbc signal";
CM_ SG_ 1257 CF_Tmu_RoadType5 "Unverified opendbc signal";
CM_ BO_ 1258 "Unverified: Imported from opendbc. Validation required.";
CM_ SG_ 1258 CF_Tmu_RoadType7 "Unverified opendbc signal";
CM_ SG_ 1258 CF_Tmu_RoadType6 "Unverified opendbc signal";
CM_ SG_ 1258 CF_Tmu_RoadType9 "Unverified opendbc signal";
CM_ SG_ 1258 CF_Tmu_RoadType8 "Unverified opendbc signal";
CM_ SG_ 1258 CF_Tmu_RoadType10 "Unverified opendbc signal";
CM_ BO_ 1260 "Unverified: Imported from opendbc. Validation required.";
CM_ SG_ 1260 CR_Tmu_DrvDistance1 "Unverified opendbc signal";
CM_ SG_ 1260 CR_Tmu_DrvDistance2 "Unverified opendbc signal";
CM_ SG_ 1260 CR_Tmu_DrvDistance3 "Unverified opendbc signal";
CM_ SG_ 1260 CR_Tmu_DrvDistance4 "Unverified opendbc signal";
CM_ SG_ 1260 CR_Tmu_DrvDistance5 "Unverified opendbc signal";
CM_ SG_ 1260 CR_Tmu_DrvDistance6 "Unverified opendbc signal";
CM_ BO_ 1262 "Unverified: Imported from opendbc. Validation required.";
CM_ SG_ 1262 CR_HU_EconStMin_WeedDay "Unverified opendbc signal";
CM_ SG_ 1262 CR_HU_EconStHr_WeekDay "Unverified opendbc signal";
CM_ SG_ 1262 CR_HU_EconEndMin_WeekDay "Unverified opendbc signal";
CM_ SG_ 1262 CR_HU_EconEndHr_WeekDay "Unverified opendbc signal";
CM_ SG_ 1262 CR_HU_ChgCtrMode "Unverified opendbc signal";
CM_ BO_ 1263 "Unverified: Imported from opendbc. Validation required.";
CM_ SG_ 1263 CR_HU_DepartSet1_Min "Unverified opendbc signal";
CM_ SG_ 1263 CR_HU_DepartSet1_Hour "Unverified opendbc signal";
CM_ SG_ 1263 CF_HU_DepartSet1_Enable "Unverified opendbc signal";
CM_ SG_ 1263 CF_HU_DepartSet1_Sun "Unverified opendbc signal";
CM_ SG_ 1263 CF_HU_DepartSet1_Sat "Unverified opendbc signal";
CM_ SG_ 1263 CF_HU_DepartSet1_Fri "Unverified opendbc signal";
CM_ SG_ 1263 CF_HU_DepartSet1_Thu "Unverified opendbc signal";
CM_ SG_ 1263 CF_HU_DepartSet1_Wed "Unverified opendbc signal";
CM_ SG_ 1263 CF_HU_DepartSet1_Tue "Unverified opendbc signal";
CM_ SG_ 1263 CF_HU_DepartSet1_Mon "Unverified opendbc signal";
CM_ SG_ 1263 CR_HU_DepartSet2_Min "Unverified opendbc signal";
CM_ SG_ 1263 CR_HU_DepartSet2_Hour "Unverified opendbc signal";
CM_ SG_ 1263 CF_HU_DepartSet2_Enable "Unverified opendbc signal";
CM_ SG_ 1263 CF_HU_DepartSet2_Sun "Unverified opendbc signal";
CM_ SG_ 1263 CF_HU_DepartSet2_Sat "Unverified opendbc signal";
CM_ SG_ 1263 CF_HU_DepartSet2_Fri "Unverified opendbc signal";
CM_ SG_ 1263 CF_HU_DepartSet2_Thu "Unverified opendbc signal";
CM_ SG_ 1263 CF_HU_DepartSet2_Wed "Unverified opendbc signal";
CM_ SG_ 1263 CF_HU_DepartSet2_Tue "Unverified opendbc signal";
CM_ SG_ 1263 CF_HU_DepartSet2_Mon "Unverified opendbc signal";
CM_ SG_ 1263 CF_HU_DepartSet1_TempUnit "Unverified opendbc signal";
CM_ SG_ 1263 CR_HU_DepartSet1_TempSet "Unverified opendbc signal";
CM_ SG_ 1263 CF_HU_DepartSet1_PreCondSet "Unverified opendbc signal";
CM_ SG_ 1263 CF_HU_DepartSet1_DefrostCtr "Unverified opendbc signal";
CM_ BO_ 1265 "Unverified: Imported from opendbc. Validation required.";
CM_ SG_ 1265 AMP_UpdateIGNIhn "Unverified opendbc signal";
CM_ SG_ 1265 HU_Background_Time_Info "Unverified opendbc signal";
CM_ SG_ 1265 C_FRU_Option_Info "Unverified opendbc signal";
CM_ SG_ 1265 HU_RrStRemindOffSetReq "Unverified opendbc signal";
CM_ SG_ 1265 HU_IG3_Request "Unverified opendbc signal";
CM_ SG_ 1265 HU_Background "Unverified opendbc signal";
CM_ SG_ 1265 ccIC_HUD_PbackSta "Unverified opendbc signal";
CM_ SG_ 1265 HU_BackgroundFadeInOut "Unverified opendbc signal";
CM_ BO_ 1266 "Unverified: Imported from opendbc. Validation required.";
CM_ SG_ 1266 HU_LanguageInfo "Unverified opendbc signal";
CM_ SG_ 1266 HU_VolumeStatus "Unverified opendbc signal";
CM_ SG_ 1266 HU_MuteStatus "Unverified opendbc signal";
CM_ SG_ 1266 HU_WelcomeReady "Unverified opendbc signal";
CM_ SG_ 1266 HU_UsmSupport "Unverified opendbc signal";
CM_ SG_ 1266 HU_NaviStatus "Unverified opendbc signal";
CM_ SG_ 1266 HU_BVM_Display_Message "Unverified opendbc signal";
CM_ SG_ 1266 HU_SVM_View_Display "Unverified opendbc signal";
CM_ SG_ 1266 HU_NaviCamSettingStatus "Unverified opendbc signal";
CM_ SG_ 1266 HU_EVSupport "Unverified opendbc signal";
CM_ SG_ 1266 HU_AutoBrightState_New "Unverified opendbc signal";
CM_ BO_ 1267 "Unverified: Imported from opendbc. Validation required.";
CM_ SG_ 1267 RSELockOnOff_PE "Unverified opendbc signal";
CM_ SG_ 1267 HU_DATC_DisplayThemes "Unverified opendbc signal";
CM_ SG_ 1267 DATC_AlvCnt8Val "Unverified opendbc signal";
CM_ SG_ 1267 DATC_SmrtVntOnOffSta "Unverified opendbc signal";
CM_ SG_ 1267 DATC_PsAutoDis "Unverified opendbc signal";
CM_ SG_ 1267 DATC_RrAutoDis "Unverified opendbc signal";
CM_ SG_ 1267 HU_PhoneActivity_PE "Unverified opendbc signal";
CM_ SG_ 1267 HU_VRActivity_PE "Unverified opendbc signal";
CM_ SG_ 1267 DATC_RrDrvModDis "Unverified opendbc signal";
CM_ SG_ 1267 DATC_DisplayThemes "Unverified opendbc signal";
CM_ SG_ 1267 DATC_AUTOStepPS "Unverified opendbc signal";
CM_ SG_ 1267 DATC_AUTOStepRR "Unverified opendbc signal";
CM_ BO_ 1278 "Unverified: Imported from opendbc. Validation required.";
CM_ SG_ 1278 HU_Type "Unverified opendbc signal";
CM_ SG_ 1278 HU_Navi_RspADASMapMsg "Unverified opendbc signal";
CM_ SG_ 1278 HU_DistributeInfo "Unverified opendbc signal";
CM_ SG_ 1278 HU_OptionInfo "Unverified opendbc signal";
CM_ SG_ 1278 HU_NaviHandshakingSupport "Unverified opendbc signal";
CM_ SG_ 1278 HU_AMP_EQVariant "Unverified opendbc signal";
CM_ SG_ 1278 HU_AdasSupport "Unverified opendbc signal";
CM_ BO_ 1584 "Unverified: Imported from opendbc. Validation required.";
CM_ SG_ 1584 AMP_RrTTSSound "Unverified opendbc signal";
CM_ SG_ 1584 AMP_NaviSound "Unverified opendbc signal";
CM_ SG_ 1584 AMP_TTSSound "Unverified opendbc signal";
CM_ SG_ 1584 AMP_SDVCStep "Unverified opendbc signal";
CM_ SG_ 1584 AMP_Beep1Mode "Unverified opendbc signal";
CM_ SG_ 1584 AMP_MasterBeepVolumeStep "Unverified opendbc signal";
CM_ SG_ 1584 AMP_SignalDoctor "Unverified opendbc signal";
CM_ SG_ 1584 AMP_ASDMode "Unverified opendbc signal";
CM_ SG_ 1584 AMP_ANCMode "Unverified opendbc signal";
CM_ SG_ 1584 AMP_VirtualVenueMode "Unverified opendbc signal";
CM_ SG_ 1584 AMP_QLIMode "Unverified opendbc signal";
CM_ SG_ 1584 AMP_DriverMode "Unverified opendbc signal";
CM_ SG_ 1584 AMP_VoiceGuideTTS "Unverified opendbc signal";
CM_ SG_ 1584 AMP_Beep1KBDMode "Unverified opendbc signal";
CM_ BO_ 1585 "Unverified: Imported from opendbc. Validation required.";
CM_ SG_ 1585 AMP_Mute "Unverified opendbc signal";
CM_ SG_ 1585 AMP_AudioMode "Unverified opendbc signal";
CM_ SG_ 1585 AMP_WrnPromptMode "Unverified opendbc signal";
CM_ SG_ 1585 AMP_SPDIFMute "Unverified opendbc signal";
CM_ SG_ 1585 AMP_Reset "Unverified opendbc signal";
CM_ SG_ 1585 AMP_QuietMode "Unverified opendbc signal";
CM_ SG_ 1585 AMP_DSCMode "Unverified opendbc signal";
CM_ SG_ 1585 AMP_RANCMode "Unverified opendbc signal";
CM_ SG_ 1585 AMP_CenterpointMode "Unverified opendbc signal";
CM_ SG_ 1585 AMP_QLSMode "Unverified opendbc signal";
CM_ SG_ 1585 AMP_SiriMode "Unverified opendbc signal";
CM_ BO_ 1586 "Unverified: Imported from opendbc. Validation required.";
CM_ SG_ 1586 AMP_LogSnapshot "Unverified opendbc signal";
CM_ SG_ 1586 VESS_LogSnapshot "Unverified opendbc signal";
CM_ SG_ 1586 AMP_VersionReq "Unverified opendbc signal";
CM_ BO_ 1587 "Unverified: Imported from opendbc. Validation required.";
CM_ SG_ 1587 AMP_EngASDMasterGain "Unverified opendbc signal";
CM_ SG_ 1587 AMP_Beep1Frequency "Unverified opendbc signal";
CM_ BO_ 1588 "Unverified: Imported from opendbc. Validation required.";
CM_ SG_ 1588 AMP_NaviVolumeStep "Unverified opendbc signal";
CM_ SG_ 1588 ATS_Beep_OutputCh_Select "Unverified opendbc signal";
CM_ SG_ 1588 ATS_BeepVolumeStep "Unverified opendbc signal";
CM_ SG_ 1588 ATS_BeepFrequency "Unverified opendbc signal";
CM_ SG_ 1588 AMP_ESEVMasterGain "Unverified opendbc signal";
CM_ SG_ 1588 AMP_NaviVoice_Priority "Unverified opendbc signal";
CM_ SG_ 1588 AMP_ESEVMode "Unverified opendbc signal";
CM_ BO_ 1589 "Unverified: Imported from opendbc. Validation required.";
CM_ SG_ 1589 AMP_MTSVolumeStep "Unverified opendbc signal";
CM_ SG_ 1589 AMP_eASDMode "Unverified opendbc signal";
CM_ SG_ 1589 AMP_eASDCstVolumeSet "Unverified opendbc signal";
CM_ SG_ 1589 AMP_eASDAPSSet "Unverified opendbc signal";
CM_ SG_ 1589 AMP_eASDCstMode "Unverified opendbc signal";
CM_ SG_ 1589 AMP_eASDCstReset "Unverified opendbc signal";
CM_ BO_ 1590 "Unverified: Imported from opendbc. Validation required.";
CM_ SG_ 1590 AMP_HFVolumeStep "Unverified opendbc signal";
CM_ SG_ 1590 DVRS_Beep_OutputCh_Select "Unverified opendbc signal";
CM_ SG_ 1590 DVRS_BeepVolumeStep "Unverified opendbc signal";
CM_ SG_ 1590 DVRS_BeepFrequency "Unverified opendbc signal";
CM_ SG_ 1590 AMP_SiriVolumeStep "Unverified opendbc signal";
CM_ BO_ 1591 "Unverified: Imported from opendbc. Validation required.";
CM_ SG_ 1591 AMP_MainVolumeSet "Unverified opendbc signal";
CM_ SG_ 1591 AMP_BalanceSet "Unverified opendbc signal";
CM_ SG_ 1591 AMP_FadeSet "Unverified opendbc signal";
CM_ SG_ 1591 AMP_BassSet "Unverified opendbc signal";
CM_ SG_ 1591 AMP_MidSet "Unverified opendbc signal";
CM_ SG_ 1591 AMP_TrebleSet "Unverified opendbc signal";
CM_ BO_ 1593 "Unverified: Imported from opendbc. Validation required.";
CM_ SG_ 1593 DATC_Beep1_OutputCh_Select "Unverified opendbc signal";
CM_ SG_ 1593 DATC_Beep1VolumeStep "Unverified opendbc signal";
CM_ SG_ 1593 DATC_Beep1Frequency "Unverified opendbc signal";
CM_ BO_ 1597 "Unverified: Imported from opendbc. Validation required.";
CM_ SG_ 1597 AMP_SetMaxMainVolStep "Unverified opendbc signal";
BA_DEF_ BO_ "GenMsgBackgroundColor" STRING ;
BA_DEF_ BO_ "GenMsgForegroundColor" STRING ;
BA_DEF_DEF_ "GenMsgBackgroundColor" "#1e1e1e";
BA_DEF_DEF_ "GenMsgForegroundColor" "#dcdcdc";
VAL_ 685 Battery_Precond_State 21 "On" 5 "Preparing" 1 "Off";
VAL_ 100 Auto_Hold 48 "On" 4 "Off";
VAL_ 1077 Power_State 255 "Car_Off" 0 "Car_on";
VAL_ 843 Headlight_Switch 3 "Off" 2 "Parking" 1 "Auto" 0 "Low_Beam";
VAL_ 896 Driver_Temp_C 0 "OFF";
VAL_ 896 Passenger_Temp_C 0 "OFF";
VAL_ 938 Port_Open 2 "Closed" 1 "Open";
VAL_ 1124 Window_DrvrSdWdwDetailOpnSta 7 "Not_Available" 3 "Fully_Open" 2 "Partly_Open" 1 "Slightly_Open" 0 "Closed";
VAL_ 1124 Window_DrvrSdWdwActSta 15 "Not_Available" 6 "Auto_Up" 5 "Auto_Down" 2 "Manual_Up" 1 "Manual_Down" 0 "Idle";
VAL_ 1124 Window_AsstSdWdwDetailOpnSta 7 "Not_Available" 3 "Fully_Open" 2 "Partly_Open" 1 "Slightly_Open" 0 "Closed";
VAL_ 1124 Window_AsstSdWdwActSta 15 "Not_Available" 6 "Auto_Up" 5 "Auto_Down" 2 "Manual_Up" 1 "Manual_Down" 0 "Idle";
VAL_ 1124 Window_RrLftWdwDetailOpnSta 7 "Not_Available" 3 "Fully_Open" 2 "Partly_Open" 1 "Slightly_Open" 0 "Closed";
VAL_ 1124 Window_RrLftWdwActSta 15 "Not_Available" 6 "Auto_Up" 5 "Auto_Down" 2 "Manual_Up" 1 "Manual_Down" 0 "Idle";
VAL_ 1124 Window_RrRtWdwDetailOpnSta 7 "Not_Available" 3 "Fully_Open" 2 "Partly_Open" 1 "Slightly_Open" 0 "Closed";
VAL_ 1124 Window_RrRtWdwActSta 15 "Not_Available" 6 "Auto_Up" 5 "Auto_Down" 2 "Manual_Up" 1 "Manual_Down" 0 "Idle";
VAL_ 413 Charger_Type 2 "DC" 1 "AC" 0 "None";
VAL_ 54 Gear 7 "Reverse" 6 "Neutral" 5 "Drive" 0 "Park";
VAL_ 54 Drive_Mode 5 "Snow" 2 "Sport" 1 "Normal" 0 "Eco";
VAL_ 1048 HSWS_SysWrngSta_ICU 4 "On" 0 "Off";
VAL_ 899 DATC_OpSta 2 "Off" 1 "On" 0 "Not_Available";
VAL_ 899 DATC_FrDfgSta 1 "On" 0 "Off";
VAL_ 795 Climate_Airflow_Direction 5 "Windshield" 4 "Feet_And_Windshield" 3 "Feet" 2 "Body_And_Feet" 1 "Body" 0 "Auto";
VAL_ 1174 Driver_Seat_Heating_Oper 8 "Level_3" 7 "Level_2" 6 "Level_1" 2 "Off";
VAL_ 1141 Passenger_Seat_Heating_Oper 8 "Level_3" 7 "Level_2" 6 "Level_1" 2 "Off";
VAL_ 550 Outdoor_Temperature 255 "Not_Available";
VAL_ 551 Outdoor_Temperature_F 255 "Not_Available";
VAL_ 898 DATC_TempDispUnitSta 1 "Fahrenheit" 0 "Celsius";
VAL_ 427 Distance_Unit 1 "Miles" 0 "Kilometers";
VAL_ 738 Regen_Level 126 "Not_Available";
VAL_ 929 Tire_Pressure_FL 255 "Not_Available";
VAL_ 929 Tire_Pressure_FR 255 "Not_Available";
VAL_ 929 Tire_Pressure_RL 255 "Not_Available";
VAL_ 929 Tire_Pressure_RR 255 "Not_Available";
VAL_ 764 Aux_Battery_Voltage 0 "Not_Available";
VAL_ 1230 Media_Source 20 "Off" 222 "Android_Auto";
VAL_ 418 Cruise_State 0 "Not_Engaged" 2 "Engaged";
VAL_ 992 BAlarm_BglrAlrmSta 0 "Disarmed" 1 "Armed";
VAL_ 56 Power_Mode 1 "Off" 4 "Ready";
VAL_ 1256 Distance_Unit 0 "m" 1 "km" 2 "mi" 3 "ft" 4 "yd" 15 "Not_Available";
VAL_ 1256 ETA_Hours 255 "Not_Available";
VAL_ 1256 Destination_Flag 0 "Destination" 1 "Waypoint_1" 2 "Waypoint_2" 3 "Waypoint_3" 4 "Waypoint_4" 15 "None";
VAL_ 199 NAVI_precond_EVStationFlag 0 "Cancel" 1 "Destination" 2 "EV_Station" 7 "No_Request";
VAL_ 1259 Weekday 64 "Monday" 32 "Tuesday" 16 "Wednesday" 8 "Thursday" 4 "Friday" 2 "Saturday" 1 "Sunday";
VAL_ 930 Tire_Pressure_Unit 2 "Bar" 1 "Kpa" 0 "Psi";
VAL_ 1264 Clock_Format 2 "Hours_24" 1 "Hours_12";
VAL_ 1138 Efficiency_Unit 2 "Kwh_Per_100_Km" 1 "Km_Per_Kwh" 0 "Mi_Per_Kwh";
